VERSION ""

NS_ :

BS_:

BU_: AC_KanBox DRS_MM5_10 NotUsed HYS_EX ABS_M5 DDU10 BCM BSM CDCM DCTM DIAG_TEST ECM IONM IPC ORC RFHM TBM

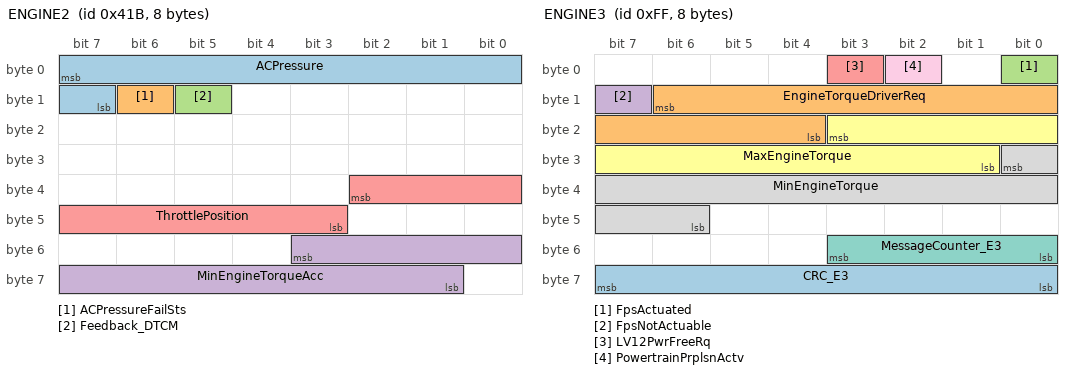
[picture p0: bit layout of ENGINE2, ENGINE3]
BO_ 1051 ENGINE2: 8 ECM
 SG_ ACPressure : 7|9@0+ (0.1,0) [0|40] "bar"  BCM
 SG_ ACPressureFailSts : 14|1@0+ (1,0) [0|1] "-"  BCM
 SG_ Feedback_DTCM : 13|1@0+ (1,0) [0|1] "-" Vector__XXX
 SG_ MinEngineTorqueAcc : 51|11@0+ (1,-500) [-500|1546] "Nm" Vector__XXX
 SG_ ThrottlePosition : 34|8@0+ (0.392,0) [0|99.96] "%"  ORC

BO_ 255 ENGINE3: 8 ECM
 SG_ CRC_E3 : 63|8@0+ (1,0) [0|255] ""  BCM,BSM,CDCM,DCTM
 SG_ EngineTorqueDriverReq : 14|11@0+ (1,-500) [-500|1546] "Nm"  BSM,CDCM,DCTM,ORC
 SG_ FpsActuated : 0|1@0+ (1,0) [0|1] ""  BCM,IPC
 SG_ FpsNotActuable : 15|1@0+ (1,0) [0|1] "-"  BCM
 SG_ LV12PwrFreeRq : 3|1@0+ (1,0) [0|1] ""  DCTM
 SG_ MaxEngineTorque : 19|11@0+ (1,-500) [-500|1546] "Nm"  CDCM,DCTM
 SG_ MessageCounter_E3 : 51|4@0+ (1,0) [0|15] ""  BCM,BSM,CDCM,DCTM
 SG_ MinEngineTorque : 24|11@0+ (1,-500) [-500|1546] "Nm"  DCTM
 SG_ PowertrainPrplsnActv : 2|1@0+ (1,0) [0|1] "-"  BCM,DCTM

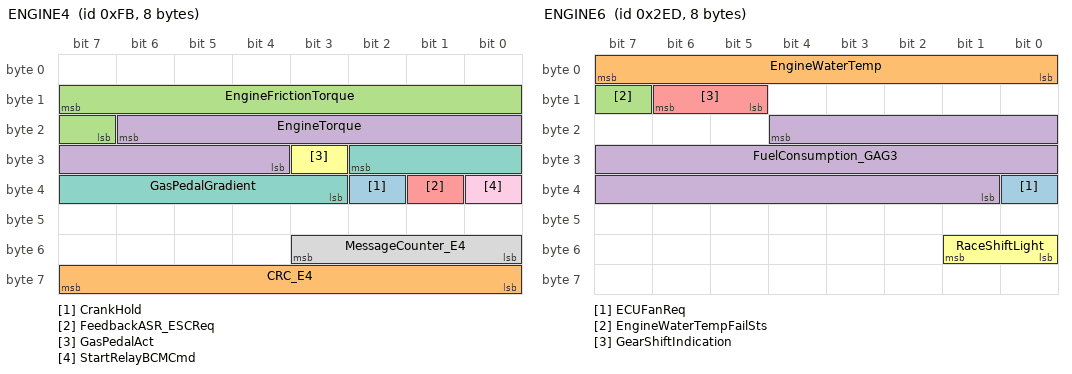
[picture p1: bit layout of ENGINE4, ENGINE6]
BO_ 251 ENGINE4: 8 ECM
 SG_ CrankHold : 34|1@0+ (1,0) [0|1] "-"  BCM,BSM
 SG_ CRC_E4 : 63|8@0+ (1,0) [0|255] ""  BCM,BSM,CDCM,DCTM
 SG_ EngineFrictionTorque : 15|9@0+ (1,0) [0|510] "Nm"  BSM,CDCM,DCTM
 SG_ EngineTorque : 22|11@0+ (1,-500) [-500|1546] "Nm"  BSM,CDCM,DCTM,IPC,ORC,TBM
 SG_ FeedbackASR_ESCReq : 33|1@0+ (1,0) [0|1] "-"  BSM
 SG_ GasPedalAct : 27|1@0+ (1,0) [0|1] "-"  BSM
 SG_ GasPedalGradient : 26|8@0+ (0.195,-25) [-25|24.53] "%/10ms"  CDCM,DCTM
 SG_ MessageCounter_E4 : 51|4@0+ (1,0) [0|15] ""  BCM,BSM,CDCM,DCTM
 SG_ StartRelayBCMCmd : 32|1@0+ (1,0) [0|1] "-"  BCM

BO_ 496 ENGINE5: 8 ECM
 SG_ ActualPedalPos : 4|8@0+ (0.4,0) [0|100] "%"  ORC

BO_ 749 ENGINE6: 8 ECM
 SG_ ECUFanReq : 32|1@1+ (1,0) [0|1] "" Vector__XXX
 SG_ EngineWaterTemp : 7|8@0+ (1,-40) [-40|215] "°C"  BCM,DCTM,IPC,TBM
 SG_ EngineWaterTempFailSts : 15|1@0+ (1,0) [0|1] "-"  BCM,DCTM,IPC,TBM
 SG_ FuelConsumption_GAG3 : 20|20@0+ (0.0022,0) [0|2306.8628] "litres/hour"  BCM,CDCM,IPC,TBM
 SG_ GearShiftIndication : 14|2@0+ (1,0) [0|3] "-"  BCM,CDCM,IPC
 SG_ RaceShiftLight : 49|2@0+ (1,0) [0|3] "-"  IPC

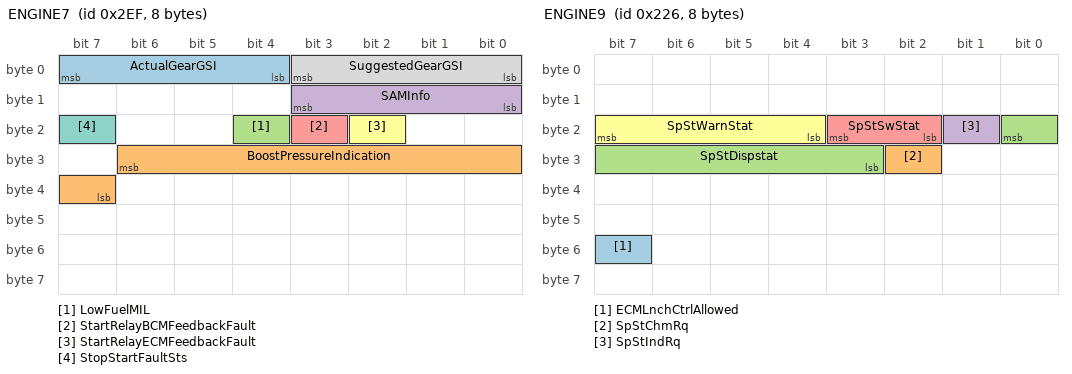
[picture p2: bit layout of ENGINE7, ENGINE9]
BO_ 751 ENGINE7: 8 ECM
 SG_ ActualGearGSI : 7|4@0+ (1,0) [0|15] "-"  CDCM,IPC,ORC
 SG_ BoostPressureIndication : 30|8@0+ (15,0) [0|3825] "mbar"  DDU10,IPC,TBM
 SG_ LowFuelMIL : 20|1@0+ (1,0) [0|1] "" Vector__XXX
 SG_ SAMInfo : 11|4@0+ (1,0) [0|14] "-" Vector__XXX
 SG_ StartRelayBCMFeedbackFault : 19|1@0+ (1,0) [0|1] "-"  BCM
 SG_ StartRelayECMFeedbackFault : 18|1@0+ (1,0) [0|1] "-"  BCM,ORC
 SG_ StopStartFaultSts : 23|1@0+ (1,0) [0|1] "-" Vector__XXX
 SG_ SuggestedGearGSI : 3|4@0+ (1,0) [0|15] "-"  CDCM,IPC

BO_ 550 ENGINE9: 8 ECM
 SG_ ECMLnchCtrlAllowed : 55|1@0+ (1,0) [0|1] ""  DCTM
 SG_ SpStChmRq : 26|1@0+ (1,0) [0|1] "-"  IPC
 SG_ SpStDispstat : 16|6@0+ (1,0) [0|63] "-"  BCM,IPC,TBM
 SG_ SpStIndRq : 17|1@0+ (1,0) [0|1] "-" Vector__XXX
 SG_ SpStSwStat : 19|2@0+ (1,0) [0|3] "-"  BCM,TBM
 SG_ SpStWarnStat : 23|4@0+ (1,0) [0|15] "-"  BCM,IPC

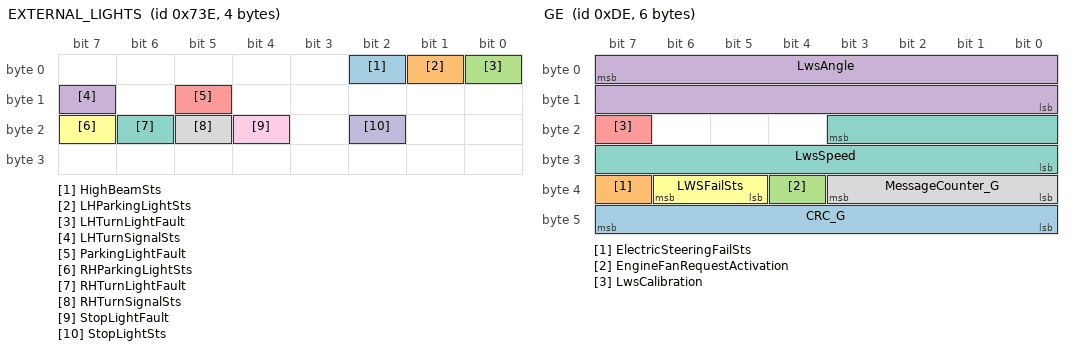
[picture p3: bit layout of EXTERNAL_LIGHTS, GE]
BO_ 1854 EXTERNAL_LIGHTS: 4 NotUsed
 SG_ HighBeamSts : 2|1@0+ (1,0) [0|1] "-"  ORC,TBM
 SG_ LHParkingLightSts : 1|1@0+ (1,0) [0|1] "-"  ORC
 SG_ LHTurnLightFault : 0|1@0+ (1,0) [0|1] "-"  ORC,TBM
 SG_ LHTurnSignalSts : 15|1@0+ (1,0) [0|1] "-"  ORC
 SG_ ParkingLightFault : 13|1@0+ (1,0) [0|1] "-"  ORC
 SG_ RHParkingLightSts : 23|1@0+ (1,0) [0|1] "-"  ORC
 SG_ RHTurnLightFault : 22|1@0+ (1,0) [0|1] "-"  ORC,TBM
 SG_ RHTurnSignalSts : 21|1@0+ (1,0) [0|1] "-"  ORC
 SG_ StopLightFault : 20|1@0+ (1,0) [0|1] "-"  ORC,TBM
 SG_ StopLightSts : 18|1@0+ (1,0) [0|1] "-"  ORC

BO_ 222 GE: 6 DDU10
 SG_ CRC_G : 47|8@0+ (1,0) [0|255] "-"  DCTM
 SG_ ElectricSteeringFailSts : 39|1@0+ (1,0) [0|1] ""  BCM,IPC
 SG_ EngineFanRequestActivation : 36|1@0+ (1,0) [0|1] ""  ECM
 SG_ LwsAngle : 7|16@0+ (0.1,-720) [-720|720] "°"  DCTM,ECM,TBM
 SG_ LwsCalibration : 23|1@0+ (1,0) [0|1] "-"  TBM
 SG_ LWSFailSts : 38|2@0+ (1,0) [0|3] "-"  DCTM
 SG_ LwsSpeed : 19|12@0+ (1,-2000) [-2000|2094] "°/s"  ECM
 SG_ MessageCounter_G : 35|4@0+ (1,0) [0|15] "1"  DCTM

BO_ 2147565809 HP_DIAGNOSTIC_REQUEST_BCM: 8 DIAG_TEST
 SG_ N_PDU : 7|64@0+ (1,0) [0|0] ""  BCM

BO_ 2147553521 HP_DIAGNOSTIC_REQUEST_ECM: 8 DIAG_TEST
 SG_ N_PDU : 7|64@0+ (1,0) [0|0] ""  ECM

BO_ 2147574001 HP_DIAGNOSTIC_REQUEST_IPC: 8 DIAG_TEST
 SG_ N_PDU : 7|64@0+ (1,0) [0|0] "-"  IPC

BO_ 2147600369 HP_DIAGNOSTIC_REQUEST_RFHM: 8 DIAG_TEST
 SG_ N_PDU : 7|64@0+ (1,0) [0|0] ""  RFHM

BO_ 2147600113 HP_DIAGNOSTIC_REQUEST_TBM: 8 DIAG_TEST
 SG_ N_PDU : 7|64@0+ (1,0) [0|0] ""  TBM

BO_ 2147555569 HP_DIAGNOSTIC_REQUEST_TRANS: 8 DIAG_TEST
 SG_ N_PDU : 7|64@0+ (1,0) [0|0] ""  DCTM

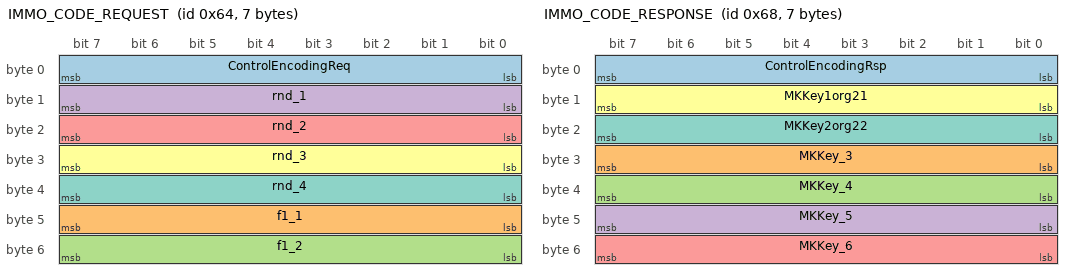
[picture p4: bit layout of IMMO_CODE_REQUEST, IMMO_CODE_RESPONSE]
BO_ 100 IMMO_CODE_REQUEST: 7 ECM
 SG_ ControlEncodingReq : 7|8@0+ (1,0) [0|255] "-"  BCM
 SG_ f1_1 : 47|8@0+ (1,0) [0|255] "-"  BCM
 SG_ f1_2 : 55|8@0+ (1,0) [0|255] "-"  BCM
 SG_ rnd_1 : 15|8@0+ (1,0) [0|255] "-"  BCM
 SG_ rnd_2 : 23|8@0+ (1,0) [0|255] "-"  BCM
 SG_ rnd_3 : 31|8@0+ (1,0) [0|255] "-"  BCM
 SG_ rnd_4 : 39|8@0+ (1,0) [0|255] "-"  BCM

BO_ 104 IMMO_CODE_RESPONSE: 7 BCM
 SG_ ControlEncodingRsp : 7|8@0+ (1,0) [0|255] "-"  ECM
 SG_ MKKey_3 : 31|8@0+ (1,0) [0|255] "-"  ECM
 SG_ MKKey_4 : 39|8@0+ (1,0) [0|255] "-"  ECM
 SG_ MKKey_5 : 47|8@0+ (1,0) [0|255] "-"  ECM
 SG_ MKKey_6 : 55|8@0+ (1,0) [0|255] "-"  ECM
 SG_ MKKey1org21 : 15|8@0+ (1,0) [0|255] "-"  ECM
 SG_ MKKey2org22 : 23|8@0+ (1,0) [0|255] "-"  ECM

BO_ 346 IMPACT_INFO: 4 ORC
 SG_ CRC_II : 31|8@0+ (1,0) [0|255] ""  BCM,TBM
 SG_ IMPACT_A : 4|1@0+ (1,0) [0|1] ""  TBM
 SG_ IMPACT_B : 3|1@0+ (1,0) [0|1] ""  TBM
 SG_ IMPACT_C : 2|1@0+ (1,0) [0|1] ""  TBM
 SG_ IMPACT_D : 1|1@0+ (1,0) [0|1] ""  TBM
 SG_ IMPACT_E : 0|1@0+ (1,0) [0|1] ""  TBM
 SG_ IMPACT_F : 15|1@0+ (1,0) [0|1] ""  TBM
 SG_ IMPACT_G : 14|1@0+ (1,0) [0|1] ""  TBM
 SG_ IMPACT_H : 13|1@0+ (1,0) [0|1] ""  TBM
 SG_ IMPACT_I : 12|1@0+ (1,0) [0|1] ""  TBM
 SG_ IMPACT_K : 11|1@0+ (1,0) [0|1] ""  TBM
 SG_ IMPACT_L : 10|1@0+ (1,0) [0|1] ""  TBM
 SG_ IMPACT_M : 9|1@0+ (1,0) [0|1] ""  TBM
 SG_ IMPACT_O : 8|1@0+ (1,0) [0|1] ""  TBM
 SG_ IMPACTCommand : 6|1@0+ (1,0) [0|1] ""  BCM,ECM
 SG_ IMPACTConfirm : 7|1@0+ (1,0) [0|1] ""  BCM,ECM,TBM
 SG_ IMPACTFailSts : 5|1@0+ (1,0) [0|1] ""  BCM
 SG_ MessageCounter_II : 19|4@0+ (1,0) [0|15] ""  BCM

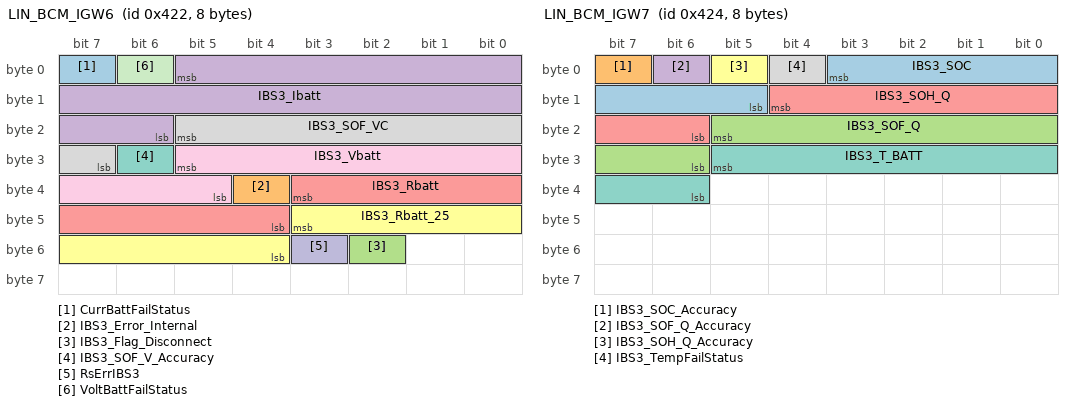
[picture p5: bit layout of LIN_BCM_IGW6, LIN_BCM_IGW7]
BO_ 1058 LIN_BCM_IGW6: 8 DDU10
 SG_ CurrBattFailStatus : 7|1@0+ (1,0) [0|1] "-"  ECM
 SG_ IBS3_Error_Internal : 36|1@0+ (1,0) [0|1] "-"  ECM
 SG_ IBS3_Flag_Disconnect : 50|1@0+ (1,0) [0|1] "-"  ECM
 SG_ IBS3_Ibatt : 5|16@0+ (0.02,-1000) [-1000|310.7] "A"  ECM,TBM
 SG_ IBS3_Rbatt : 35|8@0+ (0.1,0) [0|25.5] "mOhm" Vector__XXX
 SG_ IBS3_Rbatt_25 : 43|8@0+ (0.1,0) [0|25.5] "mOhm" Vector__XXX
 SG_ IBS3_SOF_V_Accuracy : 30|1@0+ (1,0) [0|1] "-"  ECM,IPC
 SG_ IBS3_SOF_VC : 21|7@0+ (0.05,5) [5|11.35] "V"  ECM
 SG_ IBS3_Vbatt : 29|9@0+ (0.025,5) [5|17.775] "V"  ECM,ORC,TBM
 SG_ RsErrIBS3 : 51|1@0+ (1,0) [0|1] "-"  ECM
 SG_ VoltBattFailStatus : 6|1@0+ (1,0) [0|1] "-"  ECM

BO_ 1060 LIN_BCM_IGW7: 8 DDU10
 SG_ IBS3_SOC : 3|7@0+ (1,0) [0|127] "%"  ECM,IPC,ORC,TBM
 SG_ IBS3_SOC_Accuracy : 7|1@0+ (1,0) [0|1] "-"  ECM,IPC,TBM
 SG_ IBS3_SOF_Q : 21|8@0+ (1,0) [0|255] "Ah"  ECM
 SG_ IBS3_SOF_Q_Accuracy : 6|1@0+ (1,0) [0|1] "-"  ECM
 SG_ IBS3_SOH_Q : 12|7@0+ (2,0) [0|254] "Ah"  ECM
 SG_ IBS3_SOH_Q_Accuracy : 5|1@0+ (1,0) [0|1] "-"  ECM
 SG_ IBS3_T_BATT : 29|8@0+ (1,-40) [-40|215] "°C"  ECM
 SG_ IBS3_TempFailStatus : 4|1@0+ (1,0) [0|1] "-"  ECM

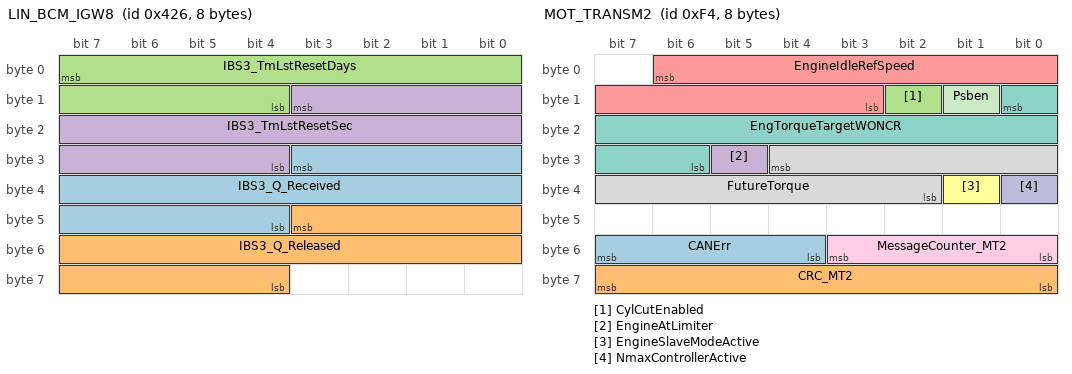
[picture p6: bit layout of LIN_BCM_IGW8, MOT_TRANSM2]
BO_ 1062 LIN_BCM_IGW8: 8 BCM
 SG_ IBS3_Q_Received : 27|16@0+ (0.125,0) [0|8191] "Ah" Vector__XXX
 SG_ IBS3_Q_Released : 43|16@0+ (0.125,0) [0|8191] "Ah" Vector__XXX
 SG_ IBS3_TmLstResetDays : 7|12@0+ (1,0) [0|4094] "Days" Vector__XXX
 SG_ IBS3_TmLstResetSec : 11|16@0+ (2,0) [0|131068] "sec" Vector__XXX

BO_ 256 MOT_TRANSM1: 8 ECM
 SG_ CRC_MT1 : 63|8@0+ (1,0) [0|255] ""  DCTM
 SG_ ECM_LHOM : 7|1@0+ (1,0) [0|1] "-"  DCTM
 SG_ Message_Counter_MT1 : 51|4@0+ (1,0) [0|15] ""  DCTM

BO_ 244 MOT_TRANSM2: 8 ECM
 SG_ CANErr : 55|4@0+ (1,0) [0|15] "-"  DCTM
 SG_ CRC_MT2 : 63|8@0+ (1,0) [0|255] ""  DCTM
 SG_ CylCutEnabled : 10|1@0+ (1,0) [0|1] ""  DCTM
 SG_ EngineAtLimiter : 29|1@0+ (1,0) [0|1] ""  DCTM
 SG_ EngineIdleRefSpeed : 6|12@0+ (1,0) [0|4094] "1/min"  DCTM
 SG_ EngineSlaveModeActive : 33|1@0+ (1,0) [0|1] ""  DCTM
 SG_ EngTorqueTargetWONCR : 8|11@0+ (1,-500) [-500|1546] "Nm"  DCTM
 SG_ FutureTorque : 28|11@0+ (1,-500) [-500|1546] "Nm"  DCTM
 SG_ MessageCounter_MT2 : 51|4@0+ (1,0) [0|15] ""  DCTM
 SG_ NmaxControllerActive : 32|1@0+ (1,0) [0|1] ""  DCTM
 SG_ Psben : 9|1@0+ (1,0) [0|1] "-" Vector__XXX

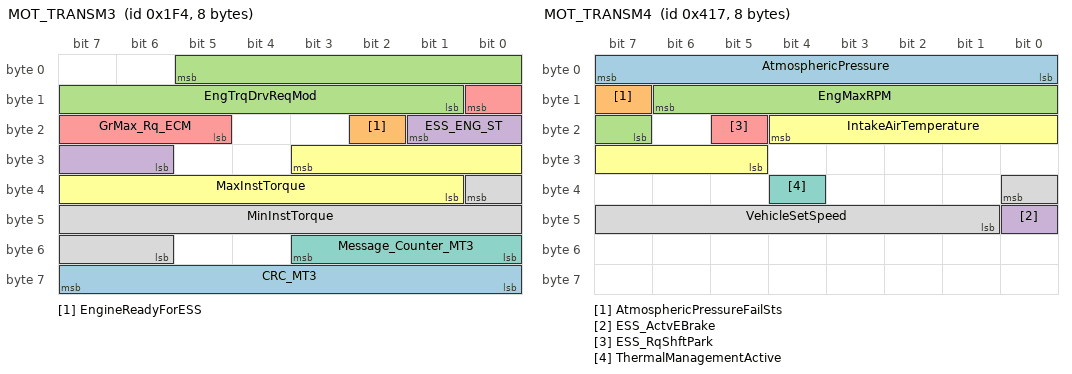
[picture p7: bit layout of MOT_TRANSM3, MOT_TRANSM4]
BO_ 500 MOT_TRANSM3: 8 ECM
 SG_ CRC_MT3 : 63|8@0+ (1,0) [0|255] ""  BCM,BSM,DCTM
 SG_ EngineReadyForESS : 18|1@0+ (1,0) [0|1] "-"  BSM,DCTM
 SG_ EngTrqDrvReqMod : 5|13@0+ (0.25,-500) [-500|1547.5] "Nm"  DCTM
 SG_ ESS_ENG_ST : 17|4@0+ (1,0) [0|15] "-"  BCM,BSM,CDCM,DCTM,ORC,TBM
 SG_ GrMax_Rq_ECM : 8|4@0+ (1,0) [0|15] "-"  DCTM
 SG_ MaxInstTorque : 27|11@0+ (1,-500) [-500|1546] "Nm"  DCTM
 SG_ Message_Counter_MT3 : 51|4@0+ (1,0) [0|15] ""  BCM,BSM,DCTM
 SG_ MinInstTorque : 32|11@0+ (1,-500) [-500|1546] "Nm"  DCTM

BO_ 1047 MOT_TRANSM4: 8 ECM
 SG_ AtmosphericPressure : 7|8@0+ (3.6,300) [300|1214.4] "mbar"  DCTM,ORC,RFHM
 SG_ AtmosphericPressureFailSts : 15|1@0+ (1,0) [0|1] "-"  DCTM,RFHM
 SG_ EngMaxRPM : 14|8@0+ (50,0) [0|10000] "-"  DCTM
 SG_ ESS_ActvEBrake : 40|1@0+ (1,0) [0|1] "-"  BSM
 SG_ ESS_RqShftPark : 21|1@0+ (1,0) [0|1] ""  DCTM
 SG_ IntakeAirTemperature : 20|8@0+ (1,-40) [-40|214] "C"  TBM
 SG_ ThermalManagementActive : 36|1@0+ (1,0) [0|1] "-"  DCTM
 SG_ VehicleSetSpeed : 32|8@0+ (1,0) [0|250] "km/h(mph)"  DCTM

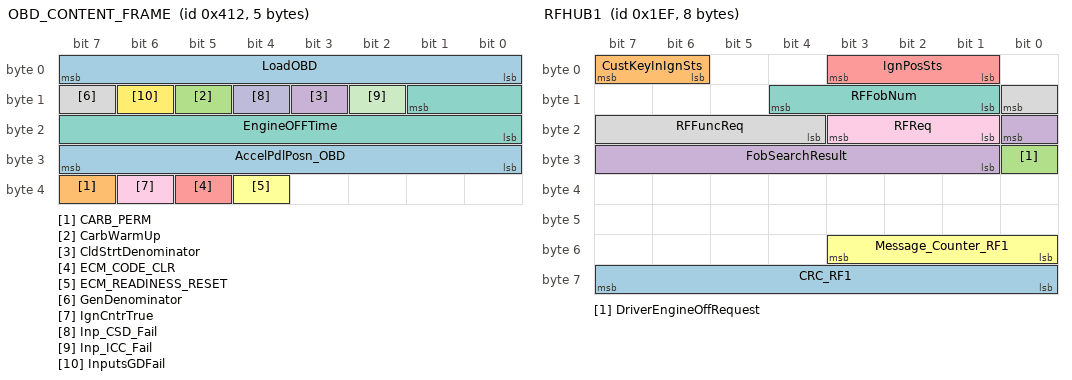
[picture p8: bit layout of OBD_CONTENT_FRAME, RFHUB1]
BO_ 1042 OBD_CONTENT_FRAME: 5 ECM
 SG_ AccelPdlPosn_OBD : 31|8@0+ (0.3922,0) [0|100] "%"  DCTM
 SG_ CARB_PERM : 39|1@0+ (1,0) [0|1] "-"  DCTM
 SG_ CarbWarmUp : 13|1@0+ (1,0) [0|1] "-"  DCTM
 SG_ CldStrtDenominator : 11|1@0+ (1,0) [0|1] "-"  DCTM
 SG_ ECM_CODE_CLR : 37|1@0+ (1,0) [0|1] "-"  DCTM
 SG_ ECM_READINESS_RESET : 36|1@0+ (1,0) [0|1] "-"  DCTM
 SG_ EngineOFFTime : 9|10@0+ (1,0) [0|1022] "min"  DCTM
 SG_ GenDenominator : 15|1@0+ (1,0) [0|1] "-"  DCTM
 SG_ IgnCntrTrue : 38|1@0+ (1,0) [0|1] "-"  DCTM
 SG_ Inp_CSD_Fail : 12|1@0+ (1,0) [0|1] "-"  DCTM
 SG_ Inp_ICC_Fail : 10|1@0+ (1,0) [0|1] "-"  DCTM
 SG_ InputsGDFail : 14|1@0+ (1,0) [0|1] "-"  DCTM
 SG_ LoadOBD : 7|8@0+ (0.3922,0) [0|100] "%"  DCTM,TBM

BO_ 495 RFHUB1: 8 NotUsed
 SG_ CRC_RF1 : 63|8@0+ (1,0) [0|255] ""  BCM
 SG_ CustKeyInIgnSts : 7|2@0+ (1,0) [0|2] ""  BCM
 SG_ DriverEngineOffRequest : 24|1@0+ (1,0) [0|1] ""  BCM
 SG_ FobSearchResult : 16|8@0+ (1,0) [0|255] ""  BCM
 SG_ IgnPosSts : 3|3@0+ (1,0) [0|6] ""  BCM,TBM
 SG_ Message_Counter_RF1 : 51|4@0+ (1,0) [0|15] ""  BCM
 SG_ RFFobNum : 12|4@0+ (1,0) [0|14] ""  BCM
 SG_ RFFuncReq : 8|5@0+ (1,0) [0|31] ""  BCM,TBM
 SG_ RFReq : 19|3@0+ (1,0) [0|6] ""  BCM,TBM

BO_ 2000 RFHUB1_BCM: 1 NotUsed
 SG_ RFFuncReq_BCM : 7|5@0+ (1,0) [0|30] ""  TBM
 SG_ RFReq_BCM : 2|3@0+ (1,0) [0|6] "" Vector__XXX

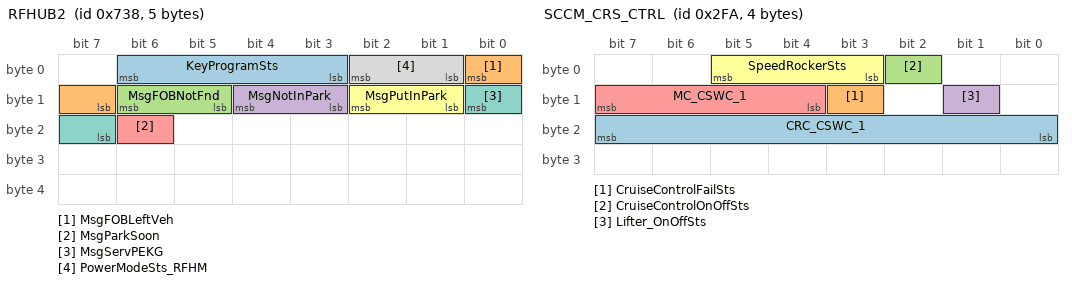
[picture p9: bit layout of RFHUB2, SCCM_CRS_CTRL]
BO_ 1848 RFHUB2: 5 NotUsed
 SG_ KeyProgramSts : 6|4@0+ (1,0) [0|15] ""  IPC
 SG_ MsgFOBLeftVeh : 0|2@0+ (1,0) [0|2] ""  IPC
 SG_ MsgFOBNotFnd : 14|2@0+ (1,0) [0|2] ""  IPC
 SG_ MsgNotInPark : 12|2@0+ (1,0) [0|3] ""  IPC
 SG_ MsgParkSoon : 22|1@0+ (1,0) [0|1] ""  IPC
 SG_ MsgPutInPark : 10|2@0+ (1,0) [0|3] ""  IPC
 SG_ MsgServPEKG : 8|2@0+ (1,0) [0|3] ""  IPC
 SG_ PowerModeSts_RFHM : 2|2@0+ (1,0) [0|3] ""  BCM

BO_ 762 SCCM_CRS_CTRL: 4 NotUsed
 SG_ CRC_CSWC_1 : 23|8@0+ (1,0) [0|255] ""  CDCM,ECM
 SG_ CruiseControlFailSts : 11|1@0+ (1,0) [0|1] ""  ECM,ORC
 SG_ CruiseControlOnOffSts : 2|1@0+ (1,0) [0|1] ""  ECM,ORC,TBM
 SG_ Lifter_OnOffSts : 9|1@0+ (1,0) [0|1] ""  CDCM
 SG_ MC_CSWC_1 : 15|4@0+ (1,0) [0|15] ""  CDCM,ECM
 SG_ SpeedRockerSts : 5|3@0+ (1,0) [0|7] ""  ECM,TBM

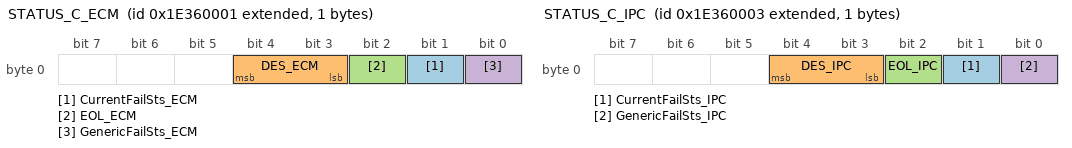
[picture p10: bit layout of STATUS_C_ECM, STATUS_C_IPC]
BO_ 2654339073 STATUS_C_ECM: 1 ECM
 SG_ CurrentFailSts_ECM : 1|1@0+ (1,0) [0|1] "-"  BCM
 SG_ DES_ECM : 4|2@0+ (1,0) [0|2] "-" Vector__XXX
 SG_ EOL_ECM : 2|1@0+ (1,0) [0|1] "-"  BCM
 SG_ GenericFailSts_ECM : 0|1@0+ (1,0) [0|1] "-"  BCM

BO_ 2654339075 STATUS_C_IPC: 1 IPC
 SG_ CurrentFailSts_IPC : 1|1@0+ (1,0) [0|1] "-"  BCM
 SG_ DES_IPC : 4|2@0+ (1,0) [0|2] "-" Vector__XXX
 SG_ EOL_IPC : 2|1@0+ (1,0) [0|1] "-"  BCM
 SG_ GenericFailSts_IPC : 0|1@0+ (1,0) [0|1] "-"  BCM

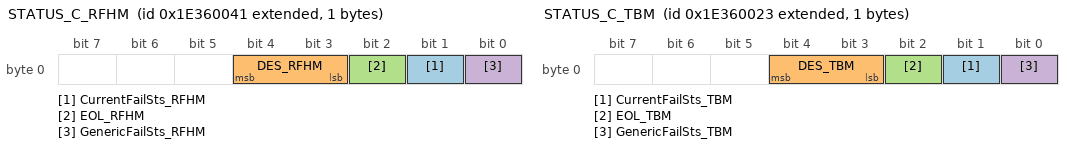
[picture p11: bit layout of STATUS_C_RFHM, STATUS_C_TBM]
BO_ 2654339137 STATUS_C_RFHM: 1 RFHM
 SG_ CurrentFailSts_RFHM : 1|1@0+ (1,0) [0|1] "-"  BCM
 SG_ DES_RFHM : 4|2@0+ (1,0) [0|2] "-" Vector__XXX
 SG_ EOL_RFHM : 2|1@0+ (1,0) [0|1] "-"  BCM
 SG_ GenericFailSts_RFHM : 0|1@0+ (1,0) [0|1] "-"  BCM

BO_ 2654339107 STATUS_C_TBM: 1 TBM
 SG_ CurrentFailSts_TBM : 1|1@0+ (1,0) [0|1] "-"  BCM
 SG_ DES_TBM : 4|2@0+ (1,0) [0|2] "-" Vector__XXX
 SG_ EOL_TBM : 2|1@0+ (1,0) [0|1] "-"  BCM
 SG_ GenericFailSts_TBM : 0|1@0+ (1,0) [0|1] "-"  BCM

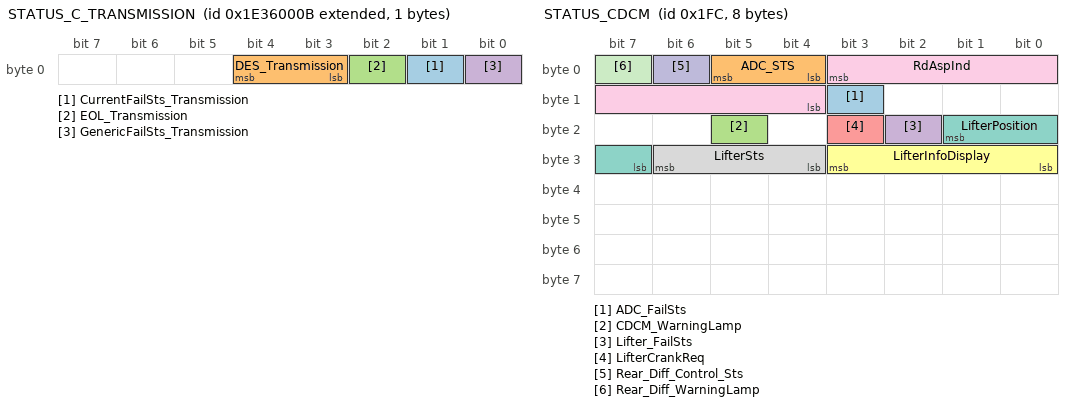
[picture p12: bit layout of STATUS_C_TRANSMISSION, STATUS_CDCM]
BO_ 2654339083 STATUS_C_TRANSMISSION: 1 DCTM
 SG_ CurrentFailSts_Transmission : 1|1@0+ (1,0) [0|1] "-"  BCM
 SG_ DES_Transmission : 4|2@0+ (1,0) [0|2] "-" Vector__XXX
 SG_ EOL_Transmission : 2|1@0+ (1,0) [0|1] "-"  BCM
 SG_ GenericFailSts_Transmission : 0|1@0+ (1,0) [0|1] "-"  BCM

BO_ 508 STATUS_CDCM: 8 NotUsed
 SG_ ADC_FailSts : 11|1@0+ (1,0) [0|1] ""  BCM,IPC
 SG_ ADC_STS : 5|2@0+ (1,0) [0|3] "-"  BCM,IPC
 SG_ CDCM_WarningLamp : 21|1@0+ (1,0) [0|1] ""  IPC
 SG_ Lifter_FailSts : 18|1@0+ (1,0) [0|1] ""  IPC
 SG_ LifterCrankReq : 19|1@0+ (1,0) [0|1] ""  ECM
 SG_ LifterInfoDisplay : 27|4@0+ (1,0) [0|15] ""  IPC
 SG_ LifterPosition : 17|3@0+ (1,0) [0|6] ""  BCM,DCTM,IPC
 SG_ LifterSts : 30|3@0+ (1,0) [0|6] ""  IPC
 SG_ RdAspInd : 3|8@0+ (1,0) [0|255] "-" Vector__XXX
 SG_ Rear_Diff_Control_Sts : 6|1@0+ (1,0) [0|1] "" Vector__XXX
 SG_ Rear_Diff_WarningLamp : 7|1@0+ (1,0) [0|1] ""  IPC

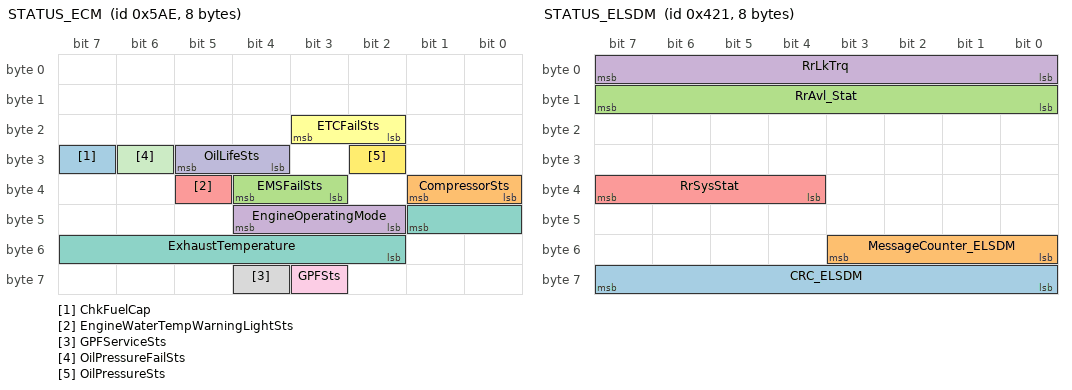
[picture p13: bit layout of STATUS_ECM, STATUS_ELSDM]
BO_ 1454 STATUS_ECM: 8 ECM
 SG_ ChkFuelCap : 31|1@0+ (1,0) [0|1] "-"  IPC,TBM
 SG_ CompressorSts : 33|2@0+ (1,0) [0|3] "-"  BCM,DCTM,TBM
 SG_ EMSFailSts : 36|2@0+ (1,0) [0|3] "-"  BCM,DCTM,IPC,ORC,TBM
 SG_ EngineOperatingMode : 44|3@0+ (1,0) [0|7] "-" Vector__XXX
 SG_ EngineWaterTempWarningLightSts : 37|1@0+ (1,0) [0|1] "-"  BCM,IPC
 SG_ ETCFailSts : 19|2@0+ (1,0) [0|3] "-"  BCM,DCTM,IPC,ORC,TBM
 SG_ ExhaustTemperature : 41|8@0+ (4,0) [0|1020] "°C" Vector__XXX
 SG_ GPFServiceSts : 60|1@0+ (1,0) [0|1] "-"  IPC
 SG_ GPFSts : 59|1@0+ (1,0) [0|1] "-"  IPC
 SG_ OilLifeSts : 29|2@0+ (1,0) [0|3] "-"  BCM,IPC,TBM
 SG_ OilPressureFailSts : 30|1@0+ (1,0) [0|1] "-"  IPC
 SG_ OilPressureSts : 26|1@0+ (1,0) [0|1] "-"  BCM,IPC,TBM

BO_ 1057 STATUS_ELSDM: 8 DCTM
 SG_ CRC_ELSDM : 63|8@0+ (1,0) [0|0] ""  CDCM
 SG_ MessageCounter_ELSDM : 51|4@0+ (1,0) [0|15] ""  CDCM
 SG_ RrAvl_Stat : 15|8@0+ (1,0) [0|100] "%"  BSM,CDCM
 SG_ RrLkTrq : 7|8@0+ (9.96,0) [0|2540] "Nm"  BSM,CDCM
 SG_ RrSysStat : 39|4@0+ (1,0) [0|15] "-"  BSM,CDCM,ORC

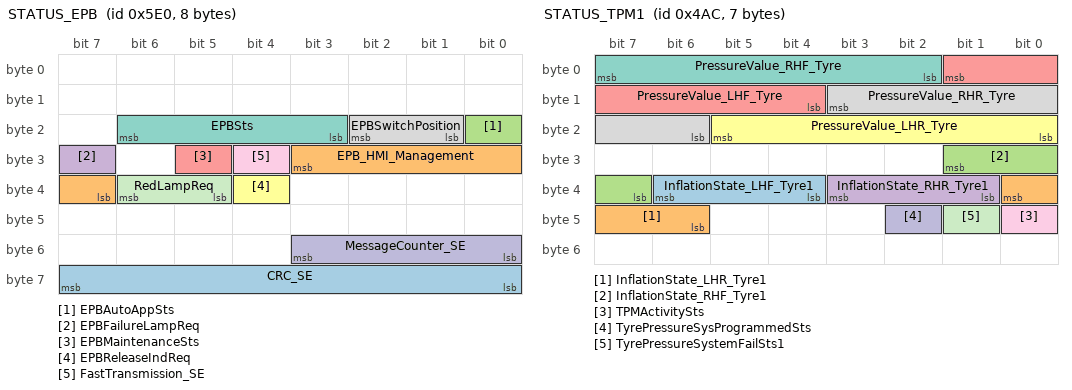
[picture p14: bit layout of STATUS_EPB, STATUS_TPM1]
BO_ 1504 STATUS_EPB: 8 DDU10
 SG_ CRC_SE : 63|8@0+ (1,0) [0|255] ""  BCM,DCTM,ECM
 SG_ EPB_HMI_Management : 27|5@0+ (1,0) [0|31] ""  IPC
 SG_ EPBAutoAppSts : 16|1@0+ (1,0) [0|1] ""  IPC
 SG_ EPBFailureLampReq : 31|1@0+ (1,0) [0|1] ""  IPC,ORC
 SG_ EPBMaintenanceSts : 29|1@0+ (1,0) [0|1] ""  IPC
 SG_ EPBReleaseIndReq : 36|1@0+ (1,0) [0|1] ""  IPC
 SG_ EPBSts : 22|4@0+ (1,0) [0|14] "-"  BCM,DCTM,ECM,ORC,TBM
 SG_ EPBSwitchPosition : 18|2@0+ (1,0) [0|3] ""  ORC
 SG_ FastTransmission_SE : 28|1@0+ (1,0) [0|1] "" Vector__XXX
 SG_ MessageCounter_SE : 51|4@0+ (1,0) [0|15] ""  BCM,DCTM,ECM
 SG_ RedLampReq : 38|2@0+ (1,0) [0|3] ""  IPC,ORC,TBM

BO_ 1196 STATUS_TPM1: 7 RFHM
 SG_ InflationState_LHF_Tyre1 : 38|3@0+ (1,0) [0|4] "-"  BCM,CDCM,IPC,ORC,TBM
 SG_ InflationState_LHR_Tyre1 : 32|3@0+ (1,0) [0|4] "-"  BCM,CDCM,IPC,ORC,TBM
 SG_ InflationState_RHF_Tyre1 : 25|3@0+ (1,0) [0|4] "-"  BCM,CDCM,IPC,ORC,TBM
 SG_ InflationState_RHR_Tyre1 : 35|3@0+ (1,0) [0|4] "-"  BCM,CDCM,IPC,ORC,TBM
 SG_ PressureValue_LHF_Tyre : 1|6@0+ (0.1,0.7) [0.7|7] "bar"  BCM,CDCM,IPC,ORC,TBM
 SG_ PressureValue_LHR_Tyre : 21|6@0+ (0.1,0.7) [0.7|7] "bar"  BCM,CDCM,IPC,ORC,TBM
 SG_ PressureValue_RHF_Tyre : 7|6@0+ (0.1,0.7) [0.7|7] "bar"  BCM,CDCM,IPC,ORC,TBM
 SG_ PressureValue_RHR_Tyre : 11|6@0+ (0.1,0.7) [0.7|7] "bar"  BCM,CDCM,IPC,ORC,TBM
 SG_ TPMActivitySts : 40|1@0+ (1,0) [0|1] "-"  CDCM,IPC,ORC
 SG_ TyrePressureSysProgrammedSts : 42|1@0+ (1,0) [0|1] "-"  CDCM,IPC
 SG_ TyrePressureSystemFailSts1 : 41|1@0+ (1,0) [0|1] "-"  BCM,CDCM,IPC,ORC

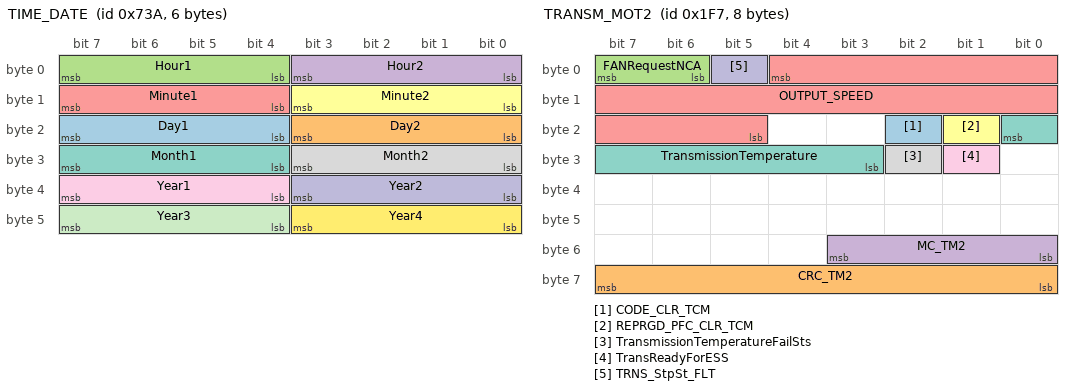
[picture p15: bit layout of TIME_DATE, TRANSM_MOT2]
BO_ 1850 TIME_DATE: 6 NotUsed
 SG_ Day1 : 23|4@0+ (1,0) [0|9] "-"  BCM,DCTM,ECM,RFHM
 SG_ Day2 : 19|4@0+ (1,0) [0|9] "-"  BCM,DCTM,ECM,RFHM
 SG_ Hour1 : 7|4@0+ (1,0) [0|9] "-"  BCM,DCTM,ECM,RFHM
 SG_ Hour2 : 3|4@0+ (1,0) [0|9] "-"  BCM,DCTM,ECM,RFHM
 SG_ Minute1 : 15|4@0+ (1,0) [0|9] "-"  BCM,DCTM,ECM,RFHM
 SG_ Minute2 : 11|4@0+ (1,0) [0|9] "-"  BCM,DCTM,ECM,RFHM
 SG_ Month1 : 31|4@0+ (1,0) [0|9] "-"  BCM,DCTM,ECM,RFHM
 SG_ Month2 : 27|4@0+ (1,0) [0|9] "-"  BCM,DCTM,ECM,RFHM
 SG_ Year1 : 39|4@0+ (1,0) [0|9] "-"  BCM,DCTM,ECM,RFHM
 SG_ Year2 : 35|4@0+ (1,0) [0|9] "-"  BCM,DCTM,ECM,RFHM
 SG_ Year3 : 47|4@0+ (1,0) [0|9] "-"  BCM,DCTM,ECM,RFHM
 SG_ Year4 : 43|4@0+ (1,0) [0|9] "-"  BCM,DCTM,ECM,RFHM

BO_ 503 TRANSM_MOT2: 8 DCTM
 SG_ CODE_CLR_TCM : 18|1@0+ (1,0) [0|1] "-"  ECM
 SG_ CRC_TM2 : 63|8@0+ (1,0) [0|255] "-"  ECM
 SG_ FANRequestNCA : 7|2@0+ (1,0) [0|3] "-"  ECM
 SG_ MC_TM2 : 51|4@0+ (1,0) [0|15] "-"  ECM
 SG_ OUTPUT_SPEED : 4|16@0+ (1,0) [0|65534] "RPM"  ECM,TBM
 SG_ REPRGD_PFC_CLR_TCM : 17|1@0+ (1,0) [0|1] "-"  ECM
 SG_ TransmissionTemperature : 16|6@0+ (3,-40) [-40|149] "°C"  ECM,IPC,TBM
 SG_ TransmissionTemperatureFailSts : 26|1@0+ (1,0) [0|1] "-"  ECM,IPC
 SG_ TransReadyForESS : 25|1@0+ (1,0) [0|1] "-"  ECM
 SG_ TRNS_StpSt_FLT : 5|1@0+ (1,0) [0|1] "-"  ECM

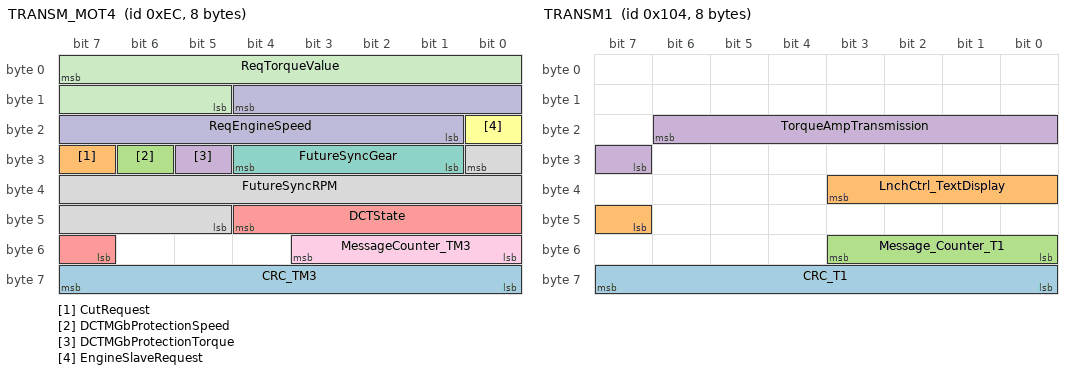
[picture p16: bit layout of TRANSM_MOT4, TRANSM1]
BO_ 236 TRANSM_MOT4: 8 DCTM
 SG_ CRC_TM3 : 63|8@0+ (1,0) [0|225] ""  ECM
 SG_ CutRequest : 31|1@0+ (1,0) [0|1] ""  ECM
 SG_ DCTMGbProtectionSpeed : 30|1@0+ (1,0) [0|1] ""  ECM
 SG_ DCTMGbProtectionTorque : 29|1@0+ (1,0) [0|1] ""  ECM
 SG_ DCTState : 44|6@0+ (1,0) [0|63] ""  ECM
 SG_ EngineSlaveRequest : 16|1@0+ (1,0) [0|1] ""  ECM
 SG_ FutureSyncGear : 28|4@0+ (1,-500) [-500|1546] ""  ECM
 SG_ FutureSyncRPM : 24|12@0+ (5,0) [0|2470] "rev/min"  ECM
 SG_ MessageCounter_TM3 : 51|4@0+ (1,0) [0|15] ""  ECM
 SG_ ReqEngineSpeed : 12|12@0+ (5,0) [0|20470] "rev/min"  ECM,TBM
 SG_ ReqTorqueValue : 7|11@0+ (1,-500) [-500|1546] "Nm"  ECM,TBM

BO_ 260 TRANSM1: 8 DCTM
 SG_ CRC_T1 : 63|8@0+ (1,0) [0|255] "-"  CDCM,ECM
 SG_ LnchCtrl_TextDisplay : 35|5@0+ (1,0) [0|31] "-"  IPC
 SG_ Message_Counter_T1 : 51|4@0+ (1,0) [0|15] ""  CDCM,ECM
 SG_ TorqueAmpTransmission : 22|8@0+ (0.125,0) [0|23.125] "-"  CDCM,TBM

BO_ 1448 TRANSM2: 8 DCTM
 SG_ BuzzerReqSts_T2 : 11|2@0+ (1,0) [0|3] ""  IPC
 SG_ CrankEnable : 7|1@0+ (1,0) [0|1] "-"  ECM,TBM
 SG_ CRC_T2 : 63|8@0+ (1,0) [0|255] "count"  BCM,BSM,CDCM,ECM,IPC,RFHM
 SG_ DriveModeSts : 38|4@0+ (1,0) [0|7] "-"  ECM,TBM
 SG_ GearEngaged : 26|4@0+ (1,0) [0|15] "-"  BCM,BSM,CDCM,ECM,IPC,ORC,TBM
 SG_ GearIndicationSts : 9|1@0+ (1,0) [0|1] "-"  IPC
 SG_ LeverPosition : 8|4@0+ (1,0) [0|15] "-"  ECM
 SG_ LimpHomeSts : 6|1@0+ (1,0) [0|1] "-"  ECM,ORC
 SG_ Message_Counter_T2 : 51|4@0+ (1,0) [0|15] ""  BCM,BSM,CDCM,ECM,IPC,RFHM
 SG_ MIReq : 5|1@0+ (1,0) [0|1] "-"  ECM
 SG_ OilTemperatureSts : 20|1@0+ (1,0) [0|1] "-"  IPC,TBM
 SG_ ParkingFailSts : 3|1@0+ (1,0) [0|1] "-"  TBM
 SG_ ShiftInProgress : 19|1@0+ (1,0) [0|1] "-"  BSM,CDCM,TBM
 SG_ ShiftLeverPosition : 17|4@0+ (1,0) [0|15] "-"  BCM,BSM,CDCM,ECM,IPC,ORC,RFHM,TBM
 SG_ ShiftModeSts : 28|1@0+ (1,0) [0|1] "-"  BCM,ECM,IPC,TBM
 SG_ TargetGear : 34|4@0+ (1,0) [0|15] "-"  CDCM,ECM,IPC,TBM
 SG_ TempManualOverride : 41|1@0+ (1,0) [0|1] "-"  ECM
 SG_ TemporaryManualSts : 42|1@0+ (1,0) [0|1] "-"  ECM,IPC
 SG_ TransmissionFailSts : 12|1@0+ (1,0) [0|1] ""  BCM,ECM,IPC,ORC
 SG_ TransmissionWarnings : 2|6@0+ (1,0) [0|58] "-"  ECM,IPC,TBM
 SG_ TxDisengaged : 46|1@0+ (1,0) [0|1] "-" Vector__XXX

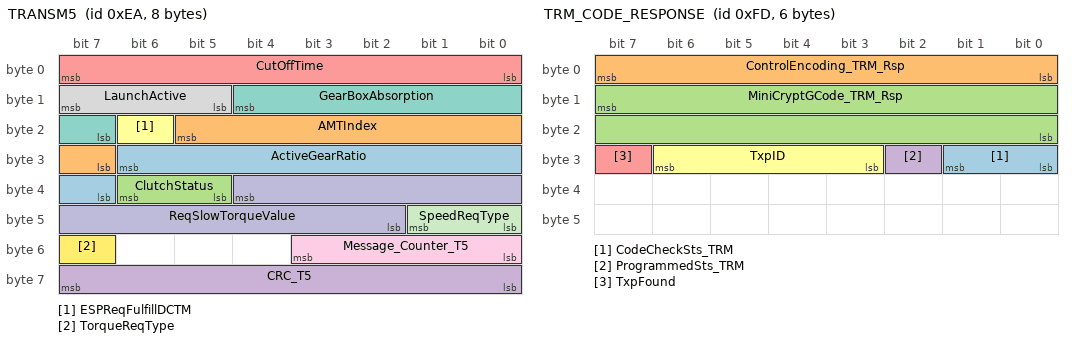
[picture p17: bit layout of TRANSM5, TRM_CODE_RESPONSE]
BO_ 234 TRANSM5: 8 DCTM
 SG_ ActiveGearRatio : 30|8@0+ (0.09,0) [0|22.86] ""  ECM
 SG_ AMTIndex : 21|7@0+ (1,0) [0|126] "%"  ECM
 SG_ ClutchStatus : 38|2@0+ (1,0) [0|3] ""  ECM
 SG_ CRC_T5 : 63|8@0+ (1,0) [0|255] "count"  BSM,ECM
 SG_ CutOffTime : 7|8@0+ (5,0) [0|1270] "ms"  ECM
 SG_ ESPReqFulfillDCTM : 22|1@0+ (1,0) [0|1] ""  ECM
 SG_ GearBoxAbsorption : 12|6@0+ (1,0) [0|62] ""  ECM
 SG_ LaunchActive : 15|3@0+ (1,0) [0|7] ""  BSM,ECM,IPC
 SG_ Message_Counter_T5 : 51|4@0+ (1,0) [0|15] ""  BSM,ECM
 SG_ ReqSlowTorqueValue : 36|11@0+ (1,-500) [-500|1546] "Nm"  ECM,TBM
 SG_ SpeedReqType : 41|2@0+ (1,0) [0|3] ""  ECM,TBM
 SG_ TorqueReqType : 55|1@0+ (1,0) [0|1] ""  ECM,TBM

BO_ 253 TRM_CODE_RESPONSE: 6 RFHM
 SG_ CodeCheckSts_TRM : 25|2@0+ (1,0) [0|3] "-"  BCM
 SG_ ControlEncoding_TRM_Rsp : 7|8@0+ (1,0) [0|255] "-"  BCM
 SG_ MiniCryptGCode_TRM_Rsp : 15|16@0+ (1,0) [0|65535] ""  BCM
 SG_ ProgrammedSts_TRM : 26|1@0+ (1,0) [0|1] "-"  BCM
 SG_ TxpFound : 31|1@0+ (1,0) [0|1] "-"  BCM
 SG_ TxpID : 30|4@0+ (1,0) [0|15] "-"  BCM

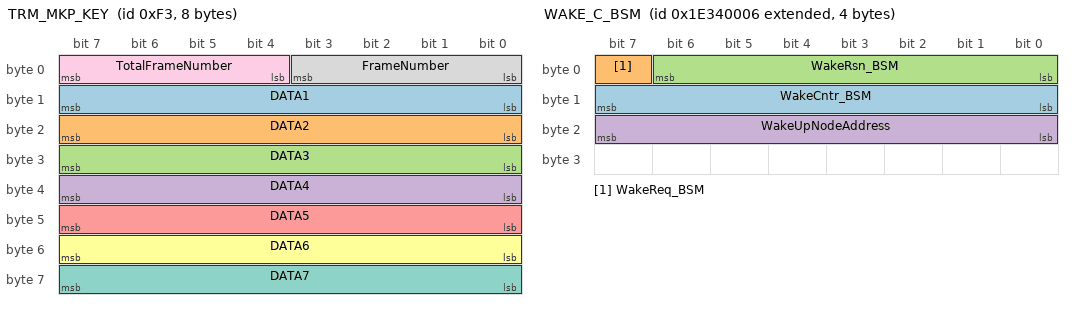
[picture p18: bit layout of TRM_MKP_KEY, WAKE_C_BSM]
BO_ 243 TRM_MKP_KEY: 8 RFHM
 SG_ DATA1 : 15|8@0+ (1,0) [0|255] ""  BCM
 SG_ DATA2 : 23|8@0+ (1,0) [0|255] ""  BCM
 SG_ DATA3 : 31|8@0+ (1,0) [0|255] ""  BCM
 SG_ DATA4 : 39|8@0+ (1,0) [0|255] ""  BCM
 SG_ DATA5 : 47|8@0+ (1,0) [0|255] ""  BCM
 SG_ DATA6 : 55|8@0+ (1,0) [0|255] ""  BCM
 SG_ DATA7 : 63|8@0+ (1,0) [0|255] ""  BCM
 SG_ FrameNumber : 3|4@0+ (1,0) [0|15] "-"  BCM
 SG_ TotalFrameNumber : 7|4@0+ (1,0) [0|15] "-"  BCM

BO_ 1046 VIN: 8 DDU10
 SG_ VIN_DATA : 15|56@0+ (1,0) [0|7.20575940379279E+016] ""  DCTM,ECM,IPC,ORC,RFHM
 SG_ VIN_MSG : 1|2@0+ (1,0) [0|3] ""  DCTM,ECM,IPC,ORC,RFHM

BO_ 2654208000 WAKE_C_BCM: 8 NotUsed
 SG_ MainWakeSts_BCM : 7|1@0+ (1,0) [0|1] "-"  BSM,DCTM,IPC,RFHM,TBM
 SG_ Node0 : 40|1@0+ (1,0) [0|1] "-"  BSM,DCTM,IPC,RFHM,TBM
 SG_ Node1 : 41|1@0+ (1,0) [0|1] "-"  BSM,DCTM,IPC,RFHM,TBM
 SG_ Node10 : 34|1@0+ (1,0) [0|1] "-"  BSM,DCTM,IPC,RFHM,TBM
 SG_ Node11 : 35|1@0+ (1,0) [0|1] "-"  BSM,DCTM,IPC,RFHM,TBM
 SG_ Node12 : 36|1@0+ (1,0) [0|1] "-"  BSM,DCTM,IPC,RFHM,TBM
 SG_ Node13 : 37|1@0+ (1,0) [0|1] "-"  BSM,DCTM,IPC,RFHM,TBM
 SG_ Node14 : 38|1@0+ (1,0) [0|1] "-"  BSM,DCTM,IPC,RFHM,TBM
 SG_ Node15 : 39|1@0+ (1,0) [0|1] "-"  BSM,DCTM,IPC,RFHM,TBM
 SG_ Node16 : 24|1@0+ (1,0) [0|1] "-"  BSM,DCTM,IPC,RFHM,TBM
 SG_ Node17 : 25|1@0+ (1,0) [0|1] "-"  BSM,DCTM,IPC,RFHM,TBM
 SG_ Node18 : 26|1@0+ (1,0) [0|1] "-"  BSM,DCTM,IPC,RFHM,TBM
 SG_ Node19 : 27|1@0+ (1,0) [0|1] "-"  BSM,DCTM,IPC,RFHM,TBM
 SG_ Node2 : 42|1@0+ (1,0) [0|1] "-"  BSM,DCTM,IPC,RFHM,TBM
 SG_ Node20 : 28|1@0+ (1,0) [0|1] "-"  BSM,DCTM,IPC,RFHM,TBM
 SG_ Node21 : 29|1@0+ (1,0) [0|1] "-"  BSM,DCTM,IPC,RFHM,TBM
 SG_ Node22 : 30|1@0+ (1,0) [0|1] "-"  BSM,DCTM,IPC,RFHM,TBM
 SG_ Node23 : 31|1@0+ (1,0) [0|1] "-"  BSM,DCTM,IPC,RFHM,TBM
 SG_ Node24 : 16|1@0+ (1,0) [0|1] "-"  BSM,DCTM,IPC,RFHM,TBM
 SG_ Node25 : 17|1@0+ (1,0) [0|1] "-"  BSM,DCTM,IPC,RFHM,TBM
 SG_ Node26 : 18|1@0+ (1,0) [0|1] "-"  BSM,DCTM,IPC,RFHM,TBM
 SG_ Node27 : 19|1@0+ (1,0) [0|1] "-"  BSM,DCTM,IPC,RFHM,TBM
 SG_ Node28 : 20|1@0+ (1,0) [0|1] "-"  BSM,DCTM,IPC,RFHM,TBM
 SG_ Node29 : 21|1@0+ (1,0) [0|1] "-"  BSM,DCTM,IPC,RFHM,TBM
 SG_ Node3 : 43|1@0+ (1,0) [0|1] "-"  BSM,DCTM,IPC,RFHM,TBM
 SG_ Node30 : 22|1@0+ (1,0) [0|1] "-"  BSM,DCTM,IPC,RFHM,TBM
 SG_ Node31 : 23|1@0+ (1,0) [0|1] "-"  BSM,DCTM,IPC,RFHM,TBM
 SG_ Node4 : 44|1@0+ (1,0) [0|1] "-"  BSM,DCTM,IPC,RFHM,TBM
 SG_ Node5 : 45|1@0+ (1,0) [0|1] "-"  BSM,DCTM,IPC,RFHM,TBM
 SG_ Node6 : 46|1@0+ (1,0) [0|1] "-"  BSM,DCTM,IPC,RFHM,TBM
 SG_ Node7 : 47|1@0+ (1,0) [0|1] "-"  BSM,DCTM,IPC,RFHM,TBM
 SG_ Node8 : 32|1@0+ (1,0) [0|1] "-"  BSM,DCTM,IPC,RFHM,TBM
 SG_ Node9 : 33|1@0+ (1,0) [0|1] "-"  BSM,DCTM,IPC,RFHM,TBM
 SG_ WakeCntr_BCM : 15|8@0+ (1,0) [0|255] "-" Vector__XXX
 SG_ WakeRsn_BCM : 6|7@0+ (1,0) [0|127] "-" Vector__XXX

BO_ 2654208006 WAKE_C_BSM: 4 NotUsed
 SG_ WakeCntr_BSM : 15|8@0+ (1,0) [0|255] "" Vector__XXX
 SG_ WakeReq_BSM : 7|1@0+ (1,0) [0|1] ""  BCM
 SG_ WakeRsn_BSM : 6|7@0+ (1,0) [0|127] "" Vector__XXX
 SG_ WakeUpNodeAddress : 23|8@0+ (1,0) [0|255] ""  BCM

BO_ 2654208003 WAKE_C_IPC: 4 IPC
 SG_ WakeCntr_IPC : 15|8@0+ (1,0) [0|255] "" Vector__XXX
 SG_ WakeReq_IPC : 7|1@0+ (1,0) [0|1] ""  BCM
 SG_ WakeRsn_IPC : 6|7@0+ (1,0) [0|127] "" Vector__XXX
 SG_ WakeUpNodeAddress : 23|8@0+ (1,0) [0|255] ""  BCM

BO_ 2654208065 WAKE_C_RFHM: 4 RFHM
 SG_ WakeCntr_RFHM : 15|8@0+ (1,0) [0|255] "" Vector__XXX
 SG_ WakeReq_RFHM : 7|1@0+ (1,0) [0|1] ""  BCM
 SG_ WakeRsn_RFHM : 6|7@0+ (1,0) [0|127] "" Vector__XXX
 SG_ WakeUpNodeAddress : 23|8@0+ (1,0) [0|255] ""  BCM

BO_ 2654208011 WAKE_C_TRANSMISSION: 4 DCTM
 SG_ WakeCntr_Transmission : 15|8@0+ (1,0) [0|255] "" Vector__XXX
 SG_ WakeReq_Transmission : 7|1@0+ (1,0) [0|1] ""  BCM
 SG_ WakeRsn_Transmission : 6|7@0+ (1,0) [0|127] "" Vector__XXX
 SG_ WakeUpNodeAddress : 23|8@0+ (1,0) [0|255] ""  BCM

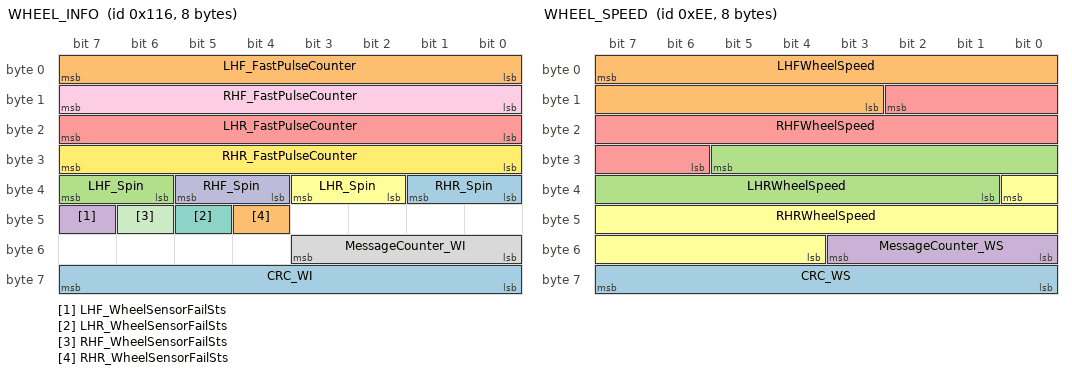
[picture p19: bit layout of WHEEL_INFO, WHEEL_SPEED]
BO_ 278 WHEEL_INFO: 8 DDU10
 SG_ CRC_WI : 63|8@0+ (1,0) [0|255] "-"  CDCM,DCTM,RFHM
 SG_ LHF_FastPulseCounter : 7|8@0+ (1,0) [0|255] "pulse"  BCM,RFHM
 SG_ LHF_Spin : 39|2@0+ (1,0) [0|3] "-"  BCM,CDCM,DCTM,TBM
 SG_ LHF_WheelSensorFailSts : 47|1@0+ (1,0) [0|1] "-"  ECM,BCM,CDCM,DCTM,RFHM
 SG_ LHR_FastPulseCounter : 23|8@0+ (1,0) [0|255] "pulse"  BCM,ORC,RFHM,TBM
 SG_ LHR_Spin : 35|2@0+ (1,0) [0|3] "-"  BCM,CDCM,DCTM,TBM
 SG_ LHR_WheelSensorFailSts : 45|1@0+ (1,0) [0|1] "-"  ECM,BCM,CDCM,DCTM,RFHM
 SG_ MessageCounter_WI : 51|4@0+ (1,0) [0|15] "-"  CDCM,DCTM,RFHM
 SG_ RHF_FastPulseCounter : 15|8@0+ (1,0) [0|255] "pulse"  BCM,RFHM
 SG_ RHF_Spin : 37|2@0+ (1,0) [0|3] "-"  BCM,CDCM,DCTM,TBM
 SG_ RHF_WheelSensorFailSts : 46|1@0+ (1,0) [0|1] "-"  ECM,BCM,CDCM,DCTM,RFHM
 SG_ RHR_FastPulseCounter : 31|8@0+ (1,0) [0|255] "pulse"  BCM,ORC,RFHM,TBM
 SG_ RHR_Spin : 33|2@0+ (1,0) [0|3] "-"  BCM,CDCM,DCTM,TBM
 SG_ RHR_WheelSensorFailSts : 44|1@0+ (1,0) [0|1] "-"  ECM,BCM,CDCM,DCTM,RFHM

BO_ 238 WHEEL_SPEED: 8 DDU10
 SG_ CRC_WS : 63|8@0+ (1,0) [0|255] ""  CDCM,DCTM,ECM,RFHM
 SG_ LHFWheelSpeed : 7|13@0+ (0.0625,0) [0|511.875] "Km/h"  CDCM,DCTM,ECM,ORC,RFHM,TBM
 SG_ LHRWheelSpeed : 29|13@0+ (0.0625,0) [0|511.875] "Km/h"  CDCM,DCTM,ECM,ORC,RFHM,TBM
 SG_ MessageCounter_WS : 51|4@0+ (1,0) [0|15] ""  CDCM,DCTM,ECM,RFHM
 SG_ RHFWheelSpeed : 10|13@0+ (0.0625,0) [0|511.875] "Km/h"  CDCM,DCTM,ECM,ORC,RFHM,TBM
 SG_ RHRWheelSpeed : 32|13@0+ (0.0625,0) [0|511.875] "Km/h"  CDCM,DCTM,ECM,ORC,RFHM,TBM

BO_TX_BU_ 751 : DDU10,ECM;
CM_ SG_ 1051 ACPressure "It indicates air conditioning pressure read from the AC linear pressure sensor.";
CM_ SG_ 1051 ACPressureFailSts "This signal indicates if the ACpressure sensor is in fail.";
CM_ SG_ 1051 Feedback_DTCM "It is set to Not Valid, when the plausibility conditions about DTCM torque request are not fulfilled";
CM_ SG_ 1051 MinEngineTorqueAcc "This signal provide information on the minimum torque that the engine can produce at minimum AirFlow and minimum spark advance.";
CM_ SG_ 1051 ThrottlePosition "GASOLINE APPLICATION ONLY This signal represents throttle position evaluated on the basis of throttle position sensor.";
CM_ SG_ 255 PowertrainPrplsnActv "This signal indicates the Powertrain Propulsion Status";
CM_ SG_ 251 CrankHold "Used by ECM to command an action to the BCM cranking relay during cranking phase";
CM_ SG_ 251 FeedbackASR_ESCReq "It is set to Not Valid, when the plausibility conditions about ASR / ESC torque request are not fulfilled . Nevertheless, it shall not be set to Not Valid, due to ValidData bits Not Valid transmitted from BSM.";
CM_ SG_ 251 StartRelayBCMCmd "Used by ECM to command an action to the BCM cranking relay.";
CM_ SG_ 496 ActualPedalPos "Actual pedal position.";
CM_ SG_ 749 FuelConsumption_GAG3 "It represents istantaneous consumption information";
CM_ SG_ 749 GearShiftIndication "It gives indication of gear shifting";
CM_ SG_ 749 RaceShiftLight "This signal is use to indicate the Shift light urgency to IPC.";
CM_ SG_ 751 ActualGearGSI "It gives indication of Actual gear";
CM_ SG_ 751 BoostPressureIndication "This signal represents the boost pressure indication measured by boost pressure sensor";
CM_ SG_ 751 LowFuelMIL "This signal is used to indicate a Low Fuel MIL indication activation";
CM_ SG_ 751 SuggestedGearGSI "It gives indication of Suggested gear";
CM_ SG_ 550 ECMLnchCtrlAllowed "This signal indicates when ECM ready to Launch";
CM_ SG_ 550 SpStChmRq "Stop start chime request";
CM_ SG_ 550 SpStDispstat "Stop start display status";
CM_ SG_ 550 SpStIndRq "Stop start indicator request";
CM_ SG_ 550 SpStSwStat "Stop start switch status";
CM_ SG_ 550 SpStWarnStat "Stop start warning status";
CM_ SG_ 1854 StopLightSts "Request of Stop Lights activation";
CM_ SG_ 222 CRC_G "CRC according to SAE J1850 standard that has to be calculated at each frame transmission.";
CM_ SG_ 222 ElectricSteeringFailSts "It indicates if system EPS has an internal fault.";
CM_ SG_ 222 EngineFanRequestActivation "This signal is used to activate the cooling fun by the electric power steering.";
CM_ SG_ 222 LwsAngle "This signal indicates the steering angle value, counterclockwise positive.";
CM_ SG_ 222 LwsCalibration "This signal indicates if the sensor has been calibrated and therefore the steering angle value is exported over Can.";
CM_ SG_ 222 LWSFailSts "This signal indicates steering angle export function failure status.";
CM_ SG_ 222 LwsSpeed "This signal indicates the steering speed value, counterclockwise positive.";
CM_ SG_ 222 MessageCounter_G "This signal is a message counter.  Every time a new message is sent by the node, this value is incremented.";
CM_ SG_ 2147565809 N_PDU "This signal is used for diagnostic purposes";
CM_ SG_ 2147553521 N_PDU "This signal is used for diagnostic purposes";
CM_ SG_ 2147574001 N_PDU "-";
CM_ SG_ 2147600369 N_PDU "This signal is used for diagnostic purposes";
CM_ SG_ 2147600113 N_PDU "This signal is used for diagnostic purposes";
CM_ SG_ 2147555569 N_PDU "This signal is used for diagnostic purposes";
CM_ SG_ 100 ControlEncodingReq "This signal is used for IMMO communication";
CM_ SG_ 100 f1_1 "This signal is used for IMMO communication";
CM_ SG_ 100 f1_2 "This signal is used for IMMO communication";
CM_ SG_ 100 rnd_1 "This signal is used for IMMO communication";
CM_ SG_ 100 rnd_2 "This signal is used for IMMO communication";
CM_ SG_ 100 rnd_3 "This signal is used for IMMO communication";
CM_ SG_ 100 rnd_4 "This signal is used for IMMO communication";
CM_ SG_ 104 ControlEncodingRsp "This signal is used for IMMO communication";
CM_ SG_ 104 MKKey_3 "This signal is used for IMMO communication";
CM_ SG_ 104 MKKey_4 "This signal is used for IMMO communication";
CM_ SG_ 104 MKKey_5 "This signal is used for IMMO communication";
CM_ SG_ 104 MKKey_6 "This signal is used for IMMO communication";
CM_ SG_ 104 MKKey1org21 "This signal is used for IMMO communication";
CM_ SG_ 104 MKKey2org22 "This signal is used for IMMO communication";
CM_ SG_ 346 CRC_II "CRC according to SAE J1850 standard that has to be calculated from bit 63 to bit 8 at each frame transmission.";
CM_ SG_ 346 IMPACT_A "Front Pretensioner Event";
CM_ SG_ 346 IMPACT_B "EARS Rear Event";
CM_ SG_ 346 IMPACT_C "EARS Higher Severity Front Event";
CM_ SG_ 346 IMPACT_D "Less Severe Side Event";
CM_ SG_ 346 IMPACT_E "Rear Event";
CM_ SG_ 346 IMPACT_F "EARS Lower Severity Front Event";
CM_ SG_ 346 IMPACT_G "Not Used";
CM_ SG_ 346 IMPACT_H "Non-EARS RolloverEvent";
CM_ SG_ 346 IMPACT_I "EARS RolloverEvent";
CM_ SG_ 346 IMPACT_K "EARS Driver/Left Side Event";
CM_ SG_ 346 IMPACT_L "EARS Side Event";
CM_ SG_ 346 IMPACT_M "EARS Passenger/Right Side Event";
CM_ SG_ 346 IMPACT_O "Pedestrain Crash Event";
CM_ SG_ 346 IMPACTCommand "This signal is used to indicate that a crash happened";
CM_ SG_ 346 IMPACTConfirm "This signal is used to confirm that a crash happened";
CM_ SG_ 346 IMPACTFailSts "This signal is used to inform that an internal fault is present in the ORC";
CM_ SG_ 346 MessageCounter_II "This signal is a counter used for safety checks strategies. This counter is incremented of 1 (one) unit at each frame transmission.";
CM_ SG_ 1058 CurrBattFailStatus "Signal about the IBS3";
CM_ SG_ 1058 IBS3_Error_Internal "Signal about the IBS3";
CM_ SG_ 1058 IBS3_Flag_Disconnect "Signal about the IBS3";
CM_ SG_ 1058 IBS3_Ibatt "Signal about the IBS3";
CM_ SG_ 1058 IBS3_Rbatt "Signal about the IBS3";
CM_ SG_ 1058 IBS3_Rbatt_25 "Signal about the IBS3";
CM_ SG_ 1058 IBS3_SOF_V_Accuracy "Signal about the IBS3";
CM_ SG_ 1058 IBS3_SOF_VC "Signal about the IBS3";
CM_ SG_ 1058 IBS3_Vbatt "Signal about the IBS3";
CM_ SG_ 1058 RsErrIBS3 "Signal about the IBS3";
CM_ SG_ 1058 VoltBattFailStatus "Signal about the IBS3";
CM_ SG_ 1060 IBS3_SOC "Signal about the IBS3";
CM_ SG_ 1060 IBS3_SOC_Accuracy "Signal about the IBS3";
CM_ SG_ 1060 IBS3_SOF_Q "Signal about the IBS3";
CM_ SG_ 1060 IBS3_SOF_Q_Accuracy "Signal about the IBS3";
CM_ SG_ 1060 IBS3_SOH_Q "Signal about the IBS3";
CM_ SG_ 1060 IBS3_SOH_Q_Accuracy "Signal about the IBS3";
CM_ SG_ 1060 IBS3_T_BATT "Signal about the IBS3";
CM_ SG_ 1060 IBS3_TempFailStatus "Signal about the IBS3";
CM_ SG_ 1062 IBS3_Q_Received "Signal about the IBS3";
CM_ SG_ 1062 IBS3_Q_Released "Signal about the IBS3";
CM_ SG_ 1062 IBS3_TmLstResetDays "Signal about the IBS3";
CM_ SG_ 1062 IBS3_TmLstResetSec "Signal about the IBS3";
CM_ SG_ 244 CANErr "This is a feedback on the status of communication between ECM and DCTM.
There are 4 possible cases:
A. No CAN message received from DCTM (time out).
B. Unplausible message
C. Unplausible command
D. Not used.";
CM_ SG_ 244 CylCutEnabled "Fuel cut strategy enable flag. Informs the gearbox that one or more cylinders are currently in fuel cut-off.";
CM_ SG_ 244 EngineAtLimiter "Informs the gearbox that the engine speed limiter is currently active.";
CM_ SG_ 244 EngineIdleRefSpeed "This signal represents target of engine speed for the idle control function, at the end of dynamic transient conditions. It takes into account changes of idle speed due to temperature and auxiliary loads. It is updated even when the engine is ou(...)";
CM_ SG_ 244 EngineSlaveModeActive "Acknowledge of the slave mode by the ECM.";
CM_ SG_ 244 FutureTorque "Driver torque which will be active in the target gear/target speed during gearshift/pullaway.";
CM_ SG_ 244 NmaxControllerActive "Acknowledge of max engine speed limitation from the ECM.";
CM_ SG_ 244 Psben "This signal indicate inhibition of gear shift down";
CM_ SG_ 500 EngineReadyForESS "ESS request HIS charget (1=do charge)";
CM_ SG_ 500 GrMax_Rq_ECM "Target gear upper limit (ECM requested limit)";
CM_ SG_ 500 MaxInstTorque "Maximum torque currently deliverable by the engine through spark advance control";
CM_ SG_ 500 MinInstTorque "Minimum torque currently deliverable by the engine through spark advance control";
CM_ SG_ 1047 ESS_ActvEBrake "Stop start system requests shifting to park";
CM_ SG_ 1042 AccelPdlPosn_OBD "Pedal value for OBD (ISO 15031-5.4 PID 49)";
CM_ SG_ 1042 CARB_PERM "Fault code for diagnostics.";
CM_ SG_ 1042 CarbWarmUp "CARB warmup criteria true.  The engine controller will set this bit when the engine coolant temp achieves the CARB warm-up criteria.";
CM_ SG_ 1042 CldStrtDenominator "Cold start denominator conditions are met [1]";
CM_ SG_ 1042 ECM_CODE_CLR "Handshake for not clear";
CM_ SG_ 1042 ECM_READINESS_RESET "Handshake for not set";
CM_ SG_ 1042 EngineOFFTime "The number of minutes the engine was off.";
CM_ SG_ 1042 GenDenominator "General denominator conditions are met.  The engine controller will set this bit when the conditions for setting the General Denominator are met for rate based diagnostics.";
CM_ SG_ 1042 IgnCntrTrue "Ignition cycle counter is true [1]";
CM_ SG_ 1042 Inp_CSD_Fail "Inputs to the cold start denominator are in a pend or MIL fault.";
CM_ SG_ 1042 Inp_ICC_Fail "Inputs to the Ign Cycle Cntr are in a Pend or MIL cond.";
CM_ SG_ 1042 InputsGDFail "General Denominator Requirements Achieved Validity. The engine controller sets this bit when any of the inputs to the General Denominator are in a pending or MIL fault.";
CM_ SG_ 1042 LoadOBD "Engine calculated load value in percentage of load.";
CM_ SG_ 495 CRC_RF1 "CRC according to SAE J1850 standard that has to be calculated at each frame transmission";
CM_ SG_ 495 DriverEngineOffRequest "The signal is used to inform that an engine shut off is requried by the driver";
CM_ SG_ 495 FobSearchResult "FOB search result";
CM_ SG_ 495 Message_Counter_RF1 "This signal is a counter used for safety checks strategies. This counter is incremented of 1 (one) unit at each frame transmission";
CM_ SG_ 1848 MsgFOBLeftVeh "FOB left vehicle";
CM_ SG_ 1848 MsgFOBNotFnd "FOB Not Detected.";
CM_ SG_ 1848 MsgParkSoon "Signal used to activate the indication for soon Park position insertion.";
CM_ SG_ 762 CRC_CSWC_1 "CRC according to SAE J1850 standard that has to be calculated from bit 63 to bit 48 at each frame transmission.";
CM_ SG_ 762 CruiseControlFailSts "Cruise Switch: Implausible State=1";
CM_ SG_ 762 CruiseControlOnOffSts "Cruise Switch: On/Off Pressed";
CM_ SG_ 762 Lifter_OnOffSts "This signal indicates the status to enable/disable the Chronometer functionality";
CM_ SG_ 762 MC_CSWC_1 "This signal is a counter used for safety checks strategies. This counter is incremented of 1 (one) unit at each frame transmission.";
CM_ SG_ 762 SpeedRockerSts "Cruise Rocker: Set/Accel/Decel Pressed";
CM_ SG_ 2654339073 CurrentFailSts_ECM "The signal indicates that a present fault exists on node";
CM_ SG_ 2654339073 DES_ECM "The signal indicates the CAN Controller status";
CM_ SG_ 2654339073 EOL_ECM "This signal indicates if it is required/not required to the node to partecipate to the PROXI procedure.";
CM_ SG_ 2654339073 GenericFailSts_ECM "The signal indicates that one or more cells containing fault information exist on node memory.";
CM_ SG_ 2654339075 CurrentFailSts_IPC "The signal indicates that a present fault exists on node";
CM_ SG_ 2654339075 DES_IPC "The signal indicates the CAN Controller status";
CM_ SG_ 2654339075 EOL_IPC "This signal indicates if it is required/not required to the node to partecipate to the PROXI procedure.";
CM_ SG_ 2654339075 GenericFailSts_IPC "The signal indicates that one or more cells containing fault information exist on node memory.";
CM_ SG_ 2654339137 CurrentFailSts_RFHM "The signal indicates that a present fault exists on node";
CM_ SG_ 2654339137 DES_RFHM "The signal indicates the CAN Controller status";
CM_ SG_ 2654339137 EOL_RFHM "This signal indicates if it is required/not required to the node to partecipate to the PROXI procedure.";
CM_ SG_ 2654339137 GenericFailSts_RFHM "The signal indicates that one or more cells containing fault information exist on node memory.";
CM_ SG_ 2654339107 CurrentFailSts_TBM "The signal indicates that a present fault exists on node";
CM_ SG_ 2654339107 DES_TBM "The signal indicates the CAN Controller status";
CM_ SG_ 2654339107 EOL_TBM "This signal indicates if it is required/not required to the node to partecipate to the PROXI procedure.";
CM_ SG_ 2654339107 GenericFailSts_TBM "The signal indicates that one or more cells containing fault information exist on node memory.";
CM_ SG_ 2654339083 CurrentFailSts_Transmission "The signal indicates that a present fault exists on node";
CM_ SG_ 2654339083 DES_Transmission "The signal indicates the CAN Controller status";
CM_ SG_ 2654339083 EOL_Transmission "This signal indicates if it is required/not required to the node to partecipate to the PROXI procedure.";
CM_ SG_ 2654339083 GenericFailSts_Transmission "The signal indicates that one or more cells containing fault information exist on node memory.";
CM_ SG_ 508 ADC_FailSts "This signal indicates the fail status of ADC control";
CM_ SG_ 508 ADC_STS "This signal indicates the state of ADC control";
CM_ SG_ 508 CDCM_WarningLamp "This signal indicates the request for CDCM_Warning_Lamp";
CM_ SG_ 508 Lifter_FailSts "This signal indicates the lifter system failures";
CM_ SG_ 508 LifterCrankReq "This signal indicates the lifter request to recrank the engine during Stop&Start AutoStop";
CM_ SG_ 508 LifterInfoDisplay "This signal is used to trigger Lifter system cluster icons and indications";
CM_ SG_ 508 LifterPosition "This signal indicates the current lifter system position";
CM_ SG_ 508 LifterSts "This signal indicates the current lifter system status";
CM_ SG_ 508 RdAspInd "This signal indicates the road asperity index estimated by CDCM";
CM_ SG_ 508 Rear_Diff_Control_Sts "This signal indicates the Status of Rear Differential Control.";
CM_ SG_ 508 Rear_Diff_WarningLamp "This signal indicates the request for Rear_Differential_Warning_Lamp";
CM_ SG_ 1454 ChkFuelCap "This signal gives indication about loose fuel cap.";
CM_ SG_ 1454 CompressorSts "This signal gives information about the present status of A/C external request and actual A/C activation by ECM.";
CM_ SG_ 1454 EMSFailSts "This signal is used  to switch on and off the engine control system warning lamp (called MI for EOBD applications)";
CM_ SG_ 1454 EngineOperatingMode "This signal indicates the engine operating mode (normal or after-treatment systems regeneration)";
CM_ SG_ 1454 EngineWaterTempWarningLightSts "It is the information about water overtemperature light status.";
CM_ SG_ 1454 ETCFailSts "This signal is used  to switch on and off  ETC lamp to give informations about faults not EOBD relevant.";
CM_ SG_ 1454 ExhaustTemperature "This signal indicates the exhaust engine temperature after combustion or after-treatment systems (if applicable)";
CM_ SG_ 1454 GPFServiceSts "ECM enable flag for GPF service indication";
CM_ SG_ 1454 GPFSts "It is required only on gasoline systems equipped with Gasoline Particulate Filter. It is used to signalize that the current operating conditions (engine load, DPF pressure and temperature) do not allow performing the GPF regeneration strategy";
CM_ SG_ 1454 OilLifeSts "This information is related to engine oil life algorithm, currently used on Diesel engines equipped with DPF.";
CM_ SG_ 1454 OilPressureFailSts "It is the Fail Status bit of OilPressure signal.";
CM_ SG_ 1454 OilPressureSts "This signal  indicates oil pressure status (High or low).";
CM_ SG_ 1057 RrAvl_Stat "Over all temperature availability";
CM_ SG_ 1504 EPB_HMI_Management "Management IPC/VP pop-up";
CM_ SG_ 1504 EPBAutoAppSts "Status of AutoApply Functionality";
CM_ SG_ 1504 EPBFailureLampReq "This signal is used to request the EPB failure indication";
CM_ SG_ 1504 EPBMaintenanceSts "Status of Maintenance Functionality";
CM_ SG_ 1504 EPBReleaseIndReq "This signal is used to request the EPB manually release indication";
CM_ SG_ 1504 EPBSts "This signal describes the EPB status";
CM_ SG_ 1504 EPBSwitchPosition "This signal is used to give information about the postition of the EPB switch";
CM_ SG_ 1504 RedLampReq "This signal is used to request the EPB RED Indication";
CM_ SG_ 1196 InflationState_LHF_Tyre1 "It signal indicated the state for the pressure of the wheel identified";
CM_ SG_ 1196 InflationState_LHR_Tyre1 "It signal indicated the state for the pressure of the wheel identified";
CM_ SG_ 1196 InflationState_RHF_Tyre1 "It signal indicated the state for the pressure of the wheel identified";
CM_ SG_ 1196 InflationState_RHR_Tyre1 "It signal indicated the state for the pressure of the wheel identified";
CM_ SG_ 1196 PressureValue_LHF_Tyre "It is the value of indicated tyre wheel [bar]";
CM_ SG_ 1196 PressureValue_LHR_Tyre "It is the value of indicated tyre wheel [bar]";
CM_ SG_ 1196 PressureValue_RHF_Tyre "It is the value of indicated tyre wheel [bar]";
CM_ SG_ 1196 PressureValue_RHR_Tyre "It is the value of indicated tyre wheel [bar]";
CM_ SG_ 1196 TPMActivitySts "It indicates whether the TPMS ECU is enabled or disabled.";
CM_ SG_ 1196 TyrePressureSysProgrammedSts "It indicates the TPMS ECU programming status.";
CM_ SG_ 1196 TyrePressureSystemFailSts1 "It indicates that the TPM System is in Fault or not";
CM_ SG_ 1850 Day1 "It is the first digit of the day for the date visualization";
CM_ SG_ 1850 Day2 "It is the second digit of the day for the date visualization";
CM_ SG_ 1850 Hour1 "It is the first digit of the hours for the clock visualization";
CM_ SG_ 1850 Hour2 "It is the second digit of the hours for the clock visualization";
CM_ SG_ 1850 Minute1 "It is  the first digit of the minutes for the clock visualization";
CM_ SG_ 1850 Minute2 "It is the second digit of the minutes for the clock visualization";
CM_ SG_ 1850 Month1 "It is the first digit of the month for the date visualization";
CM_ SG_ 1850 Month2 "It is the second digit of the month for the date visualization";
CM_ SG_ 1850 Year1 "It is the first digit of the year for the date visualization";
CM_ SG_ 1850 Year2 "It is the second digit of the year for the date visualization";
CM_ SG_ 1850 Year3 "It is the third digit of the year for the date visualization";
CM_ SG_ 1850 Year4 "It is the fourth digit of the year for the date visualization";
CM_ SG_ 503 CODE_CLR_TCM "Clear emission related faults";
CM_ SG_ 503 CRC_TM2 "Checksum";
CM_ SG_ 503 MC_TM2 "Message Counter";
CM_ SG_ 503 REPRGD_PFC_CLR_TCM "Set readiness to incomplete";
CM_ SG_ 236 CutRequest "Engine fuel cut request from DCTM";
CM_ SG_ 236 DCTMGbProtectionSpeed "Protection maximum engine speed request value active flag from DCTM. Maximum speed value will be sent on ReqEngineSpeed";
CM_ SG_ 236 DCTMGbProtectionTorque "Protection maximum engine torque request value active flag from DCTM. Maximum torque value will be sent on ReqTorqueValue.";
CM_ SG_ 236 DCTState "See DCT State Definition";
CM_ SG_ 236 EngineSlaveRequest "Speed or Torque request from DCTM active flag";
CM_ SG_ 236 FutureSyncGear "Target gear for upcoming gearshift used by ECM for calibration switching.";
CM_ SG_ 236 FutureSyncRPM "Final synchronization engine speed for upcoming gearshift/pullaway used by ECM for calibration switching.";
CM_ SG_ 236 ReqEngineSpeed "Engine Speed request from DCTM";
CM_ SG_ 236 ReqTorqueValue "Engine Torque request from DCTM";
CM_ SG_ 260 LnchCtrl_TextDisplay "Launch Control Text Display Request";
CM_ SG_ 260 TorqueAmpTransmission "It is the torque transmission ratio from gearbox primary to wheels, calculated by gearbox . It is only used in Automatic Transmission application";
CM_ SG_ 1448 CrankEnable "This signal is used to enable the cranking in safety condition";
CM_ SG_ 1448 GearEngaged "Current engaged gear.";
CM_ SG_ 1448 LimpHomeSts "This signal is used in case of those gearbox faults that limit the higher usable gear.";
CM_ SG_ 1448 MIReq "This signal indicates that the gearbox has any EOBD errors.";
CM_ SG_ 1448 ShiftInProgress "Transmission shift in progress";
CM_ SG_ 1448 TargetGear "Tells of the intended target gear that the transmission will be shifting to. Also includes an cancel shift that the DASM uses for better control.";
CM_ SG_ 1448 TempManualOverride "Temporary Manual Override for entering manual mode due to a paddle request. Active for a calibrate-able time after engine";
CM_ SG_ 1448 TemporaryManualSts "This signal indicates a temporary manual Status of the GearBox";
CM_ SG_ 1448 TxDisengaged "Transmission is disengaged";
CM_ SG_ 234 ActiveGearRatio "Current gearbox transmission ratio, defined as a continous profile during gearshift";
CM_ SG_ 234 AMTIndex "Percentage of AMT Gearshift simulation strategy";
CM_ SG_ 234 ClutchStatus "Current operating state defined from combining the actual state of both clutches";
CM_ SG_ 234 CutOffTime "DCTM request to prevent the ECM from entering fuel cut-off mode";
CM_ SG_ 234 ESPReqFulfillDCTM "ESP torque cut request fulfilled by DCTM strategy";
CM_ SG_ 234 GearBoxAbsorption "Loss torque from gearbox";
CM_ SG_ 234 LaunchActive "Additional flag reserved for Launch control implementations.";
CM_ SG_ 234 ReqSlowTorqueValue "Slow engine torque request from DCTM";
CM_ SG_ 234 SpeedReqType "State signal detailing the speed request type";
CM_ SG_ 234 TorqueReqType "State signal detailing the torque request type";
CM_ SG_ 253 CodeCheckSts_TRM "This signal is used to indicate the result of the code check.";
CM_ SG_ 253 ProgrammedSts_TRM "This signal  is used to indicate if the TRM is programmed.";
CM_ SG_ 253 TxpFound "This signal is used to give information about the presence of a transponder";
CM_ SG_ 253 TxpID "This signal is used to give information about the transponder authentication.";
CM_ SG_ 1046 VIN_DATA "VIN Digits (8 bit ascii encoded)";
CM_ SG_ 1046 VIN_MSG "VIN Message Information";
CM_ SG_ 2654208000 MainWakeSts_BCM "Main wakeup status from BCM";
CM_ SG_ 2654208000 Node0 "Node 0 wakeup active";
CM_ SG_ 2654208000 Node1 "Node 1 wakeup active";
CM_ SG_ 2654208000 Node10 "Node 10 wakeup active";
CM_ SG_ 2654208000 Node11 "Node 11 wakeup active";
CM_ SG_ 2654208000 Node12 "Node 12 wakeup active";
CM_ SG_ 2654208000 Node13 "Node 13 wakeup active";
CM_ SG_ 2654208000 Node14 "Node 14 wakeup active";
CM_ SG_ 2654208000 Node15 "Node 15 wakeup active";
CM_ SG_ 2654208000 Node16 "Node 16 wakeup active";
CM_ SG_ 2654208000 Node17 "Node 17 wakeup active";
CM_ SG_ 2654208000 Node18 "Node 18 wakeup active";
CM_ SG_ 2654208000 Node19 "Node 19 wakeup active";
CM_ SG_ 2654208000 Node2 "Node 2 wakeup active";
CM_ SG_ 2654208000 Node20 "Node 20 wakeup active";
CM_ SG_ 2654208000 Node21 "Node 21 wakeup active";
CM_ SG_ 2654208000 Node22 "Node 22 wakeup active";
CM_ SG_ 2654208000 Node23 "Node 23 wakeup active";
CM_ SG_ 2654208000 Node24 "Node 24 wakeup active";
CM_ SG_ 2654208000 Node25 "Node 25 wakeup active";
CM_ SG_ 2654208000 Node26 "Node 26 wakeup active";
CM_ SG_ 2654208000 Node27 "Node 27 wakeup active";
CM_ SG_ 2654208000 Node28 "Node 28 wakeup active";
CM_ SG_ 2654208000 Node29 "Node 29 wakeup active";
CM_ SG_ 2654208000 Node3 "Node 3 wakeup active";
CM_ SG_ 2654208000 Node30 "Node 30 wakeup active";
CM_ SG_ 2654208000 Node31 "Node 31 wakeup active";
CM_ SG_ 2654208000 Node4 "Node 4 wakeup active";
CM_ SG_ 2654208000 Node5 "Node 5 wakeup active";
CM_ SG_ 2654208000 Node6 "Node 6 wakeup active";
CM_ SG_ 2654208000 Node7 "Node 7 wakeup active";
CM_ SG_ 2654208000 Node8 "Node 8 wakeup active";
CM_ SG_ 2654208000 Node9 "Node 9 wakeup active";
CM_ SG_ 2654208000 WakeCntr_BCM "Wakeup counter for BCM";
CM_ SG_ 2654208000 WakeRsn_BCM "Wakeup reason for BCM";
CM_ SG_ 2654208006 WakeCntr_BSM "Wakeup counter for BSM.";
CM_ SG_ 2654208006 WakeReq_BSM "Wakeup request bit for BSM.";
CM_ SG_ 2654208006 WakeRsn_BSM "Wakeup reason for BSM.";
CM_ SG_ 2654208003 WakeCntr_IPC "Wakeup counter for SCCM";
CM_ SG_ 2654208003 WakeReq_IPC "Wakeup request bit for SCCM";
CM_ SG_ 2654208003 WakeRsn_IPC "Wakeup reason for SCCM";
CM_ SG_ 2654208065 WakeCntr_RFHM "Wakeup counter for RFHM";
CM_ SG_ 2654208065 WakeReq_RFHM "Wakeup request bit for RFHM";
CM_ SG_ 2654208065 WakeRsn_RFHM "Wakeup reason for RFHM";
CM_ SG_ 2654208011 WakeCntr_Transmission "Wakeup counter for TCM";
CM_ SG_ 2654208011 WakeReq_Transmission "Wakeup request bit for TCM";
CM_ SG_ 2654208011 WakeRsn_Transmission "Wakeup reason for TCM";
CM_ SG_ 278 CRC_WI "CRC according to SAE J1850 standard that has to be calculated from bit 63 to bit 8 at each frame transmission.";
CM_ SG_ 278 LHF_FastPulseCounter "This signal is the left front wheel pulse counter.";
CM_ SG_ 278 LHF_Spin "This signal indicates the left hand front wheel status";
CM_ SG_ 278 LHF_WheelSensorFailSts "This signal indicates the fail status of LHF sensor";
CM_ SG_ 278 LHR_FastPulseCounter "This signal is the left rear wheel pulse counter.";
CM_ SG_ 278 LHR_Spin "This signal indicates the left hand rear wheel status";
CM_ SG_ 278 LHR_WheelSensorFailSts "This signal indicates the fail status of LHR sensor";
CM_ SG_ 278 MessageCounter_WI "This signal is a counter used for safety checks strategies. This counter is incremented of 1 (one) unit at each frame transmission.";
CM_ SG_ 278 RHF_FastPulseCounter "This signal is the right front wheel pulse counter.";
CM_ SG_ 278 RHF_Spin "This signal indicates the right hand front wheel status";
CM_ SG_ 278 RHF_WheelSensorFailSts "This signal indicates the fail status of RHF sensor";
CM_ SG_ 278 RHR_FastPulseCounter "This signal is the right rear wheel pulse counter.";
CM_ SG_ 278 RHR_Spin "This signal indicates the right hand rear wheel status";
CM_ SG_ 278 RHR_WheelSensorFailSts "This signal indicates the fail status of RHR sensor";
CM_ SG_ 238 CRC_WS "CRC according to SAE J1850 standard that has to be calculated from bit 63 to bit 8 at each frame transmission.";
CM_ SG_ 238 LHFWheelSpeed "This is the value of the left front wheel speed";
CM_ SG_ 238 LHRWheelSpeed "This is the value of the left rear wheel speed";
CM_ SG_ 238 MessageCounter_WS "This signal is a counter used for safety checks strategies. This counter is incremented of 1 (one) unit at each frame transmission.";
CM_ SG_ 238 RHFWheelSpeed "This is the value of the right front wheel speed";
CM_ SG_ 238 RHRWheelSpeed "This is the value of the right rear wheel speed";
BA_DEF_ SG_  "Accuracy" STRING ;
BA_DEF_ SG_  "Event trans." ENUM  "Yes","No";
BA_DEF_ SG_  "GenSigStartValue" INT 0 2147483647;
BA_DEF_ SG_  "GenSigInactiveValue" INT 0 2147483647;
BA_DEF_ SG_  "GenSigSendType" ENUM  "NotUsed","OnWrite","OnWriteWithRepetition","OnChange","OnChangeWithRepetition","IfActive","IfActiveWithRepetition","NoSigSendType";
BA_DEF_ BO_  "DiagRequest" ENUM  "No","Yes";
BA_DEF_ BO_  "Period [ms]" INT 0 65535;
BA_DEF_ BO_  "Type" ENUM  "P","C","PE","COC","PE_Cntrl","E","E_Cntrl","OC","S","BAF","DC","EM","MM","-";
BA_DEF_ BO_  "DiagResponse" ENUM  "No","Yes";
BA_DEF_ BO_  "NmMessage" ENUM  "No","Yes";
BA_DEF_ BO_  "GenMsgSendType" ENUM  "Cyclic","NotUsed","NotUsed","NotUsed","NotUsed","NotUsed","NotUsed","NotUsed","NoMsgSendType";
BA_DEF_ BO_  "GenMsgTimeoutTime" INT 0 10000;
BA_DEF_ BO_  "GenMsgNrOfRepetition" INT 0 255;
BA_DEF_ BO_  "GenMsgILSupport" ENUM  "No","Yes";
BA_DEF_ BO_  "GenMsgStartDelayTime" INT 0 65535;
BA_DEF_ BO_  "GenMsgCycleTimeFast" INT 0 65535;
BA_DEF_ BO_  "GenMsgCycleTime" INT 0 65535;
BA_DEF_ BO_  "GenMsgDelayTime" INT 0 65535;
BA_DEF_ BO_  "DiagState" ENUM  "No","Yes";
BA_DEF_ SG_  "SystemSignalLongSymbol" STRING ;
BA_DEF_DEF_  "Accuracy" "";
BA_DEF_DEF_  "Event trans." "No";
BA_DEF_DEF_  "GenSigStartValue" 0;
BA_DEF_DEF_  "GenSigInactiveValue" 0;
BA_DEF_DEF_  "GenSigSendType" "NoSigSendType";
BA_DEF_DEF_  "DiagRequest" "No";
BA_DEF_DEF_  "Period [ms]" 0;
BA_DEF_DEF_  "Type" "-";
BA_DEF_DEF_  "DiagResponse" "No";
BA_DEF_DEF_  "NmMessage" "No";
BA_DEF_DEF_  "GenMsgSendType" "NoMsgSendType";
BA_DEF_DEF_  "GenMsgTimeoutTime" 0;
BA_DEF_DEF_  "GenMsgNrOfRepetition" 0;
BA_DEF_DEF_  "GenMsgILSupport" "No";
BA_DEF_DEF_  "GenMsgStartDelayTime" 0;
BA_DEF_DEF_  "GenMsgCycleTimeFast" 0;
BA_DEF_DEF_  "GenMsgCycleTime" 0;
BA_DEF_DEF_  "GenMsgDelayTime" 0;
BA_DEF_DEF_  "DiagState" "No";
BA_DEF_DEF_  "SystemSignalLongSymbol" "";
BA_ "Period [ms]" BO_ 1051 100;
BA_ "Type" BO_ 1051 1;
BA_ "GenMsgSendType" BO_ 1051 0;
BA_ "GenMsgILSupport" BO_ 1051 1;
BA_ "GenMsgStartDelayTime" BO_ 1051 28;
BA_ "GenMsgCycleTime" BO_ 1051 100;
BA_ "Period [ms]" BO_ 255 10;
BA_ "Type" BO_ 255 1;
BA_ "GenMsgSendType" BO_ 255 0;
BA_ "GenMsgILSupport" BO_ 255 1;
BA_ "GenMsgStartDelayTime" BO_ 255 4;
BA_ "GenMsgCycleTime" BO_ 255 10;
BA_ "Period [ms]" BO_ 251 10;
BA_ "Type" BO_ 251 1;
BA_ "GenMsgSendType" BO_ 251 0;
BA_ "GenMsgILSupport" BO_ 251 1;
BA_ "GenMsgStartDelayTime" BO_ 251 2;
BA_ "GenMsgCycleTime" BO_ 251 10;
BA_ "Period [ms]" BO_ 496 20;
BA_ "Type" BO_ 496 1;
BA_ "GenMsgSendType" BO_ 496 0;
BA_ "GenMsgTimeoutTime" BO_ 496 2500;
BA_ "GenMsgILSupport" BO_ 496 1;
BA_ "GenMsgStartDelayTime" BO_ 496 7;
BA_ "GenMsgCycleTime" BO_ 496 20;
BA_ "Period [ms]" BO_ 749 50;
BA_ "Type" BO_ 749 1;
BA_ "GenMsgSendType" BO_ 749 0;
BA_ "GenMsgILSupport" BO_ 749 1;
BA_ "GenMsgStartDelayTime" BO_ 749 8;
BA_ "GenMsgCycleTime" BO_ 749 50;
BA_ "Period [ms]" BO_ 751 50;
BA_ "Type" BO_ 751 1;
BA_ "GenMsgSendType" BO_ 751 0;
BA_ "GenMsgILSupport" BO_ 751 1;
BA_ "GenMsgStartDelayTime" BO_ 751 42;
BA_ "GenMsgCycleTime" BO_ 751 50;
BA_ "Period [ms]" BO_ 550 1000;
BA_ "Type" BO_ 550 3;
BA_ "GenMsgSendType" BO_ 550 0;
BA_ "GenMsgILSupport" BO_ 550 1;
BA_ "GenMsgStartDelayTime" BO_ 550 300;
BA_ "GenMsgCycleTime" BO_ 550 1000;
BA_ "GenMsgDelayTime" BO_ 550 20;
BA_ "Period [ms]" BO_ 1854 250;
BA_ "Type" BO_ 1854 3;
BA_ "GenMsgSendType" BO_ 1854 0;
BA_ "GenMsgILSupport" BO_ 1854 1;
BA_ "GenMsgStartDelayTime" BO_ 1854 80;
BA_ "GenMsgCycleTime" BO_ 1854 250;
BA_ "GenMsgDelayTime" BO_ 1854 20;
BA_ "Type" BO_ 222 11;
BA_ "GenMsgTimeoutTime" BO_ 222 2500;
BA_ "GenMsgILSupport" BO_ 222 1;
BA_ "DiagRequest" BO_ 2147565809 1;
BA_ "Type" BO_ 2147565809 8;
BA_ "DiagRequest" BO_ 2147553521 1;
BA_ "Type" BO_ 2147553521 8;
BA_ "DiagRequest" BO_ 2147574001 1;
BA_ "Type" BO_ 2147574001 8;
BA_ "DiagRequest" BO_ 2147600369 1;
BA_ "Type" BO_ 2147600369 8;
BA_ "DiagRequest" BO_ 2147600113 1;
BA_ "Type" BO_ 2147600113 8;
BA_ "DiagRequest" BO_ 2147555569 1;
BA_ "Type" BO_ 2147555569 8;
BA_ "Type" BO_ 100 8;
BA_ "GenMsgILSupport" BO_ 100 1;
BA_ "GenMsgDelayTime" BO_ 100 10;
BA_ "Type" BO_ 104 11;
BA_ "GenMsgILSupport" BO_ 104 1;
BA_ "GenMsgDelayTime" BO_ 104 10;
BA_ "Period [ms]" BO_ 346 500;
BA_ "Type" BO_ 346 10;
BA_ "GenMsgSendType" BO_ 346 0;
BA_ "GenMsgILSupport" BO_ 346 1;
BA_ "GenMsgCycleTimeFast" BO_ 346 10;
BA_ "GenMsgCycleTime" BO_ 346 500;
BA_ "Period [ms]" BO_ 1058 100;
BA_ "Type" BO_ 1058 1;
BA_ "GenMsgSendType" BO_ 1058 0;
BA_ "GenMsgILSupport" BO_ 1058 1;
BA_ "GenMsgStartDelayTime" BO_ 1058 35;
BA_ "GenMsgCycleTime" BO_ 1058 100;
BA_ "Period [ms]" BO_ 1060 100;
BA_ "Type" BO_ 1060 1;
BA_ "GenMsgSendType" BO_ 1060 0;
BA_ "GenMsgILSupport" BO_ 1060 1;
BA_ "GenMsgStartDelayTime" BO_ 1060 40;
BA_ "GenMsgCycleTime" BO_ 1060 100;
BA_ "Period [ms]" BO_ 1062 100;
BA_ "Type" BO_ 1062 1;
BA_ "GenMsgSendType" BO_ 1062 0;
BA_ "GenMsgILSupport" BO_ 1062 1;
BA_ "GenMsgStartDelayTime" BO_ 1062 45;
BA_ "GenMsgCycleTime" BO_ 1062 100;
BA_ "Period [ms]" BO_ 256 10;
BA_ "Type" BO_ 256 1;
BA_ "GenMsgSendType" BO_ 256 0;
BA_ "GenMsgILSupport" BO_ 256 1;
BA_ "GenMsgStartDelayTime" BO_ 256 6;
BA_ "GenMsgCycleTime" BO_ 256 10;
BA_ "Period [ms]" BO_ 244 10;
BA_ "Type" BO_ 244 1;
BA_ "GenMsgSendType" BO_ 244 0;
BA_ "GenMsgILSupport" BO_ 244 1;
BA_ "GenMsgStartDelayTime" BO_ 244 2;
BA_ "GenMsgCycleTime" BO_ 244 10;
BA_ "Period [ms]" BO_ 500 20;
BA_ "Type" BO_ 500 1;
BA_ "GenMsgSendType" BO_ 500 0;
BA_ "GenMsgILSupport" BO_ 500 1;
BA_ "GenMsgStartDelayTime" BO_ 500 4;
BA_ "GenMsgCycleTime" BO_ 500 20;
BA_ "Period [ms]" BO_ 1047 100;
BA_ "Type" BO_ 1047 1;
BA_ "GenMsgSendType" BO_ 1047 0;
BA_ "GenMsgILSupport" BO_ 1047 1;
BA_ "GenMsgStartDelayTime" BO_ 1047 48;
BA_ "GenMsgCycleTime" BO_ 1047 100;
BA_ "Period [ms]" BO_ 1042 100;
BA_ "Type" BO_ 1042 1;
BA_ "GenMsgSendType" BO_ 1042 0;
BA_ "GenMsgILSupport" BO_ 1042 1;
BA_ "GenMsgStartDelayTime" BO_ 1042 14;
BA_ "GenMsgCycleTime" BO_ 1042 100;
BA_ "Period [ms]" BO_ 495 20;
BA_ "Type" BO_ 495 1;
BA_ "GenMsgSendType" BO_ 495 0;
BA_ "GenMsgILSupport" BO_ 495 1;
BA_ "GenMsgStartDelayTime" BO_ 495 5;
BA_ "GenMsgCycleTime" BO_ 495 20;
BA_ "Period [ms]" BO_ 2000 20;
BA_ "Type" BO_ 2000 1;
BA_ "GenMsgSendType" BO_ 2000 0;
BA_ "GenMsgILSupport" BO_ 2000 1;
BA_ "GenMsgCycleTime" BO_ 2000 20;
BA_ "Period [ms]" BO_ 1848 1000;
BA_ "Type" BO_ 1848 3;
BA_ "GenMsgSendType" BO_ 1848 0;
BA_ "GenMsgILSupport" BO_ 1848 1;
BA_ "GenMsgStartDelayTime" BO_ 1848 25;
BA_ "GenMsgCycleTime" BO_ 1848 1000;
BA_ "GenMsgDelayTime" BO_ 1848 20;
BA_ "Type" BO_ 762 11;
BA_ "GenMsgTimeoutTime" BO_ 762 2500;
BA_ "GenMsgILSupport" BO_ 762 1;
BA_ "Period [ms]" BO_ 2654339073 1000;
BA_ "Type" BO_ 2654339073 1;
BA_ "GenMsgSendType" BO_ 2654339073 0;
BA_ "GenMsgTimeoutTime" BO_ 2654339073 2500;
BA_ "GenMsgILSupport" BO_ 2654339073 1;
BA_ "GenMsgStartDelayTime" BO_ 2654339073 150;
BA_ "GenMsgCycleTime" BO_ 2654339073 1000;
BA_ "Period [ms]" BO_ 2654339075 1000;
BA_ "Type" BO_ 2654339075 1;
BA_ "GenMsgSendType" BO_ 2654339075 0;
BA_ "GenMsgTimeoutTime" BO_ 2654339075 2500;
BA_ "GenMsgILSupport" BO_ 2654339075 1;
BA_ "GenMsgStartDelayTime" BO_ 2654339075 250;
BA_ "GenMsgCycleTime" BO_ 2654339075 1000;
BA_ "Period [ms]" BO_ 2654339137 1000;
BA_ "Type" BO_ 2654339137 1;
BA_ "GenMsgSendType" BO_ 2654339137 0;
BA_ "GenMsgTimeoutTime" BO_ 2654339137 2500;
BA_ "GenMsgILSupport" BO_ 2654339137 1;
BA_ "GenMsgStartDelayTime" BO_ 2654339137 500;
BA_ "GenMsgCycleTime" BO_ 2654339137 1000;
BA_ "Period [ms]" BO_ 2654339107 1000;
BA_ "Type" BO_ 2654339107 1;
BA_ "GenMsgSendType" BO_ 2654339107 0;
BA_ "GenMsgTimeoutTime" BO_ 2654339107 2500;
BA_ "GenMsgILSupport" BO_ 2654339107 1;
BA_ "GenMsgCycleTime" BO_ 2654339107 1000;
BA_ "Period [ms]" BO_ 2654339083 1000;
BA_ "Type" BO_ 2654339083 1;
BA_ "GenMsgSendType" BO_ 2654339083 0;
BA_ "GenMsgTimeoutTime" BO_ 2654339083 2500;
BA_ "GenMsgILSupport" BO_ 2654339083 1;
BA_ "GenMsgStartDelayTime" BO_ 2654339083 300;
BA_ "GenMsgCycleTime" BO_ 2654339083 1000;
BA_ "Period [ms]" BO_ 508 20;
BA_ "Type" BO_ 508 1;
BA_ "GenMsgSendType" BO_ 508 0;
BA_ "GenMsgTimeoutTime" BO_ 508 2500;
BA_ "GenMsgILSupport" BO_ 508 1;
BA_ "GenMsgStartDelayTime" BO_ 508 10;
BA_ "GenMsgCycleTime" BO_ 508 20;
BA_ "Period [ms]" BO_ 1454 1000;
BA_ "Type" BO_ 1454 3;
BA_ "GenMsgSendType" BO_ 1454 0;
BA_ "GenMsgILSupport" BO_ 1454 1;
BA_ "GenMsgStartDelayTime" BO_ 1454 600;
BA_ "GenMsgCycleTime" BO_ 1454 1000;
BA_ "GenMsgDelayTime" BO_ 1454 20;
BA_ "Period [ms]" BO_ 1057 10;
BA_ "Type" BO_ 1057 1;
BA_ "GenMsgSendType" BO_ 1057 0;
BA_ "GenMsgTimeoutTime" BO_ 1057 2500;
BA_ "GenMsgILSupport" BO_ 1057 1;
BA_ "GenMsgCycleTime" BO_ 1057 10;
BA_ "Period [ms]" BO_ 1504 250;
BA_ "Type" BO_ 1504 10;
BA_ "GenMsgSendType" BO_ 1504 0;
BA_ "GenMsgILSupport" BO_ 1504 1;
BA_ "GenMsgCycleTimeFast" BO_ 1504 20;
BA_ "GenMsgCycleTime" BO_ 1504 250;
BA_ "GenMsgDelayTime" BO_ 1504 10;
BA_ "Period [ms]" BO_ 1196 2000;
BA_ "Type" BO_ 1196 3;
BA_ "GenMsgSendType" BO_ 1196 0;
BA_ "GenMsgNrOfRepetition" BO_ 1196 2;
BA_ "GenMsgILSupport" BO_ 1196 1;
BA_ "GenMsgStartDelayTime" BO_ 1196 200;
BA_ "GenMsgCycleTimeFast" BO_ 1196 10;
BA_ "GenMsgCycleTime" BO_ 1196 2000;
BA_ "GenMsgDelayTime" BO_ 1196 10;
BA_ "Period [ms]" BO_ 1850 1000;
BA_ "Type" BO_ 1850 1;
BA_ "GenMsgSendType" BO_ 1850 0;
BA_ "GenMsgILSupport" BO_ 1850 1;
BA_ "GenMsgStartDelayTime" BO_ 1850 750;
BA_ "GenMsgCycleTime" BO_ 1850 1000;
BA_ "Period [ms]" BO_ 503 20;
BA_ "Type" BO_ 503 1;
BA_ "GenMsgSendType" BO_ 503 0;
BA_ "GenMsgILSupport" BO_ 503 1;
BA_ "GenMsgStartDelayTime" BO_ 503 10;
BA_ "GenMsgCycleTime" BO_ 503 20;
BA_ "Period [ms]" BO_ 236 10;
BA_ "Type" BO_ 236 1;
BA_ "GenMsgSendType" BO_ 236 0;
BA_ "GenMsgNrOfRepetition" BO_ 236 3;
BA_ "GenMsgILSupport" BO_ 236 1;
BA_ "GenMsgStartDelayTime" BO_ 236 5;
BA_ "GenMsgCycleTimeFast" BO_ 236 10;
BA_ "GenMsgCycleTime" BO_ 236 10;
BA_ "GenMsgDelayTime" BO_ 236 10;
BA_ "Period [ms]" BO_ 260 10;
BA_ "Type" BO_ 260 1;
BA_ "GenMsgSendType" BO_ 260 0;
BA_ "GenMsgILSupport" BO_ 260 1;
BA_ "GenMsgCycleTime" BO_ 260 10;
BA_ "Period [ms]" BO_ 1448 1000;
BA_ "Type" BO_ 1448 3;
BA_ "GenMsgSendType" BO_ 1448 0;
BA_ "GenMsgILSupport" BO_ 1448 1;
BA_ "GenMsgStartDelayTime" BO_ 1448 5;
BA_ "GenMsgCycleTime" BO_ 1448 1000;
BA_ "GenMsgDelayTime" BO_ 1448 20;
BA_ "Period [ms]" BO_ 234 10;
BA_ "Type" BO_ 234 1;
BA_ "GenMsgSendType" BO_ 234 0;
BA_ "GenMsgILSupport" BO_ 234 1;
BA_ "GenMsgStartDelayTime" BO_ 234 5;
BA_ "GenMsgCycleTime" BO_ 234 10;
BA_ "GenMsgDelayTime" BO_ 234 20;
BA_ "Type" BO_ 253 8;
BA_ "GenMsgTimeoutTime" BO_ 253 2500;
BA_ "GenMsgILSupport" BO_ 253 1;
BA_ "GenMsgDelayTime" BO_ 253 10;
BA_ "Type" BO_ 243 12;
BA_ "GenMsgILSupport" BO_ 243 1;
BA_ "GenMsgDelayTime" BO_ 243 20;
BA_ "Period [ms]" BO_ 1046 100;
BA_ "Type" BO_ 1046 1;
BA_ "GenMsgSendType" BO_ 1046 0;
BA_ "GenMsgILSupport" BO_ 1046 1;
BA_ "GenMsgStartDelayTime" BO_ 1046 20;
BA_ "GenMsgCycleTime" BO_ 1046 100;
BA_ "Period [ms]" BO_ 2654208000 200;
BA_ "Type" BO_ 2654208000 3;
BA_ "NmMessage" BO_ 2654208000 1;
BA_ "GenMsgSendType" BO_ 2654208000 0;
BA_ "GenMsgTimeoutTime" BO_ 2654208000 2500;
BA_ "GenMsgCycleTime" BO_ 2654208000 200;
BA_ "GenMsgDelayTime" BO_ 2654208000 10;
BA_ "Type" BO_ 2654208006 8;
BA_ "NmMessage" BO_ 2654208006 1;
BA_ "GenMsgDelayTime" BO_ 2654208006 10;
BA_ "Type" BO_ 2654208003 8;
BA_ "NmMessage" BO_ 2654208003 1;
BA_ "GenMsgTimeoutTime" BO_ 2654208003 2500;
BA_ "GenMsgDelayTime" BO_ 2654208003 10;
BA_ "Type" BO_ 2654208065 8;
BA_ "NmMessage" BO_ 2654208065 1;
BA_ "GenMsgDelayTime" BO_ 2654208065 10;
BA_ "Type" BO_ 2654208011 8;
BA_ "NmMessage" BO_ 2654208011 1;
BA_ "GenMsgDelayTime" BO_ 2654208011 10;
BA_ "Period [ms]" BO_ 278 10;
BA_ "Type" BO_ 278 1;
BA_ "GenMsgSendType" BO_ 278 0;
BA_ "GenMsgILSupport" BO_ 278 1;
BA_ "GenMsgCycleTime" BO_ 278 10;
BA_ "Period [ms]" BO_ 238 10;
BA_ "Type" BO_ 238 1;
BA_ "GenMsgSendType" BO_ 238 0;
BA_ "GenMsgILSupport" BO_ 238 1;
BA_ "GenMsgCycleTime" BO_ 238 10;
BA_ "GenSigStartValue" SG_ 1051 ACPressure 511;
BA_ "Accuracy" SG_ 1051 ThrottlePosition "+/- 0,392";
BA_ "GenSigStartValue" SG_ 251 EngineTorque 2047;
BA_ "Accuracy" SG_ 496 ActualPedalPos "-";
BA_ "GenSigStartValue" SG_ 496 ActualPedalPos 1;
BA_ "GenSigStartValue" SG_ 751 SAMInfo 15;
BA_ "Event trans." SG_ 550 ECMLnchCtrlAllowed 0;
BA_ "GenSigSendType" SG_ 550 ECMLnchCtrlAllowed 3;
BA_ "Accuracy" SG_ 550 SpStChmRq "-";
BA_ "Event trans." SG_ 550 SpStChmRq 0;
BA_ "GenSigSendType" SG_ 550 SpStChmRq 3;
BA_ "Accuracy" SG_ 550 SpStDispstat "-";
BA_ "Event trans." SG_ 550 SpStDispstat 0;
BA_ "GenSigSendType" SG_ 550 SpStDispstat 3;
BA_ "Accuracy" SG_ 550 SpStIndRq "-";
BA_ "Event trans." SG_ 550 SpStIndRq 0;
BA_ "GenSigSendType" SG_ 550 SpStIndRq 3;
BA_ "Accuracy" SG_ 550 SpStSwStat "-";
BA_ "Event trans." SG_ 550 SpStSwStat 0;
BA_ "GenSigSendType" SG_ 550 SpStSwStat 3;
BA_ "Event trans." SG_ 550 SpStWarnStat 0;
BA_ "GenSigSendType" SG_ 550 SpStWarnStat 3;
BA_ "Accuracy" SG_ 1854 HighBeamSts "-";
BA_ "Event trans." SG_ 1854 HighBeamSts 0;
BA_ "GenSigSendType" SG_ 1854 HighBeamSts 3;
BA_ "Accuracy" SG_ 1854 LHParkingLightSts "-";
BA_ "Event trans." SG_ 1854 LHParkingLightSts 0;
BA_ "GenSigSendType" SG_ 1854 LHParkingLightSts 3;
BA_ "Accuracy" SG_ 1854 LHTurnLightFault "-";
BA_ "Accuracy" SG_ 1854 LHTurnSignalSts "-";
BA_ "Event trans." SG_ 1854 LHTurnSignalSts 0;
BA_ "GenSigSendType" SG_ 1854 LHTurnSignalSts 3;
BA_ "Accuracy" SG_ 1854 ParkingLightFault "-";
BA_ "Accuracy" SG_ 1854 RHParkingLightSts "-";
BA_ "Event trans." SG_ 1854 RHParkingLightSts 0;
BA_ "GenSigSendType" SG_ 1854 RHParkingLightSts 3;
BA_ "Accuracy" SG_ 1854 RHTurnLightFault "-";
BA_ "Accuracy" SG_ 1854 RHTurnSignalSts "-";
BA_ "Event trans." SG_ 1854 RHTurnSignalSts 0;
BA_ "GenSigSendType" SG_ 1854 RHTurnSignalSts 3;
BA_ "Accuracy" SG_ 1854 StopLightFault "-";
BA_ "Accuracy" SG_ 1854 StopLightSts "-";
BA_ "Event trans." SG_ 1854 StopLightSts 0;
BA_ "GenSigSendType" SG_ 1854 StopLightSts 3;
BA_ "Accuracy" SG_ 222 CRC_G "-";
BA_ "Accuracy" SG_ 222 ElectricSteeringFailSts "-";
BA_ "Accuracy" SG_ 222 LwsAngle "+/- 2.8°";
BA_ "Accuracy" SG_ 222 LwsCalibration "-";
BA_ "Accuracy" SG_ 222 LWSFailSts "-";
BA_ "Accuracy" SG_ 222 LwsSpeed "15 °/s";
BA_ "Accuracy" SG_ 222 MessageCounter_G "-";
BA_ "Accuracy" SG_ 2147574001 N_PDU "-";
BA_ "Accuracy" SG_ 100 ControlEncodingReq "-";
BA_ "Event trans." SG_ 100 ControlEncodingReq 0;
BA_ "GenSigSendType" SG_ 100 ControlEncodingReq 1;
BA_ "Accuracy" SG_ 100 f1_1 "-";
BA_ "Accuracy" SG_ 100 f1_2 "-";
BA_ "Accuracy" SG_ 100 rnd_1 "-";
BA_ "Accuracy" SG_ 100 rnd_2 "-";
BA_ "Accuracy" SG_ 100 rnd_3 "-";
BA_ "Accuracy" SG_ 100 rnd_4 "-";
BA_ "Accuracy" SG_ 104 ControlEncodingRsp "-";
BA_ "Event trans." SG_ 104 ControlEncodingRsp 0;
BA_ "GenSigSendType" SG_ 104 ControlEncodingRsp 1;
BA_ "Accuracy" SG_ 104 MKKey_3 "-";
BA_ "Accuracy" SG_ 104 MKKey_4 "-";
BA_ "Accuracy" SG_ 104 MKKey_5 "-";
BA_ "Accuracy" SG_ 104 MKKey_6 "-";
BA_ "Accuracy" SG_ 104 MKKey1org21 "-";
BA_ "Accuracy" SG_ 104 MKKey2org22 "-";
BA_ "Event trans." SG_ 346 IMPACTCommand 0;
BA_ "GenSigSendType" SG_ 346 IMPACTCommand 5;
BA_ "Event trans." SG_ 346 IMPACTConfirm 0;
BA_ "GenSigStartValue" SG_ 346 IMPACTConfirm 1;
BA_ "GenSigInactiveValue" SG_ 346 IMPACTConfirm 1;
BA_ "GenSigSendType" SG_ 346 IMPACTConfirm 5;
BA_ "Event trans." SG_ 346 IMPACTFailSts 0;
BA_ "GenSigSendType" SG_ 346 IMPACTFailSts 5;
BA_ "GenSigStartValue" SG_ 1058 IBS3_Ibatt 65535;
BA_ "GenSigStartValue" SG_ 1058 IBS3_Rbatt 255;
BA_ "GenSigStartValue" SG_ 1058 IBS3_Rbatt_25 255;
BA_ "GenSigStartValue" SG_ 1058 IBS3_SOF_V_Accuracy 1;
BA_ "GenSigStartValue" SG_ 1058 IBS3_Vbatt 511;
BA_ "GenSigStartValue" SG_ 1060 IBS3_SOC 127;
BA_ "GenSigStartValue" SG_ 1060 IBS3_SOC_Accuracy 1;
BA_ "GenSigStartValue" SG_ 1060 IBS3_SOF_Q 255;
BA_ "GenSigStartValue" SG_ 1060 IBS3_SOF_Q_Accuracy 1;
BA_ "GenSigStartValue" SG_ 1060 IBS3_SOH_Q 127;
BA_ "GenSigStartValue" SG_ 1060 IBS3_SOH_Q_Accuracy 1;
BA_ "GenSigStartValue" SG_ 1060 IBS3_T_BATT 255;
BA_ "GenSigStartValue" SG_ 1062 IBS3_Q_Received 65535;
BA_ "GenSigStartValue" SG_ 1062 IBS3_Q_Released 65535;
BA_ "GenSigStartValue" SG_ 500 EngTrqDrvReqMod 8191;
BA_ "GenSigStartValue" SG_ 500 ESS_ENG_ST 15;
BA_ "GenSigStartValue" SG_ 1047 AtmosphericPressure 255;
BA_ "GenSigStartValue" SG_ 1047 EngMaxRPM 255;
BA_ "GenSigStartValue" SG_ 1047 IntakeAirTemperature 65;
BA_ "Accuracy" SG_ 1042 CARB_PERM "-";
BA_ "Accuracy" SG_ 1042 CarbWarmUp "-";
BA_ "Accuracy" SG_ 1042 CldStrtDenominator "-";
BA_ "Accuracy" SG_ 1042 ECM_CODE_CLR "-";
BA_ "Accuracy" SG_ 1042 ECM_READINESS_RESET "-";
BA_ "Accuracy" SG_ 1042 EngineOFFTime "-";
BA_ "GenSigStartValue" SG_ 1042 EngineOFFTime 1023;
BA_ "Accuracy" SG_ 1042 GenDenominator "-";
BA_ "Accuracy" SG_ 1042 IgnCntrTrue "-";
BA_ "Accuracy" SG_ 1042 Inp_CSD_Fail "-";
BA_ "Accuracy" SG_ 1042 Inp_ICC_Fail "-";
BA_ "Accuracy" SG_ 1042 InputsGDFail "-";
BA_ "Event trans." SG_ 1848 KeyProgramSts 0;
BA_ "GenSigSendType" SG_ 1848 KeyProgramSts 3;
BA_ "Event trans." SG_ 1848 MsgFOBLeftVeh 0;
BA_ "GenSigSendType" SG_ 1848 MsgFOBLeftVeh 3;
BA_ "Event trans." SG_ 1848 MsgFOBNotFnd 0;
BA_ "GenSigSendType" SG_ 1848 MsgFOBNotFnd 3;
BA_ "Event trans." SG_ 1848 MsgNotInPark 0;
BA_ "GenSigSendType" SG_ 1848 MsgNotInPark 3;
BA_ "Event trans." SG_ 1848 MsgParkSoon 0;
BA_ "GenSigSendType" SG_ 1848 MsgParkSoon 3;
BA_ "Event trans." SG_ 1848 MsgPutInPark 0;
BA_ "GenSigSendType" SG_ 1848 MsgPutInPark 3;
BA_ "Event trans." SG_ 1848 MsgServPEKG 0;
BA_ "GenSigSendType" SG_ 1848 MsgServPEKG 3;
BA_ "Event trans." SG_ 762 CRC_CSWC_1 0;
BA_ "GenSigSendType" SG_ 762 CRC_CSWC_1 1;
BA_ "Event trans." SG_ 762 CruiseControlFailSts 0;
BA_ "GenSigSendType" SG_ 762 CruiseControlFailSts 1;
BA_ "Event trans." SG_ 762 CruiseControlOnOffSts 0;
BA_ "GenSigSendType" SG_ 762 CruiseControlOnOffSts 1;
BA_ "Event trans." SG_ 762 Lifter_OnOffSts 0;
BA_ "GenSigSendType" SG_ 762 Lifter_OnOffSts 1;
BA_ "Event trans." SG_ 762 MC_CSWC_1 0;
BA_ "GenSigSendType" SG_ 762 MC_CSWC_1 1;
BA_ "Event trans." SG_ 762 SpeedRockerSts 0;
BA_ "GenSigSendType" SG_ 762 SpeedRockerSts 1;
BA_ "Accuracy" SG_ 2654339073 CurrentFailSts_ECM "-";
BA_ "Accuracy" SG_ 2654339073 DES_ECM "-";
BA_ "Accuracy" SG_ 2654339073 EOL_ECM "-";
BA_ "Accuracy" SG_ 2654339073 GenericFailSts_ECM "-";
BA_ "Accuracy" SG_ 2654339075 CurrentFailSts_IPC "-";
BA_ "Accuracy" SG_ 2654339075 DES_IPC "-";
BA_ "Accuracy" SG_ 2654339075 EOL_IPC "-";
BA_ "Accuracy" SG_ 2654339075 GenericFailSts_IPC "-";
BA_ "Accuracy" SG_ 2654339137 CurrentFailSts_RFHM "-";
BA_ "Accuracy" SG_ 2654339137 DES_RFHM "-";
BA_ "Accuracy" SG_ 2654339137 EOL_RFHM "-";
BA_ "Accuracy" SG_ 2654339137 GenericFailSts_RFHM "-";
BA_ "Accuracy" SG_ 2654339107 CurrentFailSts_TBM "-";
BA_ "Accuracy" SG_ 2654339107 DES_TBM "-";
BA_ "Accuracy" SG_ 2654339107 EOL_TBM "-";
BA_ "Accuracy" SG_ 2654339107 GenericFailSts_TBM "-";
BA_ "Accuracy" SG_ 2654339083 CurrentFailSts_Transmission "-";
BA_ "Accuracy" SG_ 2654339083 DES_Transmission "-";
BA_ "Accuracy" SG_ 2654339083 EOL_Transmission "-";
BA_ "Accuracy" SG_ 2654339083 GenericFailSts_Transmission "-";
BA_ "Accuracy" SG_ 508 ADC_STS "-";
BA_ "Accuracy" SG_ 508 CDCM_WarningLamp "-";
BA_ "Accuracy" SG_ 508 Lifter_FailSts "-";
BA_ "Accuracy" SG_ 508 LifterCrankReq "-";
BA_ "Accuracy" SG_ 508 LifterInfoDisplay "-";
BA_ "Accuracy" SG_ 508 LifterPosition "-";
BA_ "Accuracy" SG_ 508 LifterSts "-";
BA_ "Accuracy" SG_ 508 RdAspInd "-";
BA_ "Accuracy" SG_ 508 Rear_Diff_Control_Sts "-";
BA_ "Accuracy" SG_ 508 Rear_Diff_WarningLamp "-";
BA_ "Accuracy" SG_ 1454 ChkFuelCap "-";
BA_ "Event trans." SG_ 1454 ChkFuelCap 0;
BA_ "GenSigSendType" SG_ 1454 ChkFuelCap 3;
BA_ "Accuracy" SG_ 1454 CompressorSts "-";
BA_ "Event trans." SG_ 1454 CompressorSts 0;
BA_ "GenSigStartValue" SG_ 1454 CompressorSts 2;
BA_ "GenSigSendType" SG_ 1454 CompressorSts 3;
BA_ "Accuracy" SG_ 1454 EMSFailSts "-";
BA_ "Event trans." SG_ 1454 EMSFailSts 0;
BA_ "GenSigStartValue" SG_ 1454 EMSFailSts 2;
BA_ "GenSigSendType" SG_ 1454 EMSFailSts 3;
BA_ "Event trans." SG_ 1454 EngineOperatingMode 0;
BA_ "GenSigSendType" SG_ 1454 EngineOperatingMode 3;
BA_ "Accuracy" SG_ 1454 EngineWaterTempWarningLightSts "-";
BA_ "Event trans." SG_ 1454 EngineWaterTempWarningLightSts 0;
BA_ "GenSigSendType" SG_ 1454 EngineWaterTempWarningLightSts 3;
BA_ "Accuracy" SG_ 1454 ETCFailSts "-";
BA_ "Event trans." SG_ 1454 ETCFailSts 0;
BA_ "GenSigSendType" SG_ 1454 ETCFailSts 3;
BA_ "Event trans." SG_ 1454 ExhaustTemperature 0;
BA_ "GenSigSendType" SG_ 1454 ExhaustTemperature 3;
BA_ "Accuracy" SG_ 1454 GPFServiceSts "-";
BA_ "Event trans." SG_ 1454 GPFServiceSts 0;
BA_ "GenSigSendType" SG_ 1454 GPFServiceSts 3;
BA_ "Accuracy" SG_ 1454 GPFSts "-";
BA_ "Event trans." SG_ 1454 GPFSts 0;
BA_ "GenSigSendType" SG_ 1454 GPFSts 3;
BA_ "Accuracy" SG_ 1454 OilLifeSts "-";
BA_ "Event trans." SG_ 1454 OilLifeSts 0;
BA_ "GenSigSendType" SG_ 1454 OilLifeSts 3;
BA_ "Accuracy" SG_ 1454 OilPressureFailSts "-";
BA_ "Event trans." SG_ 1454 OilPressureFailSts 0;
BA_ "GenSigSendType" SG_ 1454 OilPressureFailSts 3;
BA_ "Accuracy" SG_ 1454 OilPressureSts "-";
BA_ "Event trans." SG_ 1454 OilPressureSts 0;
BA_ "GenSigStartValue" SG_ 1454 OilPressureSts 1;
BA_ "GenSigSendType" SG_ 1454 OilPressureSts 3;
BA_ "Accuracy" SG_ 1057 RrLkTrq "-";
BA_ "GenSigStartValue" SG_ 1504 EPBAutoAppSts 1;
BA_ "Event trans." SG_ 1504 FastTransmission_SE 0;
BA_ "GenSigSendType" SG_ 1504 FastTransmission_SE 5;
BA_ "Accuracy" SG_ 1196 InflationState_LHF_Tyre1 "-";
BA_ "Event trans." SG_ 1196 InflationState_LHF_Tyre1 0;
BA_ "GenSigSendType" SG_ 1196 InflationState_LHF_Tyre1 4;
BA_ "Accuracy" SG_ 1196 InflationState_LHR_Tyre1 "-";
BA_ "Event trans." SG_ 1196 InflationState_LHR_Tyre1 0;
BA_ "GenSigSendType" SG_ 1196 InflationState_LHR_Tyre1 4;
BA_ "Accuracy" SG_ 1196 InflationState_RHF_Tyre1 "-";
BA_ "Event trans." SG_ 1196 InflationState_RHF_Tyre1 0;
BA_ "GenSigSendType" SG_ 1196 InflationState_RHF_Tyre1 4;
BA_ "Accuracy" SG_ 1196 InflationState_RHR_Tyre1 "-";
BA_ "Event trans." SG_ 1196 InflationState_RHR_Tyre1 0;
BA_ "GenSigSendType" SG_ 1196 InflationState_RHR_Tyre1 4;
BA_ "Accuracy" SG_ 1196 PressureValue_LHF_Tyre "+/- 0,1 bar";
BA_ "Accuracy" SG_ 1196 PressureValue_LHR_Tyre "+/- 0,1 bar";
BA_ "Accuracy" SG_ 1196 PressureValue_RHF_Tyre "+/- 0,1 bar";
BA_ "Accuracy" SG_ 1196 PressureValue_RHR_Tyre "+/- 0,1 bar";
BA_ "Accuracy" SG_ 1196 TPMActivitySts "-";
BA_ "Accuracy" SG_ 1196 TyrePressureSysProgrammedSts "-";
BA_ "Event trans." SG_ 1196 TyrePressureSysProgrammedSts 0;
BA_ "GenSigSendType" SG_ 1196 TyrePressureSysProgrammedSts 4;
BA_ "Accuracy" SG_ 1196 TyrePressureSystemFailSts1 "-";
BA_ "Event trans." SG_ 1196 TyrePressureSystemFailSts1 0;
BA_ "GenSigSendType" SG_ 1196 TyrePressureSystemFailSts1 4;
BA_ "Accuracy" SG_ 1850 Day1 "-";
BA_ "Accuracy" SG_ 1850 Day2 "-";
BA_ "Accuracy" SG_ 1850 Hour1 "-";
BA_ "Accuracy" SG_ 1850 Hour2 "-";
BA_ "Accuracy" SG_ 1850 Minute1 "-";
BA_ "Accuracy" SG_ 1850 Minute2 "-";
BA_ "Accuracy" SG_ 1850 Month1 "-";
BA_ "Accuracy" SG_ 1850 Month2 "-";
BA_ "Accuracy" SG_ 1850 Year1 "-";
BA_ "Accuracy" SG_ 1850 Year2 "-";
BA_ "Accuracy" SG_ 1850 Year3 "-";
BA_ "Accuracy" SG_ 1850 Year4 "-";
BA_ "GenSigStartValue" SG_ 503 FANRequestNCA 3;
BA_ "GenSigStartValue" SG_ 503 OUTPUT_SPEED 65535;
BA_ "GenSigStartValue" SG_ 503 TRNS_StpSt_FLT 1;
BA_ "Event trans." SG_ 1448 BuzzerReqSts_T2 0;
BA_ "GenSigSendType" SG_ 1448 BuzzerReqSts_T2 3;
BA_ "Event trans." SG_ 1448 CrankEnable 0;
BA_ "GenSigSendType" SG_ 1448 CrankEnable 3;
BA_ "Event trans." SG_ 1448 DriveModeSts 0;
BA_ "GenSigSendType" SG_ 1448 DriveModeSts 3;
BA_ "Event trans." SG_ 1448 GearEngaged 0;
BA_ "GenSigSendType" SG_ 1448 GearEngaged 3;
BA_ "Event trans." SG_ 1448 GearIndicationSts 0;
BA_ "GenSigSendType" SG_ 1448 GearIndicationSts 3;
BA_ "Event trans." SG_ 1448 LeverPosition 0;
BA_ "GenSigSendType" SG_ 1448 LeverPosition 3;
BA_ "Event trans." SG_ 1448 LimpHomeSts 0;
BA_ "GenSigSendType" SG_ 1448 LimpHomeSts 3;
BA_ "Event trans." SG_ 1448 MIReq 0;
BA_ "GenSigSendType" SG_ 1448 MIReq 3;
BA_ "Event trans." SG_ 1448 OilTemperatureSts 0;
BA_ "GenSigSendType" SG_ 1448 OilTemperatureSts 3;
BA_ "Event trans." SG_ 1448 ParkingFailSts 0;
BA_ "GenSigSendType" SG_ 1448 ParkingFailSts 3;
BA_ "Event trans." SG_ 1448 ShiftInProgress 0;
BA_ "GenSigSendType" SG_ 1448 ShiftInProgress 3;
BA_ "Event trans." SG_ 1448 ShiftLeverPosition 0;
BA_ "GenSigSendType" SG_ 1448 ShiftLeverPosition 3;
BA_ "Event trans." SG_ 1448 ShiftModeSts 0;
BA_ "GenSigSendType" SG_ 1448 ShiftModeSts 3;
BA_ "Event trans." SG_ 1448 TargetGear 0;
BA_ "GenSigStartValue" SG_ 1448 TargetGear 15;
BA_ "GenSigSendType" SG_ 1448 TargetGear 3;
BA_ "Event trans." SG_ 1448 TempManualOverride 0;
BA_ "GenSigSendType" SG_ 1448 TempManualOverride 3;
BA_ "Event trans." SG_ 1448 TemporaryManualSts 0;
BA_ "GenSigSendType" SG_ 1448 TemporaryManualSts 3;
BA_ "Event trans." SG_ 1448 TransmissionFailSts 0;
BA_ "GenSigSendType" SG_ 1448 TransmissionFailSts 3;
BA_ "Event trans." SG_ 1448 TransmissionWarnings 0;
BA_ "GenSigSendType" SG_ 1448 TransmissionWarnings 3;
BA_ "Event trans." SG_ 1448 TxDisengaged 0;
BA_ "GenSigSendType" SG_ 1448 TxDisengaged 3;
BA_ "GenSigStartValue" SG_ 234 ReqSlowTorqueValue 2047;
BA_ "Accuracy" SG_ 253 ControlEncoding_TRM_Rsp "-";
BA_ "Event trans." SG_ 253 ControlEncoding_TRM_Rsp 0;
BA_ "GenSigSendType" SG_ 253 ControlEncoding_TRM_Rsp 3;
BA_ "GenSigStartValue" SG_ 253 TxpFound 1;
BA_ "Accuracy" SG_ 243 FrameNumber "-";
BA_ "Event trans." SG_ 243 FrameNumber 0;
BA_ "GenSigSendType" SG_ 243 FrameNumber 1;
BA_ "Accuracy" SG_ 243 TotalFrameNumber "-";
BA_ "GenSigStartValue" SG_ 1046 VIN_MSG 3;
BA_ "Accuracy" SG_ 2654208000 MainWakeSts_BCM "-";
BA_ "Accuracy" SG_ 2654208000 Node0 "-";
BA_ "Accuracy" SG_ 2654208000 Node1 "-";
BA_ "Accuracy" SG_ 2654208000 Node10 "-";
BA_ "Accuracy" SG_ 2654208000 Node11 "-";
BA_ "Accuracy" SG_ 2654208000 Node12 "-";
BA_ "Accuracy" SG_ 2654208000 Node13 "-";
BA_ "Accuracy" SG_ 2654208000 Node14 "-";
BA_ "Accuracy" SG_ 2654208000 Node15 "-";
BA_ "Accuracy" SG_ 2654208000 Node16 "-";
BA_ "Accuracy" SG_ 2654208000 Node17 "-";
BA_ "Accuracy" SG_ 2654208000 Node18 "-";
BA_ "Accuracy" SG_ 2654208000 Node19 "-";
BA_ "Accuracy" SG_ 2654208000 Node2 "-";
BA_ "Accuracy" SG_ 2654208000 Node20 "-";
BA_ "Accuracy" SG_ 2654208000 Node21 "-";
BA_ "Accuracy" SG_ 2654208000 Node22 "-";
BA_ "Accuracy" SG_ 2654208000 Node23 "-";
BA_ "Accuracy" SG_ 2654208000 Node24 "-";
BA_ "Accuracy" SG_ 2654208000 Node25 "-";
BA_ "Accuracy" SG_ 2654208000 Node26 "-";
BA_ "Accuracy" SG_ 2654208000 Node27 "-";
BA_ "Accuracy" SG_ 2654208000 Node28 "-";
BA_ "Accuracy" SG_ 2654208000 Node29 "-";
BA_ "Accuracy" SG_ 2654208000 Node3 "-";
BA_ "Accuracy" SG_ 2654208000 Node30 "-";
BA_ "Accuracy" SG_ 2654208000 Node31 "-";
BA_ "Accuracy" SG_ 2654208000 Node4 "-";
BA_ "Accuracy" SG_ 2654208000 Node5 "-";
BA_ "Accuracy" SG_ 2654208000 Node6 "-";
BA_ "Accuracy" SG_ 2654208000 Node7 "-";
BA_ "Accuracy" SG_ 2654208000 Node8 "-";
BA_ "Accuracy" SG_ 2654208000 Node9 "-";
BA_ "Accuracy" SG_ 2654208000 WakeCntr_BCM "-";
BA_ "Accuracy" SG_ 2654208000 WakeRsn_BCM "-";
BA_ "GenSigStartValue" SG_ 2654208006 WakeUpNodeAddress 1;
BA_ "GenSigStartValue" SG_ 2654208003 WakeUpNodeAddress 6;
BA_ "GenSigStartValue" SG_ 2654208065 WakeUpNodeAddress 21;
BA_ "GenSigStartValue" SG_ 2654208011 WakeUpNodeAddress 8;
BA_ "Accuracy" SG_ 278 CRC_WI "-";
BA_ "Accuracy" SG_ 278 LHF_FastPulseCounter "-";
BA_ "Accuracy" SG_ 278 LHF_Spin "-";
BA_ "Accuracy" SG_ 278 LHF_WheelSensorFailSts "-";
BA_ "Accuracy" SG_ 278 LHR_FastPulseCounter "-";
BA_ "Accuracy" SG_ 278 LHR_Spin "-";
BA_ "Accuracy" SG_ 278 LHR_WheelSensorFailSts "-";
BA_ "Accuracy" SG_ 278 MessageCounter_WI "-";
BA_ "Accuracy" SG_ 278 RHF_FastPulseCounter "-";
BA_ "Accuracy" SG_ 278 RHF_Spin "-";
BA_ "Accuracy" SG_ 278 RHF_WheelSensorFailSts "-";
BA_ "Accuracy" SG_ 278 RHR_FastPulseCounter "-";
BA_ "Accuracy" SG_ 278 RHR_Spin "-";
BA_ "Accuracy" SG_ 278 RHR_WheelSensorFailSts "-";
BA_ "Accuracy" SG_ 238 LHFWheelSpeed "-";
BA_ "Accuracy" SG_ 238 LHRWheelSpeed "-";
BA_ "Accuracy" SG_ 238 RHFWheelSpeed "-";
BA_ "Accuracy" SG_ 238 RHRWheelSpeed "-";
VAL_ 1051 ACPressure 511 "SNA" ;
VAL_ 1051 ACPressureFailSts 0 "Fail_Not_Present" 1 "Fail_Present" ;
VAL_ 1051 Feedback_DTCM 0 "Valid" 1 "Not_Valid" ;
VAL_ 1051 MinEngineTorqueAcc 2047 "SNA" ;
VAL_ 255 EngineTorqueDriverReq 2047 "SNA" ;
VAL_ 255 FpsActuated 0 "Not_Actuated" 1 "Actuated" ;
VAL_ 255 FpsNotActuable 0 "FPS_Actuable" 1 "FPS_Not_Actuable" ;
VAL_ 255 LV12PwrFreeRq 0 "Level 1 or 2 Power free Mode NOT active" 1 "Level 1 or 2 Power free Mode Active" ;
VAL_ 255 MaxEngineTorque 2047 "SNA" ;
VAL_ 255 MinEngineTorque 2047 "SNA" ;
VAL_ 255 PowertrainPrplsnActv 0 "OFF" 1 "ON" ;
VAL_ 251 CrankHold 0 "Not_Active" 1 "Active" ;
VAL_ 251 EngineFrictionTorque 511 "SNA" ;
VAL_ 251 EngineTorque 2047 "SNA" ;
VAL_ 251 FeedbackASR_ESCReq 0 "TorqueReq_ASR_ESCValid" 1 "TorqueReq_ASR_ESCNot_Valid" ;
VAL_ 251 GasPedalAct 0 "Not_active" 1 "Active" ;
VAL_ 251 GasPedalGradient 255 "SNA" ;
VAL_ 251 StartRelayBCMCmd 0 "Not_Action" 1 "Action" ;
VAL_ 496 ActualPedalPos 255 "SNA" ;
VAL_ 749 EngineWaterTemp 255 "SNA" ;
VAL_ 749 EngineWaterTempFailSts 0 "Fail_Not_Present" 1 "Fail_Present" ;
VAL_ 749 FuelConsumption_GAG3 1048575 "SNA" ;
VAL_ 749 GearShiftIndication 0 "No_Gearshift_Suggestion_by_ECM" 1 "Downshift_Suggestion_by_ECM" 2 "Upshift_Suggestion_by_ECM" 3 "Strategy_Not_Available_ECM_Fail" ;
VAL_ 749 RaceShiftLight 0 "No_RaceGearshift_Suggestion" 1 "Urgency_Level_1" 2 "Urgency_Level_2" 3 "Urgency_Level_3" ;
VAL_ 751 ActualGearGSI 0 "Neutral" 1 "ForwardGear_1" 2 "ForwardGear_2" 3 "ForwardGear_3" 4 "ForwardGear_4" 5 "ForwardGear_5" 6 "ForwardGear_6" 7 "ReverseGear" 8 "ForwardGear_7" 9 "ForwardGear_8" 10 "ForwardGear_9" 15 "SNA" ;
VAL_ 751 BoostPressureIndication 255 "SNA" ;
VAL_ 751 LowFuelMIL 0 "Not_Active" 1 "Active" ;
VAL_ 751 SAMInfo 0 "SAMOFF" 1 "Engine_OFF" 2 "Cranking_management" 3 "ColdEngineManagement" 4 "PassiveBoost" 5 "Steady_State" 6 "RegenerativeBraking" 7 "QuickCharge" 8 "Auto_Shut_OFF" 9 "Shut_OFF" 10 "SAM_recovery" 11 "Battery_Regeneration" 12 "Not_Used" 13 "Not_Used" 14 "Not_Used" 15 "SNA" ;
VAL_ 751 StartRelayBCMFeedbackFault 0 "False" 1 "True" ;
VAL_ 751 StartRelayECMFeedbackFault 0 "False" 1 "True" ;
VAL_ 751 StopStartFaultSts 0 "False" 1 "True" ;
VAL_ 751 SuggestedGearGSI 0 "Neutral" 1 "ForwardGear_1" 2 "ForwardGear_2" 3 "ForwardGear_3" 4 "ForwardGear_4" 5 "ForwardGear_5" 6 "ForwardGear_6" 7 "ReverseGear" 8 "ForwardGear_7" 9 "ForwardGear_8" 10 "ForwardGear_9" 15 "SNA" ;
VAL_ 550 ECMLnchCtrlAllowed 0 "Not_Allowed" 1 "Allowed" ;
VAL_ 550 SpStChmRq 0 "Not_Active" 1 "Active" ;
VAL_ 550 SpStDispstat 0 "NONE" 1 "STARTING" 2 "START" 3 "ACTIVE" 4 "D_OR_SB" 5 "D_AND_SB" 6 "DR_INHIB" 7 "TX_INHIB" 8 "KEY" 9 "BATT" 10 "SYSFLT" 11 "NR" 12 "READY" 13 "OFF" 14 "HOOD" 15 "PEDAL" 16 "BATT_CHG" 17 "TM" 18 "T4WD_L" 19 "LF" 20 "INCLINE" 21 "AMB_TEMP" 22 "ENG_TEMP" 23 "SB" 24 "DR_AJAR" 25 "CABIN" 26 "MAX_HVAC" 27 "FT_DEFROST" 28 "EBL" 29 "ST_WHEEL" 30 "ENG_TEMP_HI" 31 "ENG_TEMP_LO" 32 "PRK_BRK_INHIB" 33 "PARK_INHIBIT" 34 "HOOD_INHIBIT" 35 "DPF_REGEN" 36 "PSG_DR_INHIB" 37 "ACC_SET" 38 "BATT_HIGH" 39 "BATT_LOW" 63 "SNA" ;
VAL_ 550 SpStIndRq 0 "Not_Active" 1 "Active" ;
VAL_ 550 SpStSwStat 0 "OFF" 1 "CONT" 2 "BLINK" 3 "SNA" ;
VAL_ 550 SpStWarnStat 0 "NONE" 1 "STARTING" 2 "START" 3 "ACTIVE" 4 "D_OR_SB" 5 "D_AND_SB" 6 "DR_INHIB" 7 "TX_INHIB" 8 "KEY" 9 "BATT" 10 "SYSFLT" 11 "PRK_BRK_INHIB" 12 "HOOD_INHIB" 13 "PSG_DR_INHIB" 14 "PARK_INHIB" 15 "SNA" ;
VAL_ 1854 HighBeamSts 0 "OFF" 1 "ON" ;
VAL_ 1854 LHParkingLightSts 0 "OFF" 1 "ON" ;
VAL_ 1854 LHTurnLightFault 0 "False" 1 "True" ;
VAL_ 1854 LHTurnSignalSts 0 "OFF" 1 "ON" ;
VAL_ 1854 ParkingLightFault 0 "False" 1 "True" ;
VAL_ 1854 RHParkingLightSts 0 "OFF" 1 "ON" ;
VAL_ 1854 RHTurnLightFault 0 "False" 1 "True" ;
VAL_ 1854 RHTurnSignalSts 0 "OFF" 1 "ON" ;
VAL_ 1854 StopLightFault 0 "False" 1 "True" ;
VAL_ 1854 StopLightSts 0 "OFF" 1 "ON" ;
VAL_ 222 ElectricSteeringFailSts 0 "Fail_Not_Present" 1 "Fail_Present" ;
VAL_ 222 EngineFanRequestActivation 0 "False" 1 "True" ;
VAL_ 222 LwsAngle 65535 "SNA" ;
VAL_ 222 LwsCalibration 0 "Not_calibrated" 1 "Calibrated" ;
VAL_ 222 LWSFailSts 0 "Fail_not_Present" 1 "Fail_Present_Ignition_Latched" 2 "Fail_Present_Recoverable" 3 "Fail_Present_Battery_Disconnection" ;
VAL_ 222 LwsSpeed 4095 "SNA" ;
VAL_ 100 ControlEncodingReq 5 "ControlEncoding_ENQ" 6 "ControlEncoding_ACK" 21 "ControlEncoding_NACK" 132 "ControlEncoding_EOTp" 133 "ControlEncoding_ENQp" 134 "ControlEncoding_ACK1p" 135 "ControlEncoding_ACK2p" ;
VAL_ 100 f1_1 0 "Val1_f1_1" 81 "Val5_f1_1" 119 "Val2_f1_1" 145 "Val3_f1_1" 159 "Val4_f1_1" ;
VAL_ 100 f1_2 0 "Val1_f1_2" 5 "Val2_f1_2" 13 "Val4_f1_2" 14 "Val3_f1_2" 15 "Val5_f1_2" ;
VAL_ 100 rnd_1 0 "Val1_rnd_1" 58 "Val2_rnd_1" 59 "Val3_rnd_1" 60 "Val4_rnd_1" 61 "Val5_rnd_1" 62 "Val6_rnd_1" 63 "Val7_rnd_1" 64 "Val8_rnd_1" 65 "Val9_rnd_1" 66 "ValA_rnd_1" 67 "ValB_rnd_1" 68 "ValC_rnd_1" 69 "ValD_rnd_1" 70 "ValE_rnd_1" 71 "ValF_rnd_1" ;
VAL_ 100 rnd_2 0 "Val1_rnd_2" 26 "Val3_rnd_2" 43 "Val5_rnd_2" 79 "Val2_rnd_2" 168 "Val4_rnd_2" ;
VAL_ 100 rnd_3 0 "Val1_rnd_3" 19 "Val3_rnd_3" 21 "Val5_rnd_3" 32 "Val4_rnd_3" 129 "Val2_rnd_3" ;
VAL_ 100 rnd_4 0 "Val1_rnd_4" 170 "Val5_rnd_4" 203 "Val2_rnd_4" 221 "Val3_rnd_4" 238 "Val4_rnd_4" ;
VAL_ 104 MKKey_3 36 "FIX__MKKey_3" ;
VAL_ 104 MKKey_4 214 "FIX__MKKey_4" ;
VAL_ 104 MKKey_5 1 "FIX__MKKey_5" ;
VAL_ 104 MKKey_6 77 "FIX__MKKey_6" ;
VAL_ 104 MKKey1org21 84 "FIX__MKKey_1" ;
VAL_ 104 MKKey2org22 85 "FIX__MKKey_2" ;
VAL_ 346 IMPACT_A 0 "Do_Not_Actuate" 1 "Actuate" ;
VAL_ 346 IMPACT_B 0 "Do_Not_Actuate" 1 "Actuate" ;
VAL_ 346 IMPACT_C 0 "Do_Not_Actuate" 1 "Actuate" ;
VAL_ 346 IMPACT_D 0 "Do_Not_Actuate" 1 "Actuate" ;
VAL_ 346 IMPACT_E 0 "Do_Not_Actuate" 1 "Actuate" ;
VAL_ 346 IMPACT_F 0 "Do_Not_Actuate" 1 "Actuate" ;
VAL_ 346 IMPACT_G 0 "Do_Not_Actuate" 1 "Actuate" ;
VAL_ 346 IMPACT_H 0 "Do_Not_Actuate" 1 "Actuate" ;
VAL_ 346 IMPACT_I 0 "Do_Not_Actuate" 1 "Actuate" ;
VAL_ 346 IMPACT_K 0 "Do_Not_Actuate" 1 "Actuate" ;
VAL_ 346 IMPACT_L 0 "Do_Not_Actuate" 1 "Actuate" ;
VAL_ 346 IMPACT_M 0 "Do_Not_Actuate" 1 "Actuate" ;
VAL_ 346 IMPACT_O 0 "Do_Not_Actuate" 1 "Actuate" ;
VAL_ 346 IMPACTCommand 0 "Do_Not_Actuate" 1 "Actuate" ;
VAL_ 346 IMPACTConfirm 0 "Actuate" 1 "Do_Not_Actuate" ;
VAL_ 346 IMPACTFailSts 0 "Fail_Not_Present" 1 "Fail_Present" ;
VAL_ 1058 CurrBattFailStatus 0 "Fail_not_present" 1 "Fail_present" ;
VAL_ 1058 IBS3_Error_Internal 0 "No_error" 1 "Error" ;
VAL_ 1058 IBS3_Flag_Disconnect 0 "No_disconnect_since_last_key_cycle" 1 "Battery_disconnected_since_last_key_cycle" ;
VAL_ 1058 IBS3_Ibatt 65535 "SNA" ;
VAL_ 1058 IBS3_Rbatt 255 "SNA" ;
VAL_ 1058 IBS3_Rbatt_25 255 "SNA" ;
VAL_ 1058 IBS3_SOF_V_Accuracy 0 "Inaccurate" 1 "Accurate" ;
VAL_ 1058 IBS3_SOF_VC 127 "SNA" ;
VAL_ 1058 IBS3_Vbatt 511 "SNA" ;
VAL_ 1058 RsErrIBS3 0 "No_error" 1 "Error" ;
VAL_ 1058 VoltBattFailStatus 0 "Fail_not_present" 1 "Fail_present" ;
VAL_ 1060 IBS3_SOC 127 "SNA" ;
VAL_ 1060 IBS3_SOC_Accuracy 0 "Inaccurate" 1 "Accurate" ;
VAL_ 1060 IBS3_SOF_Q 255 "SNA" ;
VAL_ 1060 IBS3_SOF_Q_Accuracy 0 "Inaccurate" 1 "Accurate" ;
VAL_ 1060 IBS3_SOH_Q 127 "SNA" ;
VAL_ 1060 IBS3_SOH_Q_Accuracy 0 "Inaccurate" 1 "Accurate" ;
VAL_ 1060 IBS3_T_BATT 255 "SNA" ;
VAL_ 1060 IBS3_TempFailStatus 0 "Fail_not_present" 1 "Fail_present" ;
VAL_ 1062 IBS3_Q_Received 65535 "SNA" ;
VAL_ 1062 IBS3_Q_Released 65535 "SNA" ;
VAL_ 1062 IBS3_TmLstResetDays 4095 "SNA" ;
VAL_ 1062 IBS3_TmLstResetSec 65535 "SNA" ;
VAL_ 256 ECM_LHOM 0 "Not_In_Limp_Home" 1 "In_Limp_Home" ;
VAL_ 244 CANErr 1 "NoCanMessage" 2 "UnplausibleMessage" 4 "UnplausibleCommand" 8 "NotUsed" ;
VAL_ 244 CylCutEnabled 0 "Not_Active" 1 "Cut_Off_Enabled" ;
VAL_ 244 EngineAtLimiter 0 "Not_Active" 1 "Speed_Limiter_Active" ;
VAL_ 244 EngineIdleRefSpeed 4095 "SNA" ;
VAL_ 244 EngineSlaveModeActive 0 "Not_Active" 1 "Slave_Mode_Active" ;
VAL_ 244 EngTorqueTargetWONCR 2047 "SNA" ;
VAL_ 244 FutureTorque 2047 "SNA" ;
VAL_ 244 NmaxControllerActive 0 "Not_Active" 1 "Speed_Control_Active" ;
VAL_ 244 Psben 0 "Not_Active" 1 "Active" ;
VAL_ 500 EngineReadyForESS 0 "Not_Active" 1 "Active" ;
VAL_ 500 EngTrqDrvReqMod 8191 "SNA" ;
VAL_ 500 ESS_ENG_ST 1 "ENS Stopped / ENS_STOPPED" 2 "ENS Request Start / ENS_RQ_ST" 3 "ENS Running / ENS_RUN" 4 "ENS Stop Pending / ENS_STOP_PEND" 5 "ENS Start protection / ENS_ST_PRTCT" 6 "ENS Start inhibit / ENS_ST_INH" 7 "ENS disabled / ENS_DSBL" 8 "ENS_IHB_LATCH" 9 "ENS Starting / ENS_Starting" 10 "ENS e_creeping /ENS_E_CREEPING" 11 "ENS request BSG Start / ENS_RQ_BSG_ST" 12 "ENS e_idling / ENS_E_IDLING" 15 "SNA" ;
VAL_ 500 GrMax_Rq_ECM 0 "Passive" 1 "G1" 2 "G2" 3 "G3" 4 "G4" 5 "G5" 6 "G6" 7 "G7" 8 "G8" 9 "G9" ;
VAL_ 500 MaxInstTorque 2047 "SNA" ;
VAL_ 500 MinInstTorque 2047 "SNA" ;
VAL_ 1047 AtmosphericPressure 255 "SNA" ;
VAL_ 1047 AtmosphericPressureFailSts 0 "Fail_Not_Present" 1 "Fail_Present" ;
VAL_ 1047 EngMaxRPM 255 "SNA" ;
VAL_ 1047 ESS_ActvEBrake 0 "Do_Nothing" 1 "Activate E Brake" ;
VAL_ 1047 ESS_RqShftPark 0 "Do_Nothing" 1 "Shift_to_Park" ;
VAL_ 1047 IntakeAirTemperature 255 "SNA" ;
VAL_ 1047 ThermalManagementActive 0 "Not_active" 1 "Active" ;
VAL_ 1047 VehicleSetSpeed 255 "SNA" ;
VAL_ 1042 CARB_PERM 0 "False" 1 "True" ;
VAL_ 1042 CarbWarmUp 0 "False" 1 "True" ;
VAL_ 1042 CldStrtDenominator 0 "Not_Active" 1 "Active" ;
VAL_ 1042 ECM_CODE_CLR 0 "Not_Cleared" 1 "Cleared" ;
VAL_ 1042 ECM_READINESS_RESET 0 "Not_Set" 1 "Set" ;
VAL_ 1042 EngineOFFTime 1023 "SNA" ;
VAL_ 1042 GenDenominator 0 "False" 1 "True" ;
VAL_ 1042 IgnCntrTrue 0 "False" 1 "True" ;
VAL_ 1042 Inp_CSD_Fail 0 "Fail_Not_Present" 1 "Fail_Present" ;
VAL_ 1042 Inp_ICC_Fail 0 "Fail_Not_Present" 1 "Fail_Present" ;
VAL_ 1042 InputsGDFail 0 "False" 1 "True" ;
VAL_ 495 CustKeyInIgnSts 0 "CUST_KEY_DEFAULT" 1 "CUST_KEY_NOT_IN_IGNITION" 2 "CUST_KEY_IN_IGNITION" 3 "SNA" ;
VAL_ 495 DriverEngineOffRequest 0 "Not_Active" 1 "Active" ;
VAL_ 495 IgnPosSts 0 "Initialization" 1 "IGN_LK" 3 "ACC" 4 "RUN" 5 "START" 7 "SNA" ;
VAL_ 495 RFFobNum 0 "FOB_DEFAULT" 1 "FOB_1" 2 "FOB_2" 3 "FOB_3" 4 "FOB_4" 5 "FOB_5" 6 "FOB_6" 7 "FOB_7" 8 "FOB_8" 15 "SNA" ;
VAL_ 495 RFFuncReq 0 "NO_BASIC_REQUEST" 1 "LOCK_REQUEST" 2 "RELOCK_REQUEST" 3 "DRIVER_UNLOCK_REQUEST" 4 "ALL_UNLOCK_REQUEST" 5 "TRUNK_PLG_TOGGLE_REQUEST" 6 "LEFT_SLIDER_TOGGLE_REQUEST" 7 "RIGHT_SLIDER_TOGGLE_REQUEST" 8 "FLIPPER_GLASS_REQUEST" 9 "REMOTE_START_ON" 10 "REMOTE_START_OFF" 11 "GLOBAL_WINDOW_DOWN_REQUEST" 12 "OPEN_CONVERTIBLE_TOP" 13 "CLOSE_CONVERTIBLE_TOP" 14 "PANIC_TOGGLE_REQUEST" 15 "DEAD_LOCK_REQUEST" 16 "GLOBAL_WINDOWS_UP_REQUEST" 17 "HEADLIGHTS_OFF_DELAY" 18 "TRUNK_PLG_STOP_REQUEST" 19 "ABORT_CRANKING_ON_REQUEST" 20 "ABORT_CRANKING_OFF_REQUEST" 21 "PRE_COND_ON" 22 "PRE_COND_OFF" 23 "CAR_FINDER_REQUEST" 24 "AUTHENTICATION_REQUEST" 25 "LIGHTS_ON_REQUEST" 26 "LIGHTS_OFF_REQUEST" 27 "LOCK_AND_LIGHTS_OFF_REQUEST" 28 "WARNING_FOB_INSIDE" 29 "WARN_FOB_INSIDE_LIGHTS_OFF_REQ" 31 "SNA" ;
VAL_ 495 RFReq 0 "REQUESTOR_DEFAULT" 1 "REQUESTOR_RKE" 2 "REQUESTOR_PE" 3 "REQUESTOR_REMOTESTART" 4 "REQUESTOR_UCONNECT" 5 "REQUESTOR_PE_HANDSFREE" 7 "SNA" ;
VAL_ 2000 RFFuncReq_BCM 0 "NO_BASIC_REQUEST" 1 "LOCK_REQUEST" 2 "RELOCK_REQUEST" 3 "DRIVER_UNLOCK_REQUEST" 4 "ALL_UNLOCK_REQUEST" 5 "TRUNK_PLG_TOGGLE_REQUEST" 6 "LEFT_SLIDER_TOGGLE_REQUEST" 7 "RIGHT_SLIDER_TOGGLE_REQUEST" 8 "FLIPPER_GLASS_REQUEST" 9 "REMOTE_START_ON" 10 "REMOTE_START_OFF" 11 "GLOBAL_WINDOW_DOWN_REQUEST" 12 "OPEN_CONVERTIBLE_TOP" 13 "CLOSE_CONVERTIBLE_TOP" 14 "PANIC_TOGGLE_REQUEST" 15 "DEAD_LOCK_REQUEST" 16 "GLOBAL_WINDOWS_UP_REQUEST" 17 "HEADLIGHTS_OFF_DELAY" 18 "TRUNK_PLG_STOP_REQUEST" 19 "ABORT_CRANKING_ON_REQUEST" 20 "ABORT_CRANKING_OFF_REQUEST" 21 "PRE_COND_ON" 22 "PRE_COND_OFF" 23 "CAR_FINDER_REQUEST" 24 "AUTHENTICATION_REQUEST" 25 "LIGHTS_ON_REQUEST" 26 "LIGHTS_OFF_REQUEST" 27 "LOCK_AND_LIGHTS_OFF_REQUEST" 28 "WARNING_FOB_INSIDE" 29 "WARN_FOB_INSIDE_LIGHTS_OFF_REQ" 31 "SNA" ;
VAL_ 2000 RFReq_BCM 0 "REQUESTOR_DEFAULT" 1 "REQUESTOR_RKE" 2 "REQUESTOR_PE" 3 "REQUESTOR_REMOTESTART" 4 "REQUESTOR_UCONNECT" 5 "REQUESTOR_PE_HANDSFREE" 7 "SNA" ;
VAL_ 1848 KeyProgramSts 0 "RKE_NORM_STAT" 1 "EN_KEY_PROG" 2 "PROG_ACT" 3 "EX_KEY_PROG" 4 "KEY_PROG" 5 "DMG_KEY" 6 "INV_KEY" 7 "EXCD_KEY" 8 "RKE_BATT_LO" 9 "SRV_SKREEM" 10 "BTN_DLY_ACT" 11 "BTN_DLY_INACT" 12 "KEY_NOT_PROG" 15 "SNA" ;
VAL_ 1848 MsgFOBLeftVeh 0 "MSG_DEFAULT" 1 "MSG_ACTIVE" 3 "SNA" ;
VAL_ 1848 MsgFOBNotFnd 0 "MSG_DEFAULT" 1 "MSG_ACTIVE" 3 "SNA" ;
VAL_ 1848 MsgNotInPark 0 "MSG_DEFAULT" 1 "MSG_ACTIVE" 3 "SNA" ;
VAL_ 1848 MsgParkSoon 0 "Not_Active" 1 "Active" ;
VAL_ 1848 MsgPutInPark 0 "MSG_DEFAULT" 1 "MSG_ACTIVE" 3 "SNA" ;
VAL_ 1848 MsgServPEKG 0 "MSG_DEFAULT" 1 "MSG_ACTIVE" 3 "SNA" ;
VAL_ 1848 PowerModeSts_RFHM 0 "Standard Power" 1 "Logistic Mode ON" 2 "Logistic_Mode_PR" 3 "Not_Used" ;
VAL_ 762 CruiseControlFailSts 0 "Not_Present" 1 "Present" ;
VAL_ 762 CruiseControlOnOffSts 0 "Not_Pressed" 1 "Pressed" ;
VAL_ 762 Lifter_OnOffSts 0 "Not_Active" 1 "Active" ;
VAL_ 762 SpeedRockerSts 0 "Not_Pressed" 1 "Not_Used" 2 "Acc+1" 3 "Acc+10" 4 "Not used" 5 "Dec-1" 6 "Dec-10" 7 "Not used" ;
VAL_ 2654339073 DES_ECM 0 "Error_Active_state" 1 "Error_passive_warning_state" 2 "Bus_off_state" 3 "Not_used" ;
VAL_ 2654339073 EOL_ECM 0 "No_EOL_prog_at_FIAT" 1 "EOL_prog_at_FIAT" ;
VAL_ 2654339075 DES_IPC 0 "Error_Active_state" 1 "Error_passive_warning_state" 2 "Bus_off_state" 3 "Not_used" ;
VAL_ 2654339075 EOL_IPC 0 "No_EOL_prog_at_FIAT" 1 "EOL_prog_at_FIAT" ;
VAL_ 2654339137 DES_RFHM 0 "Error_Active_state" 1 "Error_passive_warning_state" 2 "Bus_off_state" 3 "Not_used" ;
VAL_ 2654339137 EOL_RFHM 0 "No_EOL_prog_at_FIAT" 1 "EOL_prog_at_FIAT" ;
VAL_ 2654339107 DES_TBM 0 "Error_Active_state" 1 "Error_passive_warning_state" 2 "Bus_off_state" 3 "Not_used" ;
VAL_ 2654339107 EOL_TBM 0 "No_EOL_prog_at_FIAT" 1 "EOL_prog_at_FIAT" ;
VAL_ 2654339083 DES_Transmission 0 "Error_Active_state" 1 "Error_passive_warning_state" 2 "Bus_off_state" 3 "Not_used" ;
VAL_ 2654339083 EOL_Transmission 0 "No_EOL_prog_at_FIAT" 1 "EOL_prog_at_FIAT" ;
VAL_ 508 ADC_FailSts 0 "Fail_not_present" 1 "Fail_Present" ;
VAL_ 508 ADC_STS 0 "AUTO" 1 "SOFT" 2 "HARD" 3 "SNA" ;
VAL_ 508 CDCM_WarningLamp 0 "Not_Active" 1 "Active" ;
VAL_ 508 Lifter_FailSts 0 "Fail_Not_Present" 1 "Fail_Present" ;
VAL_ 508 LifterCrankReq 0 "Crank_Not_Requested" 1 "Crank_Requested" ;
VAL_ 508 LifterInfoDisplay 0 "DOWN" 1 "MOVING_UP" 2 "UP" 3 "MOVING_DOWN" 4 "INHIBITED" 5 "UNAVAILABLE_ENGINE_OFF" 6 "UNAVAILABLE_SPEED_TOO_HIGH" 7 "UNAVAILABLE_DOOR_OPEN" 8 "UNAVAILABLE_FAIL" 9 "LIFTER_LOWERING_SPEED_TOO_HIGH" 15 "SNA" ;
VAL_ 508 LifterPosition 0 "UNKNOWN" 1 "LIFTER_DOWN" 2 "LIFTER_MOVING_UP" 3 "LIFTER_MOVING_DOWN" 4 "LIFTER_UP" 7 "SNA" ;
VAL_ 508 LifterSts 0 "LIFTER_NORMAL_MODE" 1 "LIFTER_INHIBITED" 2 "LIFTER_FAILURE" 3 "LIFTER_WAITING" 7 "SNA" ;
VAL_ 508 Rear_Diff_Control_Sts 0 "Control_Not_Active" 1 "Control_Active" ;
VAL_ 508 Rear_Diff_WarningLamp 0 "Not_Active" 1 "Active" ;
VAL_ 1454 ChkFuelCap 0 "Not_Detected" 1 "Detected" ;
VAL_ 1454 CompressorSts 0 "Not_Used" 1 "Not_inserted_by_NCM" 2 "Not_insrtd_by_driver_or_security" 3 "Inserted" ;
VAL_ 1454 EMSFailSts 0 "Fail_Not_Present" 1 "Fail_Flash_Light_Indication" 2 "Fail_Fix_Light_Indication" 3 "Flash_For_Service" ;
VAL_ 1454 EngineOperatingMode 0 "Normal" 1 "DPF Regeneration LO" 2 "DPF Regeneration HI" 3 "NSC DeNOx Regeneration" 4 "NSC DeSOx Regeneration" 5 "SCR Heat-up strategy" ;
VAL_ 1454 EngineWaterTempWarningLightSts 0 "OFF" 1 "ON" ;
VAL_ 1454 ETCFailSts 0 "Fail_Not_Present" 1 "Fail_Flash_Light_Indication" 2 "Fail_Fix_Light_Indication" 3 "Flash_For_Service" ;
VAL_ 1454 ExhaustTemperature 255 "SNA" ;
VAL_ 1454 GPFServiceSts 0 "Not_Service" 1 "Service" ;
VAL_ 1454 GPFSts 0 "Clean" 1 "Dirty" ;
VAL_ 1454 OilLifeSts 0 "Normal_Oil_Properties" 1 "Oil_Life_Reset" 2 "Change_Oil_Required" 3 "Not_used" ;
VAL_ 1454 OilPressureFailSts 0 "Fail_Not_Present" 1 "Fail_Present" ;
VAL_ 1454 OilPressureSts 0 "Normal_Pressure" 1 "Low_Pressure" ;
VAL_ 1057 RrAvl_Stat 255 "Invalid" ;
VAL_ 1504 EPB_HMI_Management 0 "No_Ind" 1 "Ind1" 2 "Ind2" 3 "Ind3" 4 "Ind4" 5 "Ind5" 6 "Ind6" 7 "Ind7" 8 "Ind8" 9 "Ind9" 10 "Ind10" 11 "Ind11" 12 "Ind12" 13 "Ind13" 14 "Ind14" 15 "Ind15" 16 "Ind16" 17 "Ind17" 18 "Ind18" 19 "Ind19" 20 "Ind20" 21 "Ind21" 22 "Ind22" 23 "Ind23" 24 "Ind24" 25 "Ind25" 26 "Ind26" 27 "Ind27" 28 "Ind28" 29 "Ind29" 30 "Ind30" 31 "Ind31" ;
VAL_ 1504 EPBAutoAppSts 0 "AutoApply_Disable" 1 "AutoApply_Enable" ;
VAL_ 1504 EPBFailureLampReq 0 "lamp off" 1 "lamp on" ;
VAL_ 1504 EPBMaintenanceSts 0 "Maintenance_Disabled" 1 "Maintenance_Enabled" ;
VAL_ 1504 EPBReleaseIndReq 0 "Release_Ind_Request_Not_Active" 1 "Release_Ind_Request_Active" ;
VAL_ 1504 EPBSts 0 "Released" 1 "Applied" 2 "DynamicBrkESC" 3 "DynamicBrkEPB" 4 "Emergency_Braking" 5 "Applying" 6 "Maintenance_Mode" 7 "Assembly_Check" 8 "Inspection_Mode" 9 "Re_Clamping" 10 "Adjuste_Mode" 11 "Releasing" 12 "Fault_EPB_Released" 13 "Fault_EPB_Applied" 14 "Fault_Present" 15 "SNA" ;
VAL_ 1504 EPBSwitchPosition 0 "No request" 1 "Release request" 2 "Apply request" 3 "Error" ;
VAL_ 1504 FastTransmission_SE 0 "Slow" 1 "Fast" ;
VAL_ 1504 RedLampReq 0 "Off" 1 "Fixed" 2 "Blinking" 3 "SNA" ;
VAL_ 1196 InflationState_LHF_Tyre1 0 "Normal_Tyre_Pressure" 1 "Under_Inflated_Tyre" 2 "SignificantlyUnderInflatedTyre" 3 "Over_Inflated_Tyre" 4 "Sensor_Missing" ;
VAL_ 1196 InflationState_LHR_Tyre1 0 "Normal_Tyre_Pressure" 1 "Under_Inflated_Tyre" 2 "SignificantlyUnderInflatedTyre" 3 "Over_Inflated_Tyre" 4 "Sensor_Missing" ;
VAL_ 1196 InflationState_RHF_Tyre1 0 "Normal_Tyre_Pressure" 1 "Under_Inflated_Tyre" 2 "SignificantlyUnderInflatedTyre" 3 "Over_Inflated_Tyre" 4 "Sensor_Missing" ;
VAL_ 1196 InflationState_RHR_Tyre1 0 "Normal_Tyre_Pressure" 1 "Under_Inflated_Tyre" 2 "SignificantlyUnderInflatedTyre" 3 "Over_Inflated_Tyre" 4 "Sensor_Missing" ;
VAL_ 1196 PressureValue_LHF_Tyre 63 "SNA" ;
VAL_ 1196 PressureValue_LHR_Tyre 63 "SNA" ;
VAL_ 1196 PressureValue_RHF_Tyre 63 "SNA" ;
VAL_ 1196 PressureValue_RHR_Tyre 63 "SNA" ;
VAL_ 1196 TPMActivitySts 0 "TPM_Enabled" 1 "TPM_Disabled" ;
VAL_ 1196 TyrePressureSysProgrammedSts 0 "System_Programmed" 1 "System_Not_Programmed" ;
VAL_ 1196 TyrePressureSystemFailSts1 0 "Fail_Not_Present" 1 "Fail_Present" ;
VAL_ 503 CODE_CLR_TCM 0 "Not_Clear" 1 "Clear" ;
VAL_ 503 FANRequestNCA 0 "Off" 1 "LowSpeed" 2 "highSpeed" 3 "SNA" ;
VAL_ 503 OUTPUT_SPEED 65535 "SNA" ;
VAL_ 503 REPRGD_PFC_CLR_TCM 0 "Do_Nothing" 1 "Set_Incomplete" ;
VAL_ 503 TransmissionTemperature 63 "SNA" ;
VAL_ 503 TransmissionTemperatureFailSts 0 "Fail_not_present" 1 "Fail_present" ;
VAL_ 503 TransReadyForESS 0 "Not_Ready" 1 "Ready" ;
VAL_ 503 TRNS_StpSt_FLT 0 "Not_Present" 1 "Present" ;
VAL_ 236 CutRequest 0 "Inactive" 1 "Cut Request" ;
VAL_ 236 DCTMGbProtectionSpeed 0 "Inactive" 1 "Active" ;
VAL_ 236 DCTMGbProtectionTorque 0 "Inactive" 1 "Active" ;
VAL_ 236 DCTState 0 "DCT_OFF" 1 "DCT_IDLE_INC" 2 "DCT_ADP" 3 "DCT_CLU_CLS" 4 "DCT_DA_CRP" 5 "DCT_DA_LNCH_ARMED" 6 "DCT_DA_LNCH_BRK" 7 "DCT_DA_LNCH_ACTIV" 8 "DCT_DA_LNCH_SYNC" 9 "DCT_DA_PL_PREP" 10 "DCT_DA_PL_ACTIV" 11 "DCT_PWR_US_TQ" 12 "DCT_PWR_US_SPD" 13 "DCT_PWR_US_FIN" 14 "DCT_PWR_DS_SPD" 15 "DCT_PWR_DS_TQ" 16 "DCT_PWR_DS_FIN" 17 "DCT_BRK_US_SPD" 18 "DCT_BRK_US_TQ" 19 "DCT_BRK_US_FIN" 20 "DCT_BRK_DS_TQ" 21 "DCT_BRK_DS_SPD" 22 "DCT_BRK_DS_FIN" 23 "DCT_AMT_US_TQ_RED" 24 "DCT_AMT_US_SPD" 25 "DCT_AMT_US_TQ_UP" 26 "DCT_AMT_DS_TQ_RED" 27 "DCT_AMT_DS_SPD" 28 "DCT_AMT_DS_TQ_UP" 29 "DCT_PWR_N2G_TQ" 30 "DCT_PWR_N2G_SPD" 31 "DCT_BRK_N2G_TQ" 32 "DCT_BRK_N2G_SPD" 33 "DCT_LIM_SPD" 34 "DCT_LIM_TQ" 35 "DCT_LIM_SPD_TQ" 36 "DCT_INVALID" ;
VAL_ 236 EngineSlaveRequest 0 "Inactive" 1 "Slave Mode" ;
VAL_ 236 FutureSyncGear 0 "Neutral" 1 "ForwardGear_1" 2 "ForwardGear_2" 3 "ForwardGear_3" 4 "ForwardGear_4" 5 "ForwardGear_5" 6 "ForwardGear_6" 7 "ForwardGear_7" 8 "ForwardGear_8" 9 "ForwardGear_9" 13 "Parking" 14 "ReverseGear" 15 "SNA" ;
VAL_ 236 FutureSyncRPM 4095 "SNA" ;
VAL_ 236 ReqEngineSpeed 4095 "SNA" ;
VAL_ 236 ReqTorqueValue 2047 "SNA" ;
VAL_ 260 LnchCtrl_TextDisplay 0 "NONE" 1 "TxtMsg_1" 2 "TxtMsg_2" 3 "TxtMsg_3" 4 "TxtMsg_4" 5 "TxtMsg_5" 6 "TxtMsg_6" 7 "TxtMsg_7" 8 "TxtMsg_8" 9 "TxtMsg_9" 10 "TxtMsg_10" 11 "TxtMsg_11" 12 "TxtMsg_12" 13 "TxtMsg_13" 14 "TxtMsg_14" 15 "TxtMsg_15" 16 "TxtMsg_16" 17 "TxtMsg_17" 18 "TxtMsg_18" 19 "TxtMsg_19" 20 "TxtMsg_20" 21 "TxtMsg_21" 22 "TxtMsg_22" 23 "TxtMsg_23" 24 "TxtMsg_24" 25 "TxtMsg_25" 26 "TxtMsg_26" 27 "TxtMsg_27" 28 "TxtMsg_28" 29 "TxtMsg_29" 30 "TxtMsg_30" 31 "SNA" ;
VAL_ 1448 BuzzerReqSts_T2 0 "OFF" 1 "Reverse_Gear_Sound_ON" 2 "Others_case_Sound_ON" 3 "Not_used" ;
VAL_ 1448 CrankEnable 0 "Disabled" 1 "Enabled" ;
VAL_ 1448 DriveModeSts 0 "No_programs_available_selected" 1 "Eco" 2 "Sport" 3 "Not_used" 4 "Ice_Winter" 5 "Tow_Haul" 6 "Track" 7 "4LowMode" 8 "HDC/SSC" 9 "not_used" 10 "not_used" 11 "not_used" 12 "not_used" 13 "not_used" 14 "not_used" 15 "not_used" ;
VAL_ 1448 GearEngaged 0 "Neutral" 1 "ForwardGear_1" 2 "ForwardGear_2" 3 "ForwardGear_3" 4 "ForwardGear_4" 5 "ForwardGear_5" 6 "ForwardGear_6" 7 "ForwardGear_7" 8 "ForwardGear_8" 9 "ForwardGear_9" 13 "Parking" 14 "ReverseGear" 15 "SNA" ;
VAL_ 1448 GearIndicationSts 0 "Normal" 1 "Blinking" ;
VAL_ 1448 LeverPosition 0 "No_Selection_Active_Or_Available" 1 "P" 2 "R" 3 "N" 4 "D" 5 "L" 6 "TIP_Autostick" 7 "Plus" 8 "Minus" 9 "Sport" 10 "Not_Used" 11 "Not_Used" 12 "Not_Used" 13 "Not_Used" 14 "Not_Used" 15 "SNA" ;
VAL_ 1448 LimpHomeSts 0 "NotActive" 1 "Active" ;
VAL_ 1448 MIReq 0 "No_EOBD_error" 1 "EOBD_error" ;
VAL_ 1448 OilTemperatureSts 0 "Normal" 1 "High" ;
VAL_ 1448 ParkingFailSts 0 "Fail_not_present" 1 "Fail_present" ;
VAL_ 1448 ShiftInProgress 0 "No Shift in progress" 1 "Shift in progress" ;
VAL_ 1448 ShiftLeverPosition 0 "No_Selection_Active_Or_Available" 1 "P" 2 "R" 3 "N" 4 "D" 5 "L" 6 "TIP_Autostick" 7 "Plus" 8 "Minus" 9 "Sport" 10 "Not_Used" 11 "Not_Used" 12 "Not_Used" 13 "Not_Used" 14 "Not_Used" 15 "SNA" ;
VAL_ 1448 ShiftModeSts 0 "Manual" 1 "Automatic" ;
VAL_ 1448 TargetGear 0 "Neutral" 1 "ForwardGear_1" 2 "ForwardGear_2" 3 "ForwardGear_3" 4 "ForwardGear_4" 5 "ForwardGear_5" 6 "ForwardGear_6" 7 "ForwardGear_7" 8 "ForwardGear_8" 9 "ForwardGear_9" 13 "Parking" 14 "ReverseGear" 15 "SNA" ;
VAL_ 1448 TempManualOverride 0 "Inactive" 1 "Active" ;
VAL_ 1448 TemporaryManualSts 0 "Not_Active" 1 "Active" ;
VAL_ 1448 TransmissionFailSts 0 "Fail_not_present" 1 "Fail_present" ;
VAL_ 1448 TransmissionWarnings 0 "No_Warning" 1 "Press_Brake_Pedal" 2 "Tip_Not_Available" 3 "Lower_Gear_Shifts" 4 "Manual_Mode_Not_Available" 5 "Insert_N" 6 "Automatic_Mode_Not_Available" 7 "Press_Brake_Delayed_Startup_Warning" 8 "Clutch_Overtemperature" 9 "Manoeuvre_Not_Allowed" 10 "Press_Brake_Pedal_Repeat" 11 "Gear_Not_Available" 12 "Shift_Not_Allowed" 13 "Shift_to_Neutral_Then_DR" 14 "Reduce_Gear_Changes" 15 "Clutch_Overheater_Must_Cool" 16 "Service_Transmission" 17 "Service_Shifter" 18 "Engage_Park_Brake" 19 "Trans_Too_Cold_Pls_Wait" 20 "Push_Button_to_Shift" 21 "Return_Shifter_To_Home" 22 "Press_Brake_Push_Button_Shift" 23 "Service_Trans_Shut_Off" 24 "Already_in_Des_Gear" 25 "Start_Engine_to_Shift" 26 "Service_Trans_Use_Pk_Brk" 27 "Vehicle_Speed_Too_High" 28 "Tow_Haul_Not_available" 29 "Tow_Haul_Disengaged" 30 "Trans_Cool_Ready_to_Drive" 31 "Vehicle_Speed_Too_High_to_Shift_P" 32 "Vehicle_Speed_Too_High_to_Shift_R" 33 "Vehicle_Speed_Too_High_to_Shift_D" 34 "Manual_Shift_Temp_Not_Available" 35 "Vehicle_Speed_Too_High_to_Shift_L/S" 36 "Shift_to_Park_to_ obtain_drivability" 37 "Shift_to_Park_to_Start" 38 "APCM_in_Progress" 39 "Stop Vehicle to Shift" 40 "Service Transmission_Stop Vehicle to Shift " 41 "Service Transmission__Stop Vehicle_Restart Vehicle in P to Continue Driving" 42 "Service Transmission_Stop Vehicle to Shift _Restart Vehicle in P to Continue Driving" 43 "Press Brake To Prevent Vehicle From Rolling" 45 "Trans_Recover_Mode_Warning" 46 "Washing_Active" 47 "To_Select_Gear_Press_Brake_And_Unlock_Button" 48 "To_Select_Forward_Gear press brake_And_Unlock_Button" 49 "To_Select_Forward_Gear_Press_Brake" 50 "To_Select_Reverse_Gear_Press_Brake_And_Unlock button" 51 "To_Select_Reverse_Gear_Press_Brake" 52 "To_Select_Reverse_Gear_Press_Unlock_Button" 53 "Vehicle_Not_In_Park" 54 "Paddles_Not_Available" 55 "Service_Shifter_PButton_Not_Available" 56 "Service_Shifter_Unlock_Button_Not_Available" 57 "Lever_Out_Of_Position" 58 "Exit_Of_Washing" ;
VAL_ 1448 TxDisengaged 0 "Engaged" 1 "Disengaged" ;
VAL_ 234 ActiveGearRatio 255 "SNA" ;
VAL_ 234 AMTIndex 127 "SNA" ;
VAL_ 234 ClutchStatus 0 "Open" 1 "Slip" 2 "Mslip" 3 "Closed" ;
VAL_ 234 CutOffTime 255 "SNA" ;
VAL_ 234 ESPReqFulfillDCTM 0 "False" 1 "True" ;
VAL_ 234 GearBoxAbsorption 63 "SNA" ;
VAL_ 234 LaunchActive 0 "IDLE" 1 "DriverRq" 2 "Confirmed" 3 "BrakePressed" 4 "FullThrottle" 5 "Active" 6 "Inactive" ;
VAL_ 234 ReqSlowTorqueValue 2047 "SNA" ;
VAL_ 234 SpeedReqType 0 "Max_limit" 1 "Target" 2 "Min_limit" ;
VAL_ 234 TorqueReqType 0 "Torque_increase" 1 "Torque_decrease" ;
VAL_ 253 CodeCheckSts_TRM 0 "No_Code" 1 "CodeCheck_OK" 2 "CodeCheck_Fault" 3 "Not_Used" ;
VAL_ 253 ProgrammedSts_TRM 0 "Not_Programmed" 1 "Programmed" ;
VAL_ 253 TxpFound 0 "Transponder_Read" 1 "Transponder_Absent" ;
VAL_ 253 TxpID 0 "Transponder_Not_Authenticated" 1 "Transponder_1_Authenticated" 2 "Transponder_2_Authenticated" 3 "Transponder_3_Authenticated" 4 "Transponder_4_Authenticated" 5 "Transponder_5_Authenticated" 6 "Transponder_6_Authenticated" 7 "Transponder_7_Authenticated" 8 "Transponder_8_Authenticated" 9 "Transponder_9_Authenticated" 10 "Transponder_10_Authenticated" 11 "Transponder_11_Authenticated" 12 "Transponder_12_Authenticated" 13 "Transponder_13_Authenticated" 14 "Transponder_14_Authenticated" 15 "Transponder_15_Authenticated" ;
VAL_ 243 FrameNumber 0 "Frame_1" 1 "Frame_2" 2 "Frame_3" 3 "Frame_4" 4 "Frame_5" 5 "Frame_6" 6 "Frame_7" 7 "Frame_8" 8 "Frame_9" 9 "Frame_10" 10 "Frame_11" 11 "Frame_12" 12 "Frame_13" 13 "Frame_14" 14 "Frame_15" 15 "Frame_16" ;
VAL_ 243 TotalFrameNumber 0 "One_Frame" 1 "Two_Frames" 2 "Three_Frames" 3 "Four_Frames" 4 "Five_Frames" 5 "Six_Frames" 6 "Seven_Frames" 7 "Eight_Frame" 8 "Nine_Frames" 9 "Ten_Frames" 10 "Eleven_Frames" 11 "Twelve_Frames" 12 "Thirteen_Frames" 13 "Fourteen_Frames" 14 "Fifteen_Frames" 15 "Sixteen_Frames" ;
VAL_ 1046 VIN_MSG 0 "VIN_LO" 1 "VIN_MID" 2 "VIN_HI" 3 "SNA" ;
VAL_ 2654208000 MainWakeSts_BCM 0 "Not_Active" 1 "Active" ;
VAL_ 2654208000 Node0 0 "Not_active" 1 "Active" ;
VAL_ 2654208000 Node1 0 "Not_active" 1 "Active" ;
VAL_ 2654208000 Node10 0 "Not_active" 1 "Active" ;
VAL_ 2654208000 Node11 0 "Not_active" 1 "Active" ;
VAL_ 2654208000 Node12 0 "Not_active" 1 "Active" ;
VAL_ 2654208000 Node13 0 "Not_active" 1 "Active" ;
VAL_ 2654208000 Node14 0 "Not_active" 1 "Active" ;
VAL_ 2654208000 Node15 0 "Not_active" 1 "Active" ;
VAL_ 2654208000 Node16 0 "Not_active" 1 "Active" ;
VAL_ 2654208000 Node17 0 "Not_active" 1 "Active" ;
VAL_ 2654208000 Node18 0 "Not_active" 1 "Active" ;
VAL_ 2654208000 Node19 0 "Not_active" 1 "Active" ;
VAL_ 2654208000 Node2 0 "Not_active" 1 "Active" ;
VAL_ 2654208000 Node20 0 "Not_active" 1 "Active" ;
VAL_ 2654208000 Node21 0 "Not_active" 1 "Active" ;
VAL_ 2654208000 Node22 0 "Not_active" 1 "Active" ;
VAL_ 2654208000 Node23 0 "Not_active" 1 "Active" ;
VAL_ 2654208000 Node24 0 "Not_active" 1 "Active" ;
VAL_ 2654208000 Node25 0 "Not_active" 1 "Active" ;
VAL_ 2654208000 Node26 0 "Not_active" 1 "Active" ;
VAL_ 2654208000 Node27 0 "Not_active" 1 "Active" ;
VAL_ 2654208000 Node28 0 "Not_active" 1 "Active" ;
VAL_ 2654208000 Node29 0 "Not_active" 1 "Active" ;
VAL_ 2654208000 Node3 0 "Not_active" 1 "Active" ;
VAL_ 2654208000 Node30 0 "Not_active" 1 "Active" ;
VAL_ 2654208000 Node31 0 "Not_active" 1 "Active" ;
VAL_ 2654208000 Node4 0 "Not_active" 1 "Active" ;
VAL_ 2654208000 Node5 0 "Not_active" 1 "Active" ;
VAL_ 2654208000 Node6 0 "Not_active" 1 "Active" ;
VAL_ 2654208000 Node7 0 "Not_active" 1 "Active" ;
VAL_ 2654208000 Node8 0 "Not_active" 1 "Active" ;
VAL_ 2654208000 Node9 0 "Not_active" 1 "Active" ;
VAL_ 2654208000 WakeRsn_BCM 0 "Diag" 1 "Network" 2 "WakeRsn2" 3 "WakeRsn3" 4 "WakeRsn4" 5 "WakeRsn5" 6 "WakeRsn6" 7 "WakeRsn7" 8 "WakeRsn8" 9 "WakeRsn9" 10 "WakeRsn10" 11 "WakeRsn11" 12 "WakeRsn12" 13 "WakeRsn13" 14 "WakeRsn14" 15 "WakeRsn15" 16 "WakeRsn16" 17 "WakeRsn17" 18 "WakeRsn18" 19 "WakeRsn19" 20 "WakeRsn20" 21 "WakeRsn21" 22 "WakeRsn22" 23 "WakeRsn23" 24 "WakeRsn24" 25 "WakeRsn25" 26 "WakeRsn26" 27 "WakeRsn27" 28 "WakeRsn28" 29 "WakeRsn29" 30 "WakeRsn30" 31 "WakeRsn31" 32 "WakeRsn32" 33 "WakeRsn33" 34 "WakeRsn34" 35 "WakeRsn35" 36 "WakeRsn36" 37 "WakeRsn37" 38 "WakeRsn38" 39 "WakeRsn39" 40 "WakeRsn40" 41 "WakeRsn41" 42 "WakeRsn42" 43 "WakeRsn43" 44 "WakeRsn44" 45 "WakeRsn45" 46 "WakeRsn46" 47 "WakeRsn47" 48 "WakeRsn48" 49 "WakeRsn49" 50 "WakeRsn50" 51 "WakeRsn51" 52 "WakeRsn52" 53 "WakeRsn53" 54 "WakeRsn54" 55 "WakeRsn55" 56 "WakeRsn56" 57 "WakeRsn57" 58 "WakeRsn58" 59 "WakeRsn59" 60 "WakeRsn60" 61 "WakeRsn61" 62 "WakeRsn62" 63 "WakeRsn63" 64 "WakeRsn64" 65 "WakeRsn65" 66 "WakeRsn66" 67 "WakeRsn67" 68 "WakeRsn68" 69 "WakeRsn69" 70 "WakeRsn70" 71 "WakeRsn71" 72 "WakeRsn72" 73 "WakeRsn73" 74 "WakeRsn74" 75 "WakeRsn75" 76 "WakeRsn76" 77 "WakeRsn77" 78 "WakeRsn78" 79 "WakeRsn79" 80 "WakeRsn80" 81 "WakeRsn81" 82 "WakeRsn82" 83 "WakeRsn83" 84 "WakeRsn84" 85 "WakeRsn85" 86 "WakeRsn86" 87 "WakeRsn87" 88 "WakeRsn88" 89 "WakeRsn89" 90 "WakeRsn90" 91 "WakeRsn91" 92 "WakeRsn92" 93 "WakeRsn93" 94 "WakeRsn94" 95 "WakeRsn95" 96 "WakeRsn96" 97 "WakeRsn97" 98 "WakeRsn98" 99 "WakeRsn99" 100 "WakeRsn100" 101 "WakeRsn101" 102 "WakeRsn102" 103 "WakeRsn103" 104 "WakeRsn104" 105 "WakeRsn105" 106 "WakeRsn106" 107 "WakeRsn107" 108 "WakeRsn108" 109 "WakeRsn109" 110 "WakeRsn110" 111 "WakeRsn111" 112 "WakeRsn112" 113 "WakeRsn113" 114 "WakeRsn114" 115 "WakeRsn115" 116 "WakeRsn116" 117 "WakeRsn117" 118 "WakeRsn118" 119 "WakeRsn119" 120 "WakeRsn120" 121 "WakeRsn121" 122 "WakeRsn122" 123 "WakeRsn123" 124 "WakeRsn124" 125 "WakeRsn125" 126 "WakeRsn126" 127 "WakeRsn127" ;
VAL_ 2654208006 WakeReq_BSM 0 "NotActive" 1 "Active" ;
VAL_ 2654208006 WakeRsn_BSM 0 "Diag" 1 "Network" 2 "WakeRsn2" 3 "WakeRsn3" 4 "WakeRsn4" 5 "WakeRsn5" 6 "WakeRsn6" 7 "WakeRsn7" 8 "WakeRsn8" 9 "WakeRsn9" 10 "WakeRsn10" 11 "WakeRsn11" 12 "WakeRsn12" 13 "WakeRsn13" 14 "WakeRsn14" 15 "WakeRsn15" 16 "WakeRsn16" 17 "WakeRsn17" 18 "WakeRsn18" 19 "WakeRsn19" 20 "WakeRsn20" 21 "WakeRsn21" 22 "WakeRsn22" 23 "WakeRsn23" 24 "WakeRsn24" 25 "WakeRsn25" 26 "WakeRsn26" 27 "WakeRsn27" 28 "WakeRsn28" 29 "WakeRsn29" 30 "WakeRsn30" 31 "WakeRsn31" 32 "WakeRsn32" 33 "WakeRsn33" 34 "WakeRsn34" 35 "WakeRsn35" 36 "WakeRsn36" 37 "WakeRsn37" 38 "WakeRsn38" 39 "WakeRsn39" 40 "WakeRsn40" 41 "WakeRsn41" 42 "WakeRsn42" 43 "WakeRsn43" 44 "WakeRsn44" 45 "WakeRsn45" 46 "WakeRsn46" 47 "WakeRsn47" 48 "WakeRsn48" 49 "WakeRsn49" 50 "WakeRsn50" 51 "WakeRsn51" 52 "WakeRsn52" 53 "WakeRsn53" 54 "WakeRsn54" 55 "WakeRsn55" 56 "WakeRsn56" 57 "WakeRsn57" 58 "WakeRsn58" 59 "WakeRsn59" 60 "WakeRsn60" 61 "WakeRsn61" 62 "WakeRsn62" 63 "WakeRsn63" 64 "WakeRsn64" 65 "WakeRsn65" 66 "WakeRsn66" 67 "WakeRsn67" 68 "WakeRsn68" 69 "WakeRsn69" 70 "WakeRsn70" 71 "WakeRsn71" 72 "WakeRsn72" 73 "WakeRsn73" 74 "WakeRsn74" 75 "WakeRsn75" 76 "WakeRsn76" 77 "WakeRsn77" 78 "WakeRsn78" 79 "WakeRsn79" 80 "WakeRsn80" 81 "WakeRsn81" 82 "WakeRsn82" 83 "WakeRsn83" 84 "WakeRsn84" 85 "WakeRsn85" 86 "WakeRsn86" 87 "WakeRsn87" 88 "WakeRsn88" 89 "WakeRsn89" 90 "WakeRsn90" 91 "WakeRsn91" 92 "WakeRsn92" 93 "WakeRsn93" 94 "WakeRsn94" 95 "WakeRsn95" 96 "WakeRsn96" 97 "WakeRsn97" 98 "WakeRsn98" 99 "WakeRsn99" 100 "WakeRsn100" 101 "WakeRsn101" 102 "WakeRsn102" 103 "WakeRsn103" 104 "WakeRsn104" 105 "WakeRsn105" 106 "WakeRsn106" 107 "WakeRsn107" 108 "WakeRsn108" 109 "WakeRsn109" 110 "WakeRsn110" 111 "WakeRsn111" 112 "WakeRsn112" 113 "WakeRsn113" 114 "WakeRsn114" 115 "WakeRsn115" 116 "WakeRsn116" 117 "WakeRsn117" 118 "WakeRsn118" 119 "WakeRsn119" 120 "WakeRsn120" 121 "WakeRsn121" 122 "WakeRsn122" 123 "WakeRsn123" 124 "WakeRsn124" 125 "WakeRsn125" 126 "WakeRsn126" 127 "WakeRsn127" ;
VAL_ 2654208003 WakeReq_IPC 0 "NotActive" 1 "Active" ;
VAL_ 2654208003 WakeRsn_IPC 0 "Diag" 1 "Network" 2 "WakeRsn2" 3 "WakeRsn3" 4 "WakeRsn4" 5 "WakeRsn5" 6 "WakeRsn6" 7 "WakeRsn7" 8 "WakeRsn8" 9 "WakeRsn9" 10 "WakeRsn10" 11 "WakeRsn11" 12 "WakeRsn12" 13 "WakeRsn13" 14 "WakeRsn14" 15 "WakeRsn15" 16 "WakeRsn16" 17 "WakeRsn17" 18 "WakeRsn18" 19 "WakeRsn19" 20 "WakeRsn20" 21 "WakeRsn21" 22 "WakeRsn22" 23 "WakeRsn23" 24 "WakeRsn24" 25 "WakeRsn25" 26 "WakeRsn26" 27 "WakeRsn27" 28 "WakeRsn28" 29 "WakeRsn29" 30 "WakeRsn30" 31 "WakeRsn31" 32 "WakeRsn32" 33 "WakeRsn33" 34 "WakeRsn34" 35 "WakeRsn35" 36 "WakeRsn36" 37 "WakeRsn37" 38 "WakeRsn38" 39 "WakeRsn39" 40 "WakeRsn40" 41 "WakeRsn41" 42 "WakeRsn42" 43 "WakeRsn43" 44 "WakeRsn44" 45 "WakeRsn45" 46 "WakeRsn46" 47 "WakeRsn47" 48 "WakeRsn48" 49 "WakeRsn49" 50 "WakeRsn50" 51 "WakeRsn51" 52 "WakeRsn52" 53 "WakeRsn53" 54 "WakeRsn54" 55 "WakeRsn55" 56 "WakeRsn56" 57 "WakeRsn57" 58 "WakeRsn58" 59 "WakeRsn59" 60 "WakeRsn60" 61 "WakeRsn61" 62 "WakeRsn62" 63 "WakeRsn63" 64 "WakeRsn64" 65 "WakeRsn65" 66 "WakeRsn66" 67 "WakeRsn67" 68 "WakeRsn68" 69 "WakeRsn69" 70 "WakeRsn70" 71 "WakeRsn71" 72 "WakeRsn72" 73 "WakeRsn73" 74 "WakeRsn74" 75 "WakeRsn75" 76 "WakeRsn76" 77 "WakeRsn77" 78 "WakeRsn78" 79 "WakeRsn79" 80 "WakeRsn80" 81 "WakeRsn81" 82 "WakeRsn82" 83 "WakeRsn83" 84 "WakeRsn84" 85 "WakeRsn85" 86 "WakeRsn86" 87 "WakeRsn87" 88 "WakeRsn88" 89 "WakeRsn89" 90 "WakeRsn90" 91 "WakeRsn91" 92 "WakeRsn92" 93 "WakeRsn93" 94 "WakeRsn94" 95 "WakeRsn95" 96 "WakeRsn96" 97 "WakeRsn97" 98 "WakeRsn98" 99 "WakeRsn99" 100 "WakeRsn100" 101 "WakeRsn101" 102 "WakeRsn102" 103 "WakeRsn103" 104 "WakeRsn104" 105 "WakeRsn105" 106 "WakeRsn106" 107 "WakeRsn107" 108 "WakeRsn108" 109 "WakeRsn109" 110 "WakeRsn110" 111 "WakeRsn111" 112 "WakeRsn112" 113 "WakeRsn113" 114 "WakeRsn114" 115 "WakeRsn115" 116 "WakeRsn116" 117 "WakeRsn117" 118 "WakeRsn118" 119 "WakeRsn119" 120 "WakeRsn120" 121 "WakeRsn121" 122 "WakeRsn122" 123 "WakeRsn123" 124 "WakeRsn124" 125 "WakeRsn125" 126 "WakeRsn126" 127 "WakeRsn127" ;
VAL_ 2654208065 WakeReq_RFHM 0 "NotActive" 1 "Active" ;
VAL_ 2654208065 WakeRsn_RFHM 0 "Diag" 1 "Network" 2 "WakeRsn2" 3 "WakeRsn3" 4 "WakeRsn4" 5 "WakeRsn5" 6 "WakeRsn6" 7 "WakeRsn7" 8 "WakeRsn8" 9 "WakeRsn9" 10 "WakeRsn10" 11 "WakeRsn11" 12 "WakeRsn12" 13 "WakeRsn13" 14 "WakeRsn14" 15 "WakeRsn15" 16 "WakeRsn16" 17 "WakeRsn17" 18 "WakeRsn18" 19 "WakeRsn19" 20 "WakeRsn20" 21 "WakeRsn21" 22 "WakeRsn22" 23 "WakeRsn23" 24 "WakeRsn24" 25 "WakeRsn25" 26 "WakeRsn26" 27 "WakeRsn27" 28 "WakeRsn28" 29 "WakeRsn29" 30 "WakeRsn30" 31 "WakeRsn31" 32 "WakeRsn32" 33 "WakeRsn33" 34 "WakeRsn34" 35 "WakeRsn35" 36 "WakeRsn36" 37 "WakeRsn37" 38 "WakeRsn38" 39 "WakeRsn39" 40 "WakeRsn40" 41 "WakeRsn41" 42 "WakeRsn42" 43 "WakeRsn43" 44 "WakeRsn44" 45 "WakeRsn45" 46 "WakeRsn46" 47 "WakeRsn47" 48 "WakeRsn48" 49 "WakeRsn49" 50 "WakeRsn50" 51 "WakeRsn51" 52 "WakeRsn52" 53 "WakeRsn53" 54 "WakeRsn54" 55 "WakeRsn55" 56 "WakeRsn56" 57 "WakeRsn57" 58 "WakeRsn58" 59 "WakeRsn59" 60 "WakeRsn60" 61 "WakeRsn61" 62 "WakeRsn62" 63 "WakeRsn63" 64 "WakeRsn64" 65 "WakeRsn65" 66 "WakeRsn66" 67 "WakeRsn67" 68 "WakeRsn68" 69 "WakeRsn69" 70 "WakeRsn70" 71 "WakeRsn71" 72 "WakeRsn72" 73 "WakeRsn73" 74 "WakeRsn74" 75 "WakeRsn75" 76 "WakeRsn76" 77 "WakeRsn77" 78 "WakeRsn78" 79 "WakeRsn79" 80 "WakeRsn80" 81 "WakeRsn81" 82 "WakeRsn82" 83 "WakeRsn83" 84 "WakeRsn84" 85 "WakeRsn85" 86 "WakeRsn86" 87 "WakeRsn87" 88 "WakeRsn88" 89 "WakeRsn89" 90 "WakeRsn90" 91 "WakeRsn91" 92 "WakeRsn92" 93 "WakeRsn93" 94 "WakeRsn94" 95 "WakeRsn95" 96 "WakeRsn96" 97 "WakeRsn97" 98 "WakeRsn98" 99 "WakeRsn99" 100 "WakeRsn100" 101 "WakeRsn101" 102 "WakeRsn102" 103 "WakeRsn103" 104 "WakeRsn104" 105 "WakeRsn105" 106 "WakeRsn106" 107 "WakeRsn107" 108 "WakeRsn108" 109 "WakeRsn109" 110 "WakeRsn110" 111 "WakeRsn111" 112 "WakeRsn112" 113 "WakeRsn113" 114 "WakeRsn114" 115 "WakeRsn115" 116 "WakeRsn116" 117 "WakeRsn117" 118 "WakeRsn118" 119 "WakeRsn119" 120 "WakeRsn120" 121 "WakeRsn121" 122 "WakeRsn122" 123 "WakeRsn123" 124 "WakeRsn124" 125 "WakeRsn125" 126 "WakeRsn126" 127 "WakeRsn127" ;
VAL_ 2654208011 WakeReq_Transmission 0 "NotActive" 1 "Active" ;
VAL_ 2654208011 WakeRsn_Transmission 0 "Diag" 1 "Network" 2 "WakeRsn2" 3 "WakeRsn3" 4 "WakeRsn4" 5 "WakeRsn5" 6 "WakeRsn6" 7 "WakeRsn7" 8 "WakeRsn8" 9 "WakeRsn9" 10 "WakeRsn10" 11 "WakeRsn11" 12 "WakeRsn12" 13 "WakeRsn13" 14 "WakeRsn14" 15 "WakeRsn15" 16 "WakeRsn16" 17 "WakeRsn17" 18 "WakeRsn18" 19 "WakeRsn19" 20 "WakeRsn20" 21 "WakeRsn21" 22 "WakeRsn22" 23 "WakeRsn23" 24 "WakeRsn24" 25 "WakeRsn25" 26 "WakeRsn26" 27 "WakeRsn27" 28 "WakeRsn28" 29 "WakeRsn29" 30 "WakeRsn30" 31 "WakeRsn31" 32 "WakeRsn32" 33 "WakeRsn33" 34 "WakeRsn34" 35 "WakeRsn35" 36 "WakeRsn36" 37 "WakeRsn37" 38 "WakeRsn38" 39 "WakeRsn39" 40 "WakeRsn40" 41 "WakeRsn41" 42 "WakeRsn42" 43 "WakeRsn43" 44 "WakeRsn44" 45 "WakeRsn45" 46 "WakeRsn46" 47 "WakeRsn47" 48 "WakeRsn48" 49 "WakeRsn49" 50 "WakeRsn50" 51 "WakeRsn51" 52 "WakeRsn52" 53 "WakeRsn53" 54 "WakeRsn54" 55 "WakeRsn55" 56 "WakeRsn56" 57 "WakeRsn57" 58 "WakeRsn58" 59 "WakeRsn59" 60 "WakeRsn60" 61 "WakeRsn61" 62 "WakeRsn62" 63 "WakeRsn63" 64 "WakeRsn64" 65 "WakeRsn65" 66 "WakeRsn66" 67 "WakeRsn67" 68 "WakeRsn68" 69 "WakeRsn69" 70 "WakeRsn70" 71 "WakeRsn71" 72 "WakeRsn72" 73 "WakeRsn73" 74 "WakeRsn74" 75 "WakeRsn75" 76 "WakeRsn76" 77 "WakeRsn77" 78 "WakeRsn78" 79 "WakeRsn79" 80 "WakeRsn80" 81 "WakeRsn81" 82 "WakeRsn82" 83 "WakeRsn83" 84 "WakeRsn84" 85 "WakeRsn85" 86 "WakeRsn86" 87 "WakeRsn87" 88 "WakeRsn88" 89 "WakeRsn89" 90 "WakeRsn90" 91 "WakeRsn91" 92 "WakeRsn92" 93 "WakeRsn93" 94 "WakeRsn94" 95 "WakeRsn95" 96 "WakeRsn96" 97 "WakeRsn97" 98 "WakeRsn98" 99 "WakeRsn99" 100 "WakeRsn100" 101 "WakeRsn101" 102 "WakeRsn102" 103 "WakeRsn103" 104 "WakeRsn104" 105 "WakeRsn105" 106 "WakeRsn106" 107 "WakeRsn107" 108 "WakeRsn108" 109 "WakeRsn109" 110 "WakeRsn110" 111 "WakeRsn111" 112 "WakeRsn112" 113 "WakeRsn113" 114 "WakeRsn114" 115 "WakeRsn115" 116 "WakeRsn116" 117 "WakeRsn117" 118 "WakeRsn118" 119 "WakeRsn119" 120 "WakeRsn120" 121 "WakeRsn121" 122 "WakeRsn122" 123 "WakeRsn123" 124 "WakeRsn124" 125 "WakeRsn125" 126 "WakeRsn126" 127 "WakeRsn127" ;
VAL_ 278 LHF_FastPulseCounter 255 "SNA" ;
VAL_ 278 LHF_Spin 0 "Stand_Still" 1 "Forward" 2 "Backward" 3 "SNA" ;
VAL_ 278 LHF_WheelSensorFailSts 0 "Fail_Not_Present" 1 "Fail_Present" ;
VAL_ 278 LHR_FastPulseCounter 255 "SNA" ;
VAL_ 278 LHR_Spin 0 "Stand_Still" 1 "Forward" 2 "Backward" 3 "SNA" ;
VAL_ 278 LHR_WheelSensorFailSts 0 "Fail_Not_Present" 1 "Fail_Present" ;
VAL_ 278 RHF_FastPulseCounter 255 "SNA" ;
VAL_ 278 RHF_Spin 0 "Stand_Still" 1 "Forward" 2 "Backward" 3 "SNA" ;
VAL_ 278 RHF_WheelSensorFailSts 0 "Fail_Not_Present" 1 "Fail_Present" ;
VAL_ 278 RHR_FastPulseCounter 255 "SNA" ;
VAL_ 278 RHR_Spin 0 "Stand_Still" 1 "Forward" 2 "Backward" 3 "SNA" ;
VAL_ 278 RHR_WheelSensorFailSts 0 "Fail_Not_Present" 1 "Fail_Present" ;
VAL_ 238 LHFWheelSpeed 8191 "SNA" ;
VAL_ 238 LHRWheelSpeed 8191 "SNA" ;
VAL_ 238 RHFWheelSpeed 8191 "SNA" ;
VAL_ 238 RHRWheelSpeed 8191 "SNA" ;
